VERSION "eCMPilot HS1 database-first 2026-10-28; PSA-RE 67f7581e7622410efdbb29c7eda3b86982b9b450; Apache-2.0"

NS_ :

BS_:

BU_: AAS ABS ARTIV AVAS BCP BSI BSM BVA CAV CMM CSS CVM DAE DMTR ESM E_VCU HCU1 HCU2 LVNSD MCM MDS RBG SBW VCU

BO_ 1293 ABS_BrakeAbrStatus: 8 ABS
 SG_ BrakeEcuFrame5Checksum : 59|4@0+ (1,0) [0|15] ""  AAS,CVM,DAE,CMM,BVA,BSI,HCU1,BSM,VCU,E_VCU
 SG_ ProcessCounter50d : 63|4@0+ (1,0) [0|15] ""  AAS,CVM,DAE,CMM,BVA,BSI,HCU1,BSM,VCU,E_VCU
 SG_ EspDisconnectRequest : 48|1@0+ (1,0) [0|1] ""  AAS,CVM,DAE,CMM,BVA,BSI,HCU1,BSM,VCU,E_VCU
 SG_ BrakeAssistFaultLampRequest : 49|1@0+ (1,0) [0|1] ""  AAS,CVM,DAE,CMM,BVA,BSI,HCU1,BSM,VCU,E_VCU
 SG_ StaticSlopeState : 51|2@0+ (1,0) [0|3] ""  AAS,CVM,DAE,CMM,BVA,BSI,HCU1,BSM,VCU,E_VCU
 SG_ BrakeFunctionNeedForStartStop : 53|2@0+ (1,0) [0|3] ""  AAS,CVM,DAE,CMM,BVA,BSI,HCU1,BSM,VCU,E_VCU
 SG_ BrakeEcuPowerManagementFault : 54|1@0+ (1,0) [0|1] ""  AAS,CVM,DAE,CMM,BVA,BSI,HCU1,BSM,VCU,E_VCU
 SG_ EmergencyBrakingSignaliza_517ee3 : 55|1@0+ (1,0) [0|1] ""  AAS,CVM,DAE,CMM,BVA,BSI,HCU1,BSM,VCU,E_VCU
 SG_ BrakeEcuSupplyVoltage : 47|8@0+ (0.05,7) [7|18.5] "V"  AAS,CVM,DAE,CMM,BVA,BSI,HCU1,BSM,VCU,E_VCU
 SG_ RearRightWheelSpinCounter : 30|15@0+ (1,0) [0|32767] ""  AAS,CVM,DAE,CMM,BVA,BSI,HCU1,BSM,VCU,E_VCU
 SG_ RearRightWheelSpeedSensorFault : 31|1@0+ (1,0) [0|1] ""  AAS,CVM,DAE,CMM,BVA,BSI,HCU1,BSM,VCU,E_VCU
 SG_ RearLeftWheelSpinCounter : 14|15@0+ (1,0) [0|32767] ""  AAS,CVM,DAE,CMM,BVA,BSI,HCU1,BSM,VCU,E_VCU
 SG_ RearLeftWheelSpeedSensorFault : 15|1@0+ (1,0) [0|1] ""  AAS,CVM,DAE,CMM,BVA,BSI,HCU1,BSM,VCU,E_VCU
 SG_ AbsFaultLampRequest : 0|1@0+ (1,0) [0|1] ""  AAS,CVM,DAE,CMM,BVA,BSI,HCU1,BSM,VCU,E_VCU
 SG_ BrakeFluidLevelAlert : 1|1@0+ (1,0) [0|1] ""  AAS,CVM,DAE,CMM,BVA,BSI,HCU1,BSM,VCU,E_VCU
 SG_ WornBrakePadsIndicator : 2|1@0+ (1,0) [0|1] ""  AAS,CVM,DAE,CMM,BVA,BSI,HCU1,BSM,VCU,E_VCU
 SG_ RefInProgress : 3|1@0+ (1,0) [0|1] ""  AAS,CVM,DAE,CMM,BVA,BSI,HCU1,BSM,VCU,E_VCU
 SG_ AutomaticHazardLightsByUcBrake : 4|1@0+ (1,0) [0|1] ""  AAS,CVM,DAE,CMM,BVA,BSI,HCU1,BSM,VCU,E_VCU
 SG_ AbsInProgress : 5|1@0+ (1,0) [0|1] ""  AAS,CVM,DAE,CMM,BVA,BSI,HCU1,BSM,VCU,E_VCU
 SG_ Unused1 : 6|1@0+ (1,0) [0|1] ""  AAS,CVM,DAE,CMM,BVA,BSI,HCU1,BSM,VCU,E_VCU
 SG_ RefFaultLamp : 7|1@0+ (1,0) [0|1] ""  AAS,CVM,DAE,CMM,BVA,BSI,HCU1,BSM,VCU,E_VCU

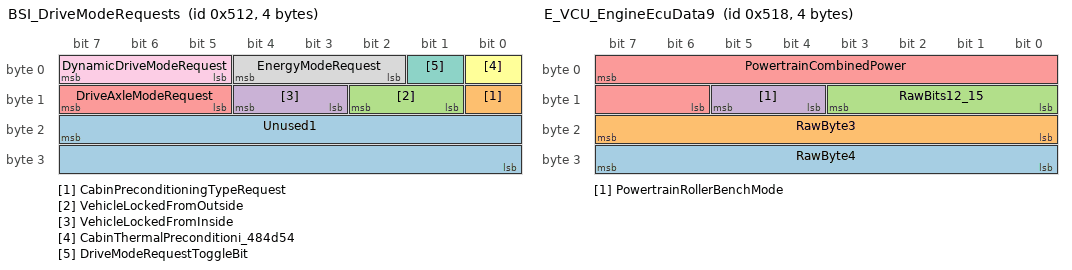
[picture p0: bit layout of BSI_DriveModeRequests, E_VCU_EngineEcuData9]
BO_ 1298 BSI_DriveModeRequests: 4 BSI
 SG_ Unused1 : 23|16@0+ (1,0) [0|65535] ""  VCU,E_VCU
 SG_ CabinPreconditioningTypeRequest : 8|1@0+ (1,0) [0|1] ""  VCU,E_VCU
 SG_ VehicleLockedFromOutside : 10|2@0+ (1,0) [0|3] ""  VCU,E_VCU
 SG_ VehicleLockedFromInside : 12|2@0+ (1,0) [0|3] ""  VCU,E_VCU
 SG_ DriveAxleModeRequest : 15|3@0+ (1,0) [0|7] ""  VCU,E_VCU
 SG_ CabinThermalPreconditioni_484d54 : 0|1@0+ (1,0) [0|1] ""  VCU,E_VCU
 SG_ DriveModeRequestToggleBit : 1|1@0+ (1,0) [0|1] ""  VCU,E_VCU
 SG_ EnergyModeRequest : 4|3@0+ (1,0) [0|7] ""  VCU,E_VCU
 SG_ DynamicDriveModeRequest : 7|3@0+ (1,0) [0|7] ""  VCU,E_VCU

BO_ 1304 E_VCU_EngineEcuData9: 4 E_VCU
 SG_ RawByte4 : 31|8@0+ (1,0) [0|255] "raw"  BSI
 SG_ RawByte3 : 23|8@0+ (1,0) [0|255] "raw"  BSI
 SG_ RawBits12_15 : 11|4@0+ (1,0) [0|15] "raw"  BSI
 SG_ PowertrainRollerBenchMode : 13|2@0+ (1,0) [0|3] ""  BSI
 SG_ PowertrainCombinedPower : 7|10@0+ (500,-255000) [-255000|255000] "W"  BSI

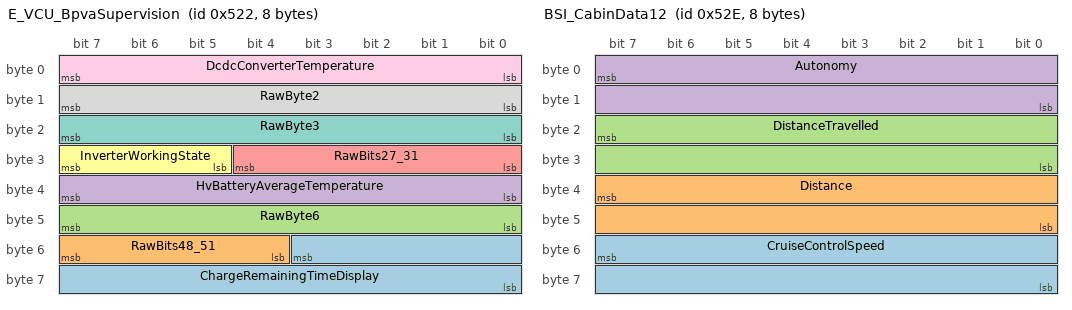
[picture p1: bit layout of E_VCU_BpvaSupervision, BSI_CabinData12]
BO_ 1314 E_VCU_BpvaSupervision: 8 E_VCU
 SG_ ChargeRemainingTimeDisplay : 51|12@0+ (1,0) [0|4093] "min"  BSI,MDS
 SG_ RawBits48_51 : 55|4@0+ (1,0) [0|15] "raw"  BSI,MDS
 SG_ RawByte6 : 47|8@0+ (1,0) [0|255] "raw"  BSI,MDS
 SG_ HvBatteryAverageTemperature : 39|8@0+ (1,-40) [-40|210] "degC"  BSI,MDS
 SG_ RawBits27_31 : 28|5@0+ (1,0) [0|31] "raw"  BSI,MDS
 SG_ InverterWorkingState : 31|3@0+ (1,0) [0|7] ""  BSI,MDS
 SG_ RawByte3 : 23|8@0+ (1,0) [0|255] "raw"  BSI,MDS
 SG_ RawByte2 : 15|8@0+ (1,0) [0|255] "raw"  BSI,MDS
 SG_ DcdcConverterTemperature : 7|8@0+ (1,-40) [-40|214] "degC"  BSI,MDS

BO_ 1326 BSI_CabinData12: 8 BSI
 SG_ CruiseControlSpeed : 55|16@0+ (0.01,0) [0|254] "km/h" Vector__XXX
 SG_ Distance : 39|16@0+ (20,0) [0|140000] "km" Vector__XXX
 SG_ DistanceTravelled : 23|16@0+ (0.1,0) [0|6553.5] "m" Vector__XXX
 SG_ Autonomy : 7|16@0+ (1,0) [0|2000] "km" Vector__XXX

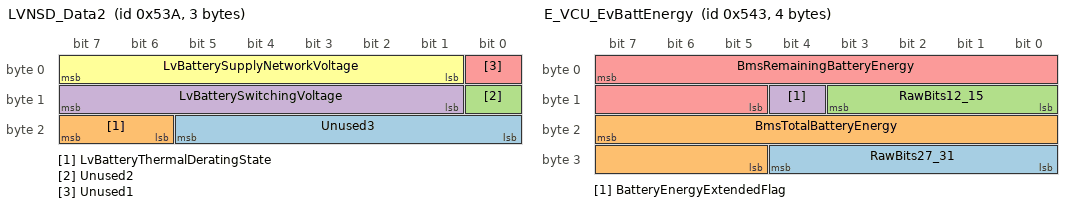
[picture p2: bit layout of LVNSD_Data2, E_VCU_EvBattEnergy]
BO_ 1338 LVNSD_Data2: 3 LVNSD
 SG_ Unused3 : 21|6@0+ (1,0) [0|63] ""  CMM
 SG_ LvBatteryThermalDeratingState : 23|2@0+ (1,0) [0|3] ""  CMM
 SG_ Unused2 : 8|1@0+ (1,0) [0|1] ""  CMM
 SG_ LvBatterySwitchingVoltage : 15|7@0+ (0.1,0) [5.4|18] "V"  CMM
 SG_ Unused1 : 0|1@0+ (1,0) [0|1] ""  CMM
 SG_ LvBatterySupplyNetworkVoltage : 7|7@0+ (0.1,0) [5.4|18] "V"  CMM

BO_ 1347 E_VCU_EvBattEnergy: 4 E_VCU
 SG_ RawBits27_31 : 28|5@0+ (1,0) [0|31] "raw"  MDS,BSI
 SG_ BmsTotalBatteryEnergy : 23|11@0+ (32,0) [0|65440] "Wh"  MDS,BSI
 SG_ RawBits12_15 : 11|4@0+ (1,0) [0|15] "raw"  MDS,BSI
 SG_ BatteryEnergyExtendedFlag : 12|1@0+ (1,0) [0|1] ""  MDS,BSI
 SG_ BmsRemainingBatteryEnergy : 7|11@0+ (32,0) [0|65440] "Wh"  MDS,BSI

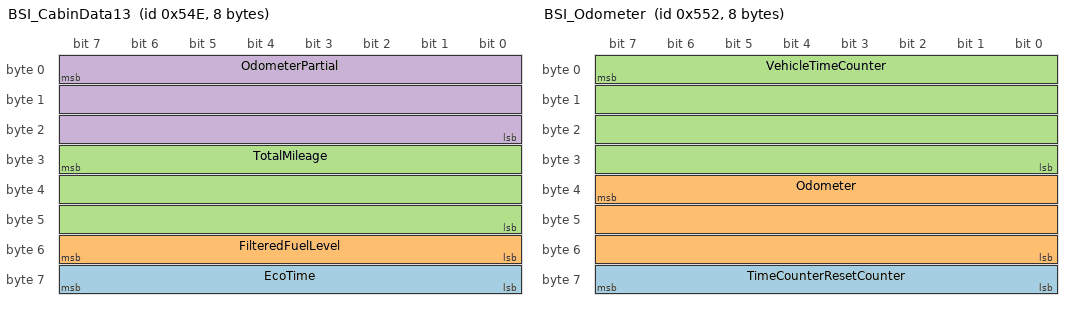
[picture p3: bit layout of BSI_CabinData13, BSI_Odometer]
BO_ 1358 BSI_CabinData13: 8 BSI
 SG_ EcoTime : 63|8@0+ (1,0) [0|100] "%"  CMM,VCU
 SG_ FilteredFuelLevel : 55|8@0+ (1,0) [0|100] "%"  CMM,VCU
 SG_ TotalMileage : 31|24@0+ (0.1,0) [0|1677721.4] "km"  CMM,VCU
 SG_ OdometerPartial : 7|24@0+ (0.001,0) [0|16777.214] "km"  CMM,VCU

BO_ 1362 BSI_Odometer: 8 BSI
 SG_ TimeCounterResetCounter : 63|8@0+ (1,0) [0|253] ""  ESM,BCP,VCU,HCU1,DAE,SBW,CMM,ABS,CSS,BVA,CVM,LVNSD,E_VCU
 SG_ Odometer : 39|24@0+ (1,0) [0|16777214] "km"  ESM,BCP,VCU,HCU1,DAE,SBW,CMM,ABS,CSS,BVA,CVM,LVNSD,E_VCU
 SG_ VehicleTimeCounter : 7|32@0+ (0.1,0) [0|429496729.3] "s"  ESM,BCP,VCU,HCU1,DAE,SBW,CMM,ABS,CSS,BVA,CVM,LVNSD,E_VCU

BO_ 1370 LVNSD_Data3: 7 LVNSD
 SG_ BatteryResistanceSeq3 : 40|9@0+ (0.1,0) [0|35] "mOhm"  CMM
 SG_ BatteryVoltageSeq3 : 47|7@0+ (0.1,0) [5.4|18] "V"  CMM
 SG_ BatteryResistanceSeq2 : 24|9@0+ (0.1,0) [0|35] "mOhm"  CMM
 SG_ BatteryVoltageSeq2 : 31|7@0+ (0.1,0) [5.4|18] "V"  CMM
 SG_ BatteryResistanceSeq4 m1 : 8|9@0+ (0.1,0) [0|35] "mOhm"  CMM
 SG_ BatteryResistanceSeq1 m0 : 8|9@0+ (0.1,0) [0|35] "mOhm"  CMM
 SG_ BatteryVoltageSeq4 m1 : 15|7@0+ (0.1,0) [5.4|18] "V"  CMM
 SG_ BatteryVoltageSeq1 m0 : 15|7@0+ (0.1,0) [5.4|18] "V"  CMM
 SG_ Unused1 : 6|7@0+ (1,0) [0|127] ""  CMM
 SG_ LvBatterySequenceId M : 7|1@0+ (1,0) [0|1] ""  CMM

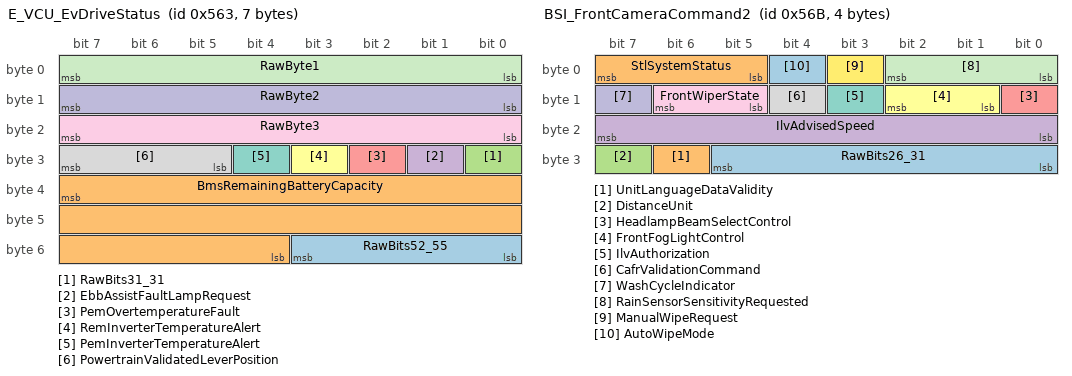
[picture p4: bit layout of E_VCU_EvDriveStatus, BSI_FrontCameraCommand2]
BO_ 1379 E_VCU_EvDriveStatus: 7 E_VCU
 SG_ RawBits52_55 : 51|4@0+ (1,0) [0|15] "raw"  MDS,BSI,RBG
 SG_ BmsRemainingBatteryCapacity : 39|20@0+ (0.001,0) [0|200] "Ah"  MDS,BSI,RBG
 SG_ RawBits31_31 : 24|1@0+ (1,0) [0|1] "raw"  MDS,BSI,RBG
 SG_ EbbAssistFaultLampRequest : 25|1@0+ (1,0) [0|1] ""  MDS,BSI,RBG
 SG_ PemOvertemperatureFault : 26|1@0+ (1,0) [0|1] ""  MDS,BSI,RBG
 SG_ RemInverterTemperatureAlert : 27|1@0+ (1,0) [0|1] ""  MDS,BSI,RBG
 SG_ PemInverterTemperatureAlert : 28|1@0+ (1,0) [0|1] ""  MDS,BSI,RBG
 SG_ PowertrainValidatedLeverPosition : 31|3@0+ (1,0) [0|7] ""  MDS,BSI,RBG
 SG_ RawByte3 : 23|8@0+ (1,0) [0|255] "raw"  MDS,BSI,RBG
 SG_ RawByte2 : 15|8@0+ (1,0) [0|255] "raw"  MDS,BSI,RBG
 SG_ RawByte1 : 7|8@0+ (1,0) [0|255] "raw"  MDS,BSI,RBG

BO_ 1387 BSI_FrontCameraCommand2: 4 BSI
 SG_ RawBits26_31 : 29|6@0+ (1,0) [0|63] "raw"  CVM
 SG_ UnitLanguageDataValidity : 30|1@0+ (1,0) [0|1] ""  CVM
 SG_ DistanceUnit : 31|1@0+ (1,0) [0|1] ""  CVM
 SG_ IlvAdvisedSpeed : 23|8@0+ (1,0) [0|199] "km/h"  CVM
 SG_ HeadlampBeamSelectControl : 8|1@0+ (1,0) [0|1] ""  CVM
 SG_ FrontFogLightControl : 10|2@0+ (1,0) [0|3] ""  CVM
 SG_ IlvAuthorization : 11|1@0+ (1,0) [0|1] ""  CVM
 SG_ CafrValidationCommand : 12|1@0+ (1,0) [0|1] ""  CVM
 SG_ FrontWiperState : 14|2@0+ (1,0) [0|3] ""  CVM
 SG_ WashCycleIndicator : 15|1@0+ (1,0) [0|1] ""  CVM
 SG_ RainSensorSensitivityRequested : 2|3@0+ (1,0) [0|7] ""  CVM
 SG_ ManualWipeRequest : 3|1@0+ (1,0) [0|1] ""  CVM
 SG_ AutoWipeMode : 4|1@0+ (1,0) [0|1] ""  CVM
 SG_ StlSystemStatus : 7|3@0+ (1,0) [0|7] ""  CVM

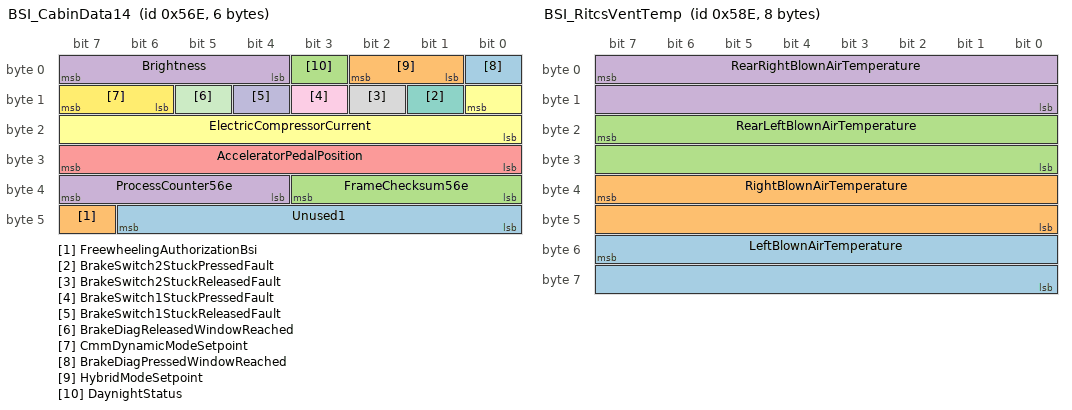
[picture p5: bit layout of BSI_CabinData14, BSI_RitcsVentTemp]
BO_ 1390 BSI_CabinData14: 6 BSI
 SG_ Unused1 : 46|7@0+ (1,0) [0|127] ""  E_VCU,BVA,HCU1,CMM,ESM,AAS,VCU
 SG_ FreewheelingAuthorizationBsi : 47|1@0+ (1,0) [0|1] ""  E_VCU,BVA,HCU1,CMM,ESM,AAS,VCU
 SG_ FrameChecksum56e : 35|4@0+ (1,0) [0|15] ""  E_VCU,BVA,HCU1,CMM,ESM,AAS,VCU
 SG_ ProcessCounter56e : 39|4@0+ (1,0) [0|15] ""  E_VCU,BVA,HCU1,CMM,ESM,AAS,VCU
 SG_ AcceleratorPedalPosition : 31|8@0+ (0.5,0) [0|100] "%"  E_VCU,BVA,HCU1,CMM,ESM,AAS,VCU
 SG_ ElectricCompressorCurrent : 8|9@0+ (0.1,0) [0|50] "A"  E_VCU,BVA,HCU1,CMM,ESM,AAS,VCU
 SG_ BrakeSwitch2StuckPressedFault : 9|1@0+ (1,0) [0|1] ""  E_VCU,BVA,HCU1,CMM,ESM,AAS,VCU
 SG_ BrakeSwitch2StuckReleasedFault : 10|1@0+ (1,0) [0|1] ""  E_VCU,BVA,HCU1,CMM,ESM,AAS,VCU
 SG_ BrakeSwitch1StuckPressedFault : 11|1@0+ (1,0) [0|1] ""  E_VCU,BVA,HCU1,CMM,ESM,AAS,VCU
 SG_ BrakeSwitch1StuckReleasedFault : 12|1@0+ (1,0) [0|1] ""  E_VCU,BVA,HCU1,CMM,ESM,AAS,VCU
 SG_ BrakeDiagReleasedWindowReached : 13|1@0+ (1,0) [0|1] ""  E_VCU,BVA,HCU1,CMM,ESM,AAS,VCU
 SG_ CmmDynamicModeSetpoint : 15|2@0+ (1,0) [0|3] ""  E_VCU,BVA,HCU1,CMM,ESM,AAS,VCU
 SG_ BrakeDiagPressedWindowReached : 0|1@0+ (1,0) [0|1] ""  E_VCU,BVA,HCU1,CMM,ESM,AAS,VCU
 SG_ HybridModeSetpoint : 2|2@0+ (1,0) [0|3] ""  E_VCU,BVA,HCU1,CMM,ESM,AAS,VCU
 SG_ DaynightStatus : 3|1@0+ (1,0) [0|1] ""  E_VCU,BVA,HCU1,CMM,ESM,AAS,VCU
 SG_ Brightness : 7|4@0+ (1,0) [0|15] ""  E_VCU,BVA,HCU1,CMM,ESM,AAS,VCU

BO_ 1394 BSI_CabinData15: 8 BSI
 SG_ DmtrBatteryCurrent : 63|8@0+ (0.5,0) [0|100] "A"  AAS,BCP,CVM,BVA,DMTR,BSM,CMM,ABS
 SG_ GeiNeedsGroup3 : 55|8@0+ (1,0) [0|255] ""  AAS,BCP,CVM,BVA,DMTR,BSM,CMM,ABS
 SG_ GeiNeedsGroup2 : 47|8@0+ (1,0) [0|255] ""  AAS,BCP,CVM,BVA,DMTR,BSM,CMM,ABS
 SG_ GeiNeedsGroup1 : 39|8@0+ (1,0) [0|255] ""  AAS,BCP,CVM,BVA,DMTR,BSM,CMM,ABS
 SG_ Unused1 : 24|1@0+ (1,0) [0|1] ""  AAS,BCP,CVM,BVA,DMTR,BSM,CMM,ABS
 SG_ AfsFunctionState : 28|4@0+ (1,0) [0|15] ""  AAS,BCP,CVM,BVA,DMTR,BSM,CMM,ABS
 SG_ BatteryRestartPredictedVoltage : 23|11@0+ (0.01,0) [0|13] "V"  AAS,BCP,CVM,BVA,DMTR,BSM,CMM,ABS
 SG_ EngineStopImpactScreenInhibit : 8|1@0+ (1,0) [0|1] ""  AAS,BCP,CVM,BVA,DMTR,BSM,CMM,ABS
 SG_ StubbedSignal1 : 9|1@0+ (1,0) [0|1] ""  AAS,BCP,CVM,BVA,DMTR,BSM,CMM,ABS
 SG_ BatteryVoltageSensorFault : 10|1@0+ (1,0) [0|1] ""  AAS,BCP,CVM,BVA,DMTR,BSM,CMM,ABS
 SG_ BatteryTemperatureCalcFault : 11|1@0+ (1,0) [0|1] ""  AAS,BCP,CVM,BVA,DMTR,BSM,CMM,ABS
 SG_ BatteryCurrentSensorFault : 12|1@0+ (1,0) [0|1] ""  AAS,BCP,CVM,BVA,DMTR,BSM,CMM,ABS
 SG_ VehicleConfigurationState : 15|3@0+ (1,0) [0|7] ""  AAS,BCP,CVM,BVA,DMTR,BSM,CMM,ABS
 SG_ PassengerAirbagInhibitionStatus : 0|1@0+ (1,0) [0|1] ""  AAS,BCP,CVM,BVA,DMTR,BSM,CMM,ABS
 SG_ ReverseStatus : 1|1@0+ (1,0) [0|1] ""  AAS,BCP,CVM,BVA,DMTR,BSM,CMM,ABS
 SG_ PowertrainStateCabinSide : 3|2@0+ (1,0) [0|3] ""  AAS,BCP,CVM,BVA,DMTR,BSM,CMM,ABS
 SG_ BeltBucklePassenger : 5|2@0+ (1,0) [0|3] ""  AAS,BCP,CVM,BVA,DMTR,BSM,CMM,ABS
 SG_ BeltBuckleDriver : 7|2@0+ (1,0) [0|3] ""  AAS,BCP,CVM,BVA,DMTR,BSM,CMM,ABS

BO_ 1411 E_VCU_EvBattAlerts: 7 E_VCU
 SG_ HvBatteryVoltageProbeCount : 55|8@0+ (1,0) [0|250] ""  MDS,BSI
 SG_ HvBatteryTemperatureProbeCount : 47|8@0+ (1,0) [0|250] ""  MDS,BSI
 SG_ RawBits38_39 : 33|2@0+ (1,0) [0|3] "raw"  MDS,BSI
 SG_ HvBatteryContactorUncomma_ee926c : 36|3@0+ (1,0) [0|7] ""  MDS,BSI
 SG_ HvBatteryOverchargeAlert : 37|1@0+ (1,0) [0|1] ""  MDS,BSI
 SG_ HvBatteryCellConsistencyAlert : 38|1@0+ (1,0) [0|1] ""  MDS,BSI
 SG_ HvBatterySocJumpAlert : 39|1@0+ (1,0) [0|1] ""  MDS,BSI
 SG_ HvBatteryCellUndervoltageAlert : 24|1@0+ (1,0) [0|1] ""  MDS,BSI
 SG_ HvBatteryCellOvervoltageAlert : 25|1@0+ (1,0) [0|1] ""  MDS,BSI
 SG_ HvBatteryHighSocAlert : 26|1@0+ (1,0) [0|1] ""  MDS,BSI
 SG_ HvBatteryLowSocAlert : 27|1@0+ (1,0) [0|1] ""  MDS,BSI
 SG_ HvBatteryOvervoltageAlert : 28|1@0+ (1,0) [0|1] ""  MDS,BSI
 SG_ HvBatteryHighTemperatureAlert : 29|1@0+ (1,0) [0|1] ""  MDS,BSI
 SG_ HvBatteryTemperatureDiffe_70ad26 : 30|1@0+ (1,0) [0|1] ""  MDS,BSI
 SG_ HvBatteryInconsistentAlert : 31|1@0+ (1,0) [0|1] ""  MDS,BSI
 SG_ HvBatteryTemperatureMin : 23|8@0+ (1,-40) [-40|210] "degC"  MDS,BSI
 SG_ HvBatteryProbeNumberTempMin : 15|8@0+ (11,0) [1|250] ""  MDS,BSI
 SG_ HvBatteryProbeNumberTempMax : 7|8@0+ (11,0) [1|250] ""  MDS,BSI

BO_ 1416 CMM_EngineData: 8 CMM
 SG_ LifeSituation : 58|3@0+ (1,0) [0|7] ""  ABS,BVA,BSI,HCU1
 SG_ GearChangeDirection : 60|2@0+ (1,0) [0|3] ""  ABS,BVA,BSI,HCU1
 SG_ GearboxTargetRatioTransmitted : 63|3@0+ (1,0) [0|7] ""  ABS,BVA,BSI,HCU1
 SG_ EngineOperatingMode : 51|4@0+ (1,0) [0|15] ""  ABS,BVA,BSI,HCU1
 SG_ AdditivePumpControlEnabled : 52|1@0+ (1,0) [0|1] ""  ABS,BVA,BSI,HCU1
 SG_ DmtcChargeState : 53|1@0+ (1,0) [0|1] ""  ABS,BVA,BSI,HCU1
 SG_ DeferredStopSyncInfo : 54|1@0+ (1,0) [0|1] ""  ABS,BVA,BSI,HCU1
 SG_ CmmReadinessCodeStatus : 55|1@0+ (1,0) [0|1] ""  ABS,BVA,BSI,HCU1
 SG_ StopStartFunctionState : 41|2@0+ (1,0) [0|3] ""  ABS,BVA,BSI,HCU1
 SG_ AtmosphericPressure : 46|5@0+ (15,685) [685|1120] "hPa"  ABS,BVA,BSI,HCU1
 SG_ EcmSafetyFault : 47|1@0+ (1,0) [0|1] ""  ABS,BVA,BSI,HCU1
 SG_ CalculatedEngineLoad : 39|8@0+ (0.39216,0) [0|100] "%"  ABS,BVA,BSI,HCU1
 SG_ PseudoFuelConsumption : 31|8@0+ (80,0) [0|20400] "mm3"  ABS,BVA,BSI,HCU1
 SG_ OilPressureAlertLamp : 16|1@0+ (1,0) [0|1] ""  ABS,BVA,BSI,HCU1
 SG_ NeutralDisplayRequestGsi : 17|1@0+ (1,0) [0|1] ""  ABS,BVA,BSI,HCU1
 SG_ ValvetronicPowerCommand : 18|1@0+ (1,0) [0|1] ""  ABS,BVA,BSI,HCU1
 SG_ WaterPumpState : 19|1@0+ (1,0) [0|1] ""  ABS,BVA,BSI,HCU1
 SG_ RedLedRequest : 20|1@0+ (1,0) [0|1] ""  ABS,BVA,BSI,HCU1
 SG_ OrangeLedRequest : 21|1@0+ (1,0) [0|1] ""  ABS,BVA,BSI,HCU1
 SG_ ClutchDisplayRequest : 22|1@0+ (1,0) [0|1] ""  ABS,BVA,BSI,HCU1
 SG_ StopStartAvailableBlinkRequest : 23|1@0+ (1,0) [0|1] ""  ABS,BVA,BSI,HCU1
 SG_ AdditiveVolumeToAdd : 15|8@0+ (5,0) [0|1265] "mm3"  ABS,BVA,BSI,HCU1
 SG_ EngineOilLevel : 7|8@0+ (3,0) [0|750] "mV"  ABS,BVA,BSI,HCU1

BO_ 1422 BSI_RitcsVentTemp: 8 BSI
 SG_ LeftBlownAirTemperature : 55|16@0+ (0.1,-40) [-40|85] "degC" Vector__XXX
 SG_ RightBlownAirTemperature : 39|16@0+ (0.1,-40) [-40|85] "degC" Vector__XXX
 SG_ RearLeftBlownAirTemperature : 23|16@0+ (0.1,-40) [-40|85] "degC" Vector__XXX
 SG_ RearRightBlownAirTemperature : 7|16@0+ (0.1,-40) [-40|85] "degC" Vector__XXX

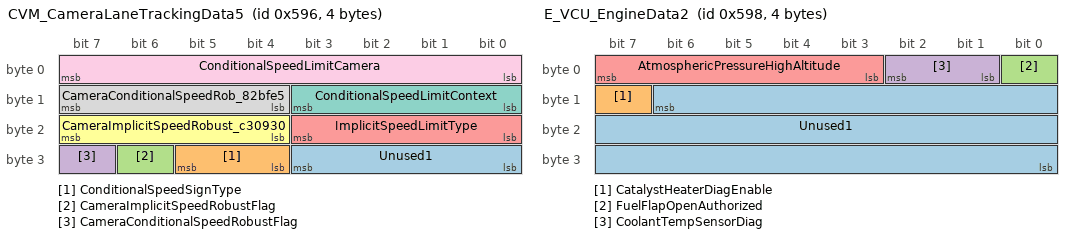
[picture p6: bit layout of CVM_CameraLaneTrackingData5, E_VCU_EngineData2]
BO_ 1430 CVM_CameraLaneTrackingData5: 4 CVM
 SG_ Unused1 : 27|4@0+ (1,0) [0|15] ""  BSI
 SG_ ConditionalSpeedSignType : 29|2@0+ (1,0) [0|3] ""  BSI
 SG_ CameraImplicitSpeedRobustFlag : 30|1@0+ (1,0) [0|1] ""  BSI
 SG_ CameraConditionalSpeedRobustFlag : 31|1@0+ (1,0) [0|1] ""  BSI
 SG_ ImplicitSpeedLimitType : 19|4@0+ (1,0) [0|15] ""  BSI
 SG_ CameraImplicitSpeedRobust_c30930 : 23|4@0+ (20,0) [0|260] "m"  BSI
 SG_ ConditionalSpeedLimitContext : 11|4@0+ (1,0) [0|15] ""  BSI
 SG_ CameraConditionalSpeedRob_82bfe5 : 15|4@0+ (20,0) [0|260] "m"  BSI
 SG_ ConditionalSpeedLimitCamera : 7|8@0+ (1,0) [0|255] "km/h"  BSI

BO_ 1432 E_VCU_EngineData2: 4 E_VCU
 SG_ Unused1 : 14|23@0+ (1,0) [0|8388607] ""  ABS,BVA,BSI,HCU1,MDS
 SG_ CatalystHeaterDiagEnable : 15|1@0+ (1,0) [0|1] ""  ABS,BVA,BSI,HCU1,MDS
 SG_ FuelFlapOpenAuthorized : 0|1@0+ (1,0) [0|1] ""  ABS,BVA,BSI,HCU1,MDS
 SG_ CoolantTempSensorDiag : 2|2@0+ (1,0) [0|3] ""  ABS,BVA,BSI,HCU1,MDS
 SG_ AtmosphericPressureHighAltitude : 7|5@0+ (20,685) [540|1120] "hPa"  ABS,BVA,BSI,HCU1,MDS

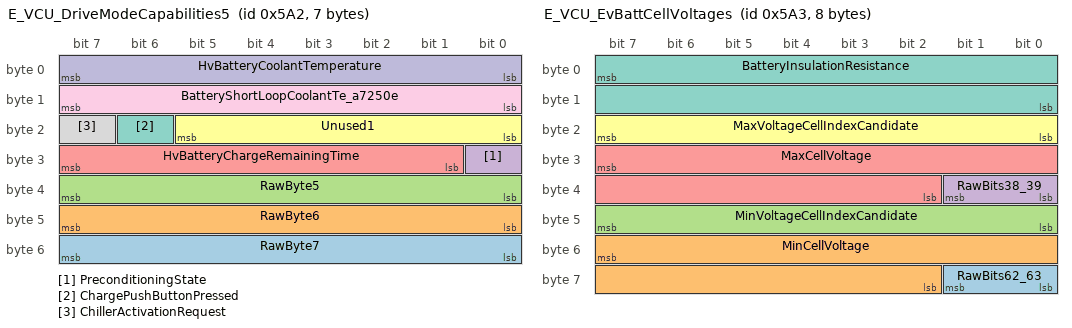
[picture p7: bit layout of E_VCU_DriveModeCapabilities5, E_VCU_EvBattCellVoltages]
BO_ 1442 E_VCU_DriveModeCapabilities5: 7 E_VCU
 SG_ RawByte7 : 55|8@0+ (1,0) [0|255] "raw"  BSI,MDS
 SG_ RawByte6 : 47|8@0+ (1,0) [0|255] "raw"  BSI,MDS
 SG_ RawByte5 : 39|8@0+ (1,0) [0|255] "raw"  BSI,MDS
 SG_ PreconditioningState : 24|1@0+ (1,0) [0|1] ""  BSI,MDS
 SG_ HvBatteryChargeRemainingTime : 31|7@0+ (300,0) [0|37800] "s"  BSI,MDS
 SG_ Unused1 : 21|6@0+ (1,0) [0|63] ""  BSI,MDS
 SG_ ChargePushButtonPressed : 22|1@0+ (1,0) [0|1] ""  BSI,MDS
 SG_ ChillerActivationRequest : 23|1@0+ (1,0) [0|1] ""  BSI,MDS
 SG_ BatteryShortLoopCoolantTe_a7250e : 15|8@0+ (1,-40) [-40|200] "degC"  BSI,MDS
 SG_ HvBatteryCoolantTemperature : 7|8@0+ (1,-40) [-40|214] "degC"  BSI,MDS

BO_ 1443 E_VCU_EvBattCellVoltages: 8 E_VCU
 SG_ RawBits62_63 : 57|2@0+ (1,0) [0|3] "raw"  MDS,BSI
 SG_ MinCellVoltage : 55|14@0+ (0.001,0) [0|15] "V"  MDS,BSI
 SG_ MinVoltageCellIndexCandidate : 47|8@0+ (1,0) [1|108] ""  MDS,BSI
 SG_ RawBits38_39 : 33|2@0+ (1,0) [0|3] "raw"  MDS,BSI
 SG_ MaxCellVoltage : 31|14@0+ (0.001,0) [0|15] "V"  MDS,BSI
 SG_ MaxVoltageCellIndexCandidate : 23|8@0+ (1,0) [1|108] ""  MDS,BSI
 SG_ BatteryInsulationResistance : 7|16@0+ (1,0) [0|60000] "kOhm"  MDS,BSI

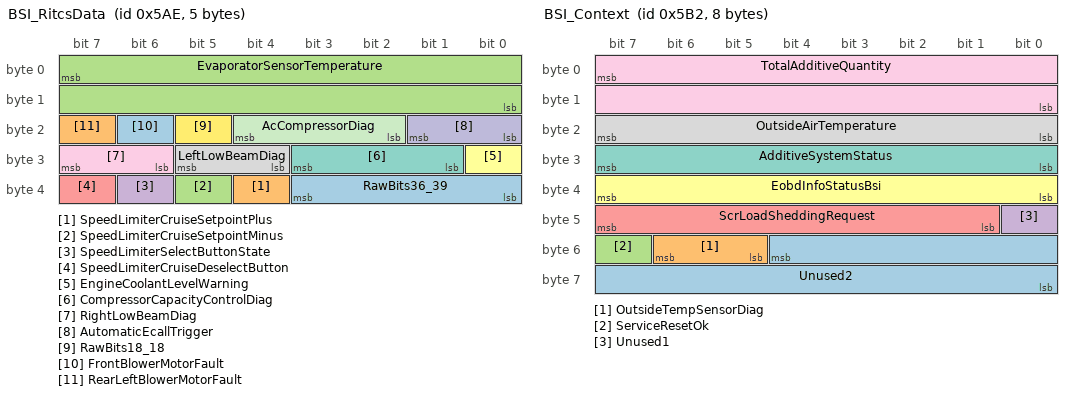
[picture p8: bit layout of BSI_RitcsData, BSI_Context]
BO_ 1454 BSI_RitcsData: 5 BSI
 SG_ RawBits36_39 : 35|4@0+ (1,0) [0|15] "raw" Vector__XXX
 SG_ SpeedLimiterCruiseSetpointPlus : 36|1@0+ (1,0) [0|1] "" Vector__XXX
 SG_ SpeedLimiterCruiseSetpointMinus : 37|1@0+ (1,0) [0|1] "" Vector__XXX
 SG_ SpeedLimiterSelectButtonState : 38|1@0+ (1,0) [0|1] "" Vector__XXX
 SG_ SpeedLimiterCruiseDeselectButton : 39|1@0+ (1,0) [0|1] "" Vector__XXX
 SG_ EngineCoolantLevelWarning : 24|1@0+ (1,0) [0|1] "" Vector__XXX
 SG_ CompressorCapacityControlDiag : 27|3@0+ (1,0) [0|7] "" Vector__XXX
 SG_ LeftLowBeamDiag : 29|2@0+ (1,0) [0|3] "" Vector__XXX
 SG_ RightLowBeamDiag : 31|2@0+ (1,0) [0|3] "" Vector__XXX
 SG_ AutomaticEcallTrigger : 17|2@0+ (1,0) [0|3] "" Vector__XXX
 SG_ AcCompressorDiag : 20|3@0+ (1,0) [0|7] "" Vector__XXX
 SG_ RawBits18_18 : 21|1@0+ (1,0) [0|1] "raw" Vector__XXX
 SG_ FrontBlowerMotorFault : 22|1@0+ (1,0) [0|1] "" Vector__XXX
 SG_ RearLeftBlowerMotorFault : 23|1@0+ (1,0) [0|1] "" Vector__XXX
 SG_ EvaporatorSensorTemperature : 7|16@0+ (0.1,-40) [-40|85] "degC" Vector__XXX

BO_ 1458 BSI_Context: 8 BSI
 SG_ Unused2 : 52|13@0+ (1,0) [0|8191] ""  VCU,CVM,CSS,ABS,CMM,BVA,HCU1,E_VCU,BSM
 SG_ OutsideTempSensorDiag : 54|2@0+ (1,0) [0|3] ""  VCU,CVM,CSS,ABS,CMM,BVA,HCU1,E_VCU,BSM
 SG_ ServiceResetOk : 55|1@0+ (1,0) [0|1] ""  VCU,CVM,CSS,ABS,CMM,BVA,HCU1,E_VCU,BSM
 SG_ Unused1 : 40|1@0+ (1,0) [0|1] ""  VCU,CVM,CSS,ABS,CMM,BVA,HCU1,E_VCU,BSM
 SG_ ScrLoadSheddingRequest : 47|7@0+ (1,0) [0|100] "%"  VCU,CVM,CSS,ABS,CMM,BVA,HCU1,E_VCU,BSM
 SG_ EobdInfoStatusBsi : 39|8@0+ (1,0) [0|255] ""  VCU,CVM,CSS,ABS,CMM,BVA,HCU1,E_VCU,BSM
 SG_ AdditiveSystemStatus : 31|8@0+ (1,0) [0|255] ""  VCU,CVM,CSS,ABS,CMM,BVA,HCU1,E_VCU,BSM
 SG_ OutsideAirTemperature : 23|8@0+ (0.5,-40) [-40|85] "degC"  VCU,CVM,CSS,ABS,CMM,BVA,HCU1,E_VCU,BSM
 SG_ TotalAdditiveQuantity : 7|16@0+ (0.05,0) [0|3276.5] "g"  VCU,CVM,CSS,ABS,CMM,BVA,HCU1,E_VCU,BSM

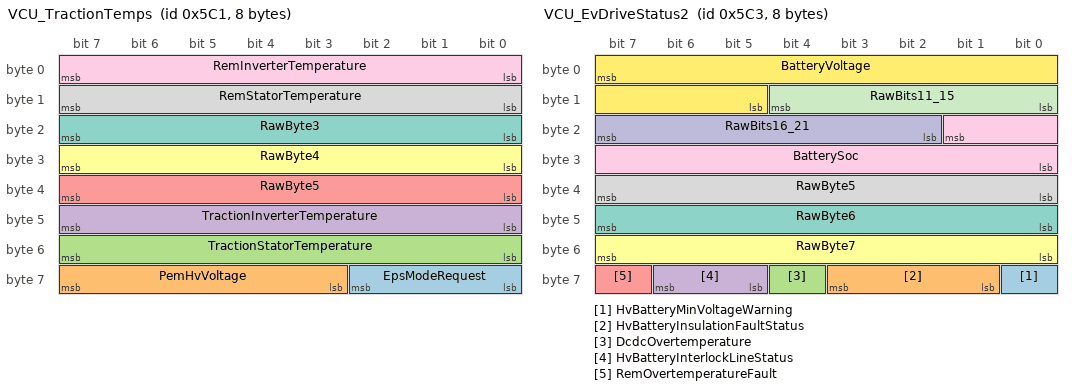
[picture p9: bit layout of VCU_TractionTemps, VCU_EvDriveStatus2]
BO_ 1473 VCU_TractionTemps: 8 VCU
 SG_ EpsModeRequest : 58|3@0+ (1,0) [0|7] ""  MDS,BSI
 SG_ PemHvVoltage : 63|5@0+ (20,0) [0|500] "V"  MDS,BSI
 SG_ TractionStatorTemperature : 55|8@0+ (1,-40) [-40|214] "degC"  MDS,BSI
 SG_ TractionInverterTemperature : 47|8@0+ (1,-40) [-40|214] "degC"  MDS,BSI
 SG_ RawByte5 : 39|8@0+ (1,0) [0|255] "raw"  MDS,BSI
 SG_ RawByte4 : 31|8@0+ (1,0) [0|255] "raw"  MDS,BSI
 SG_ RawByte3 : 23|8@0+ (1,0) [0|255] "raw"  MDS,BSI
 SG_ RemStatorTemperature : 15|8@0+ (1,-40) [-40|214] "degC"  MDS,BSI
 SG_ RemInverterTemperature : 7|8@0+ (1,-40) [-40|214] "degC"  MDS,BSI

BO_ 1475 VCU_EvDriveStatus2: 8 VCU
 SG_ HvBatteryMinVoltageWarning : 56|1@0+ (1,0) [0|1] ""  MDS,BSI
 SG_ HvBatteryInsulationFaultStatus : 59|3@0+ (1,0) [0|7] ""  MDS,BSI
 SG_ DcdcOvertemperature : 60|1@0+ (1,0) [0|1] ""  MDS,BSI
 SG_ HvBatteryInterlockLineStatus : 62|2@0+ (1,0) [0|3] ""  MDS,BSI
 SG_ RemOvertemperatureFault : 63|1@0+ (1,0) [0|1] ""  MDS,BSI
 SG_ RawByte7 : 55|8@0+ (1,0) [0|255] "raw"  MDS,BSI
 SG_ RawByte6 : 47|8@0+ (1,0) [0|255] "raw"  MDS,BSI
 SG_ RawByte5 : 39|8@0+ (1,0) [0|255] "raw"  MDS,BSI
 SG_ BatterySoc : 17|10@0+ (0.1,0) [0|100] "%"  MDS,BSI
 SG_ RawBits16_21 : 23|6@0+ (1,0) [0|63] "raw"  MDS,BSI
 SG_ RawBits11_15 : 12|5@0+ (1,0) [0|31] "raw"  MDS,BSI
 SG_ BatteryVoltage : 7|11@0+ (0.25,0) [0|500] "V"  MDS,BSI

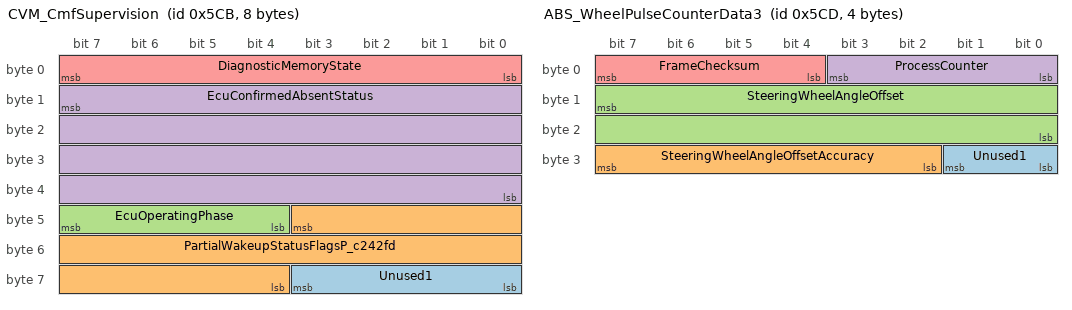
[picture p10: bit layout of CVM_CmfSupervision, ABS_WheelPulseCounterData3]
BO_ 1483 CVM_CmfSupervision: 8 CVM
 SG_ Unused1 : 59|4@0+ (1,0) [0|15] "" Vector__XXX
 SG_ PartialWakeupStatusFlagsP_c242fd : 43|16@0+ (1,0) [0|65535] "" Vector__XXX
 SG_ EcuOperatingPhase : 47|4@0+ (1,0) [0|15] "" Vector__XXX
 SG_ EcuConfirmedAbsentStatus : 15|32@0+ (1,0) [0|4294967295] "" Vector__XXX
 SG_ DiagnosticMemoryState : 7|8@0+ (1,0) [0|255] "" Vector__XXX

BO_ 1485 ABS_WheelPulseCounterData3: 4 ABS
 SG_ Unused1 : 25|2@0+ (1,0) [0|3] ""  DAE
 SG_ SteeringWheelAngleOffsetAccuracy : 31|6@0+ (1,0) [0|61] "°"  DAE
 SG_ SteeringWheelAngleOffset : 15|16@0- (0.1,0) [-1630|1630] "°"  DAE
 SG_ ProcessCounter : 3|4@0+ (1,0) [0|15] ""  DAE
 SG_ FrameChecksum : 7|4@0+ (1,0) [0|15] ""  DAE

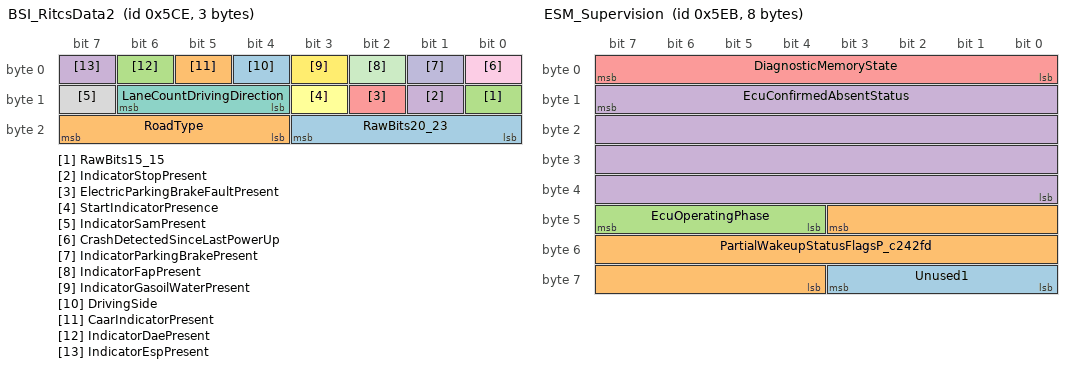
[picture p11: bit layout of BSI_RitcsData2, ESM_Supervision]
BO_ 1486 BSI_RitcsData2: 3 BSI
 SG_ RawBits20_23 : 19|4@0+ (1,0) [0|15] "raw" Vector__XXX
 SG_ RoadType : 23|4@0+ (1,0) [0|15] "" Vector__XXX
 SG_ RawBits15_15 : 8|1@0+ (1,0) [0|1] "raw" Vector__XXX
 SG_ IndicatorStopPresent : 9|1@0+ (1,0) [0|1] "" Vector__XXX
 SG_ ElectricParkingBrakeFaultPresent : 10|1@0+ (1,0) [0|1] "" Vector__XXX
 SG_ StartIndicatorPresence : 11|1@0+ (1,0) [0|1] "" Vector__XXX
 SG_ LaneCountDrivingDirection : 14|3@0+ (1,0) [0|7] "" Vector__XXX
 SG_ IndicatorSamPresent : 15|1@0+ (1,0) [0|1] "" Vector__XXX
 SG_ CrashDetectedSinceLastPowerUp : 0|1@0+ (1,0) [0|1] "" Vector__XXX
 SG_ IndicatorParkingBrakePresent : 1|1@0+ (1,0) [0|1] "" Vector__XXX
 SG_ IndicatorFapPresent : 2|1@0+ (1,0) [0|1] "" Vector__XXX
 SG_ IndicatorGasoilWaterPresent : 3|1@0+ (1,0) [0|1] "" Vector__XXX
 SG_ DrivingSide : 4|1@0+ (1,0) [0|1] "" Vector__XXX
 SG_ CaarIndicatorPresent : 5|1@0+ (1,0) [0|1] "" Vector__XXX
 SG_ IndicatorDaePresent : 6|1@0+ (1,0) [0|1] "" Vector__XXX
 SG_ IndicatorEspPresent : 7|1@0+ (1,0) [0|1] "" Vector__XXX

BO_ 1506 E_VCU_StlVersion: 8 E_VCU
 SG_ Unused2 : 60|5@0+ (1,0) [0|31] ""  BSI,ABS
 SG_ AcSolenoidValve2Diagnosis : 61|1@0+ (1,0) [0|1] ""  BSI,ABS
 SG_ AcSolenoidValve1Diagnosis : 62|1@0+ (1,0) [0|1] ""  BSI,ABS
 SG_ Unused1 : 40|10@0+ (1,0) [0|1023] ""  BSI,ABS
 SG_ MixedModeEcoZevAvailability : 42|2@0+ (1,0) [0|3] ""  BSI,ABS
 SG_ MixedModeEcoHybridAvailability : 44|2@0+ (1,0) [0|3] ""  BSI,ABS
 SG_ DriveAxleModeStatus : 47|3@0+ (1,0) [0|7] ""  BSI,ABS
 SG_ DriveAxleModeRequestFeedback : 32|1@0+ (1,0) [0|1] ""  BSI,ABS
 SG_ EnergyModeRequestFeedback : 33|1@0+ (1,0) [0|1] ""  BSI,ABS
 SG_ EnergyModeStatus : 36|3@0+ (1,0) [0|7] ""  BSI,ABS
 SG_ DynamicDriveModeStatus : 39|3@0+ (1,0) [0|7] ""  BSI,ABS
 SG_ DynamicDriveModeRequestFeedback : 24|1@0+ (1,0) [0|1] ""  BSI,ABS
 SG_ DriveModeFeedbackToggleBit : 25|1@0+ (1,0) [0|1] ""  BSI,ABS
 SG_ MixedModeNormalZevAvailability : 27|2@0+ (1,0) [0|3] ""  BSI,ABS
 SG_ AxleModeAwdAvailability : 29|2@0+ (1,0) [0|3] ""  BSI,ABS
 SG_ AxleModeRearAvailability : 31|2@0+ (1,0) [0|3] ""  BSI,ABS
 SG_ AxleModeFrontAvailability : 17|2@0+ (1,0) [0|3] ""  BSI,ABS
 SG_ AxleModeAutoAvailability : 19|2@0+ (1,0) [0|3] ""  BSI,ABS
 SG_ EnergyModeFuelAvailability : 21|2@0+ (1,0) [0|3] ""  BSI,ABS
 SG_ EnergyModeZevAvailability : 23|2@0+ (1,0) [0|3] ""  BSI,ABS
 SG_ EnergyModeHybridAvailability : 9|2@0+ (1,0) [0|3] ""  BSI,ABS
 SG_ DynamicModeSpare2Availability : 11|2@0+ (1,0) [0|3] ""  BSI,ABS
 SG_ DynamicModeSpare1Availability : 13|2@0+ (1,0) [0|3] ""  BSI,ABS
 SG_ DynamicModeEcoPlusAvailability : 15|2@0+ (1,0) [0|3] ""  BSI,ABS
 SG_ DynamicModeSnowAvailability : 1|2@0+ (1,0) [0|3] ""  BSI,ABS
 SG_ DynamicModeEcoAvailability : 3|2@0+ (1,0) [0|3] ""  BSI,ABS
 SG_ DynamicModeSportAvailability : 5|2@0+ (1,0) [0|3] ""  BSI,ABS
 SG_ DynamicModeNormalAvailability : 7|2@0+ (1,0) [0|3] ""  BSI,ABS

BO_ 1515 ESM_Supervision: 8 ESM
 SG_ Unused1 : 59|4@0+ (1,0) [0|15] "" Vector__XXX
 SG_ PartialWakeupStatusFlagsP_c242fd : 43|16@0+ (1,0) [0|65535] "" Vector__XXX
 SG_ EcuOperatingPhase : 47|4@0+ (1,0) [0|15] "" Vector__XXX
 SG_ EcuConfirmedAbsentStatus : 15|32@0+ (1,0) [0|4294967295] "" Vector__XXX
 SG_ DiagnosticMemoryState : 7|8@0+ (1,0) [0|255] "" Vector__XXX

BO_ 1522 CVM_FrontCameraInfo: 5 CVM
 SG_ DistanceSinceLastSpeedSign : 39|8@0+ (20,0) [0|3000] "m"  BSI
 SG_ Unused2 : 28|5@0+ (1,0) [0|31] ""  BSI
 SG_ SpeedInfoRobustnessFlag : 29|1@0+ (1,0) [0|1] ""  BSI
 SG_ SpeedSignType : 31|2@0+ (1,0) [0|3] ""  BSI
 SG_ CameraReadSpeed : 23|8@0+ (1,0) [0|253] "km/h"  BSI
 SG_ Unused1 : 8|1@0+ (1,0) [0|1] ""  BSI
 SG_ CdpStatus : 9|1@0+ (1,0) [0|1] ""  BSI
 SG_ RainSensorWiperState : 11|2@0+ (1,0) [0|3] ""  BSI
 SG_ WiperSweepSpeed : 15|4@0+ (1,0) [0|15] ""  BSI
 SG_ CdlStatus : 0|1@0+ (1,0) [0|1] ""  BSI
 SG_ AafRequest : 1|1@0+ (1,0) [0|1] ""  BSI
 SG_ CafrBrightnessStatus : 2|1@0+ (1,0) [0|1] ""  BSI
 SG_ CafrFunctionFault : 3|1@0+ (1,0) [0|1] ""  BSI
 SG_ LowHighBeamSwitchingRequest : 4|1@0+ (1,0) [0|1] ""  BSI
 SG_ AbnormalLaneDepartureRight : 5|1@0+ (1,0) [0|1] ""  BSI
 SG_ AbnormalLaneDepartureLeft : 6|1@0+ (1,0) [0|1] ""  BSI
 SG_ StlFaultPresent : 7|1@0+ (1,0) [0|1] ""  BSI

BO_ 1554 BSI_Data3: 8 BSI
 SG_ RawBits62_63 : 57|2@0+ (1,0) [0|3] "raw"  BCP,CSS,CMM,HCU1,BVA,CVM
 SG_ VehicleConfigurationState : 60|3@0+ (1,0) [0|7] ""  BCP,CSS,CMM,HCU1,BVA,CVM
 SG_ RelayR3LineDiagnostic : 63|3@0+ (1,0) [0|7] ""  BCP,CSS,CMM,HCU1,BVA,CVM
 SG_ RawBits55_55 : 48|1@0+ (1,0) [0|1] "raw"  BCP,CSS,CMM,HCU1,BVA,CVM
 SG_ RelayLineDiagnosticUpdateBit : 49|1@0+ (1,0) [0|1] ""  BCP,CSS,CMM,HCU1,BVA,CVM
 SG_ RelayR2LineDiagnostic : 52|3@0+ (1,0) [0|7] ""  BCP,CSS,CMM,HCU1,BVA,CVM
 SG_ RelayR1LineDiagnostic : 55|3@0+ (1,0) [0|7] ""  BCP,CSS,CMM,HCU1,BVA,CVM
 SG_ StartingPredictedVoltage : 34|11@0+ (0.01,0) [0|13] "V"  BCP,CSS,CMM,HCU1,BVA,CVM
 SG_ RawBits36_36 : 35|1@0+ (1,0) [0|1] "raw"  BCP,CSS,CMM,HCU1,BVA,CVM
 SG_ MobileDeflectorPosition : 38|3@0+ (1,0) [0|7] ""  BCP,CSS,CMM,HCU1,BVA,CVM
 SG_ OlviRearHmiActivationRequest : 39|1@0+ (1,0) [0|1] ""  BCP,CSS,CMM,HCU1,BVA,CVM
 SG_ FuelLevel : 31|8@0+ (0.5,0) [0|127] "L"  BCP,CSS,CMM,HCU1,BVA,CVM
 SG_ EcoMode : 17|2@0+ (1,0) [0|3] ""  BCP,CSS,CMM,HCU1,BVA,CVM
 SG_ AsrPlusModeSelected : 19|2@0+ (1,0) [0|3] ""  BCP,CSS,CMM,HCU1,BVA,CVM
 SG_ HighBeamLeftFault : 20|1@0+ (1,0) [0|1] ""  BCP,CSS,CMM,HCU1,BVA,CVM
 SG_ HighBeamRightFault : 21|1@0+ (1,0) [0|1] ""  BCP,CSS,CMM,HCU1,BVA,CVM
 SG_ LowBeamLeftFault : 22|1@0+ (1,0) [0|1] ""  BCP,CSS,CMM,HCU1,BVA,CVM
 SG_ LowBeamRightFault : 23|1@0+ (1,0) [0|1] ""  BCP,CSS,CMM,HCU1,BVA,CVM
 SG_ RawBits15_15 : 8|1@0+ (1,0) [0|1] "raw"  BCP,CSS,CMM,HCU1,BVA,CVM
 SG_ LowBeamState : 9|1@0+ (1,0) [0|1] ""  BCP,CSS,CMM,HCU1,BVA,CVM
 SG_ HighBeamState : 10|1@0+ (1,0) [0|1] ""  BCP,CSS,CMM,HCU1,BVA,CVM
 SG_ RawBits12_12 : 11|1@0+ (1,0) [0|1] "raw"  BCP,CSS,CMM,HCU1,BVA,CVM
 SG_ VehicleConfigurationMode : 13|2@0+ (1,0) [0|3] ""  BCP,CSS,CMM,HCU1,BVA,CVM
 SG_ TurnIndicatorSwitchRequest : 15|2@0+ (1,0) [0|3] ""  BCP,CSS,CMM,HCU1,BVA,CVM
 SG_ Unused3 : 0|1@0+ (1,0) [0|1] ""  BCP,CSS,CMM,HCU1,BVA,CVM
 SG_ Unused2 : 1|1@0+ (1,0) [0|1] ""  BCP,CSS,CMM,HCU1,BVA,CVM
 SG_ RawBits4_5 : 3|2@0+ (1,0) [0|3] "raw"  BCP,CSS,CMM,HCU1,BVA,CVM
 SG_ Unused1 : 4|1@0+ (1,0) [0|1] ""  BCP,CSS,CMM,HCU1,BVA,CVM
 SG_ DynamicCurveLightingInhibit : 5|1@0+ (1,0) [0|1] ""  BCP,CSS,CMM,HCU1,BVA,CVM
 SG_ MotorwayLightingInhibit : 6|1@0+ (1,0) [0|1] ""  BCP,CSS,CMM,HCU1,BVA,CVM
 SG_ DynamicLightingDaytimeInhibit : 7|1@0+ (1,0) [0|1] ""  BCP,CSS,CMM,HCU1,BVA,CVM

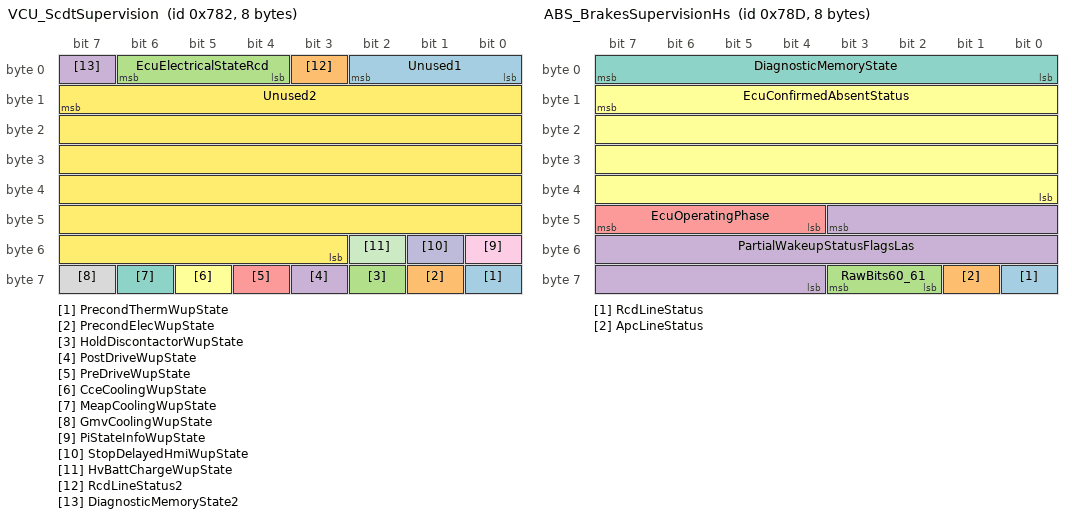
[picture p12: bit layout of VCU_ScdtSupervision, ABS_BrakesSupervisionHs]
BO_ 1922 VCU_ScdtSupervision: 8 VCU
 SG_ PrecondThermWupState : 56|1@0+ (1,0) [0|1] "" Vector__XXX
 SG_ PrecondElecWupState : 57|1@0+ (1,0) [0|1] "" Vector__XXX
 SG_ HoldDiscontactorWupState : 58|1@0+ (1,0) [0|1] "" Vector__XXX
 SG_ PostDriveWupState : 59|1@0+ (1,0) [0|1] "" Vector__XXX
 SG_ PreDriveWupState : 60|1@0+ (1,0) [0|1] "" Vector__XXX
 SG_ CceCoolingWupState : 61|1@0+ (1,0) [0|1] "" Vector__XXX
 SG_ MeapCoolingWupState : 62|1@0+ (1,0) [0|1] "" Vector__XXX
 SG_ GmvCoolingWupState : 63|1@0+ (1,0) [0|1] "" Vector__XXX
 SG_ PiStateInfoWupState : 48|1@0+ (1,0) [0|1] "" Vector__XXX
 SG_ StopDelayedHmiWupState : 49|1@0+ (1,0) [0|1] "" Vector__XXX
 SG_ HvBattChargeWupState : 50|1@0+ (1,0) [0|1] "" Vector__XXX
 SG_ Unused2 : 15|45@0+ (1,0) [0|35184372088831] "" Vector__XXX
 SG_ Unused1 : 2|3@0+ (1,0) [0|7] "" Vector__XXX
 SG_ RcdLineStatus2 : 3|1@0+ (1,0) [0|1] "" Vector__XXX
 SG_ EcuElectricalStateRcd : 6|3@0+ (1,0) [0|7] "" Vector__XXX
 SG_ DiagnosticMemoryState2 : 7|1@0+ (1,0) [0|1] "" Vector__XXX

BO_ 1933 ABS_BrakesSupervisionHs: 8 ABS
 SG_ RcdLineStatus : 56|1@0+ (1,0) [0|1] "" Vector__XXX
 SG_ ApcLineStatus : 57|1@0+ (1,0) [0|1] "" Vector__XXX
 SG_ RawBits60_61 : 59|2@0+ (1,0) [0|3] "raw" Vector__XXX
 SG_ PartialWakeupStatusFlagsLas : 43|16@0+ (1,0) [0|65535] "" Vector__XXX
 SG_ EcuOperatingPhase : 47|4@0+ (1,0) [0|15] "" Vector__XXX
 SG_ EcuConfirmedAbsentStatus : 15|32@0+ (1,0) [0|4294967295] "" Vector__XXX
 SG_ DiagnosticMemoryState : 7|8@0+ (1,0) [0|255] "" Vector__XXX

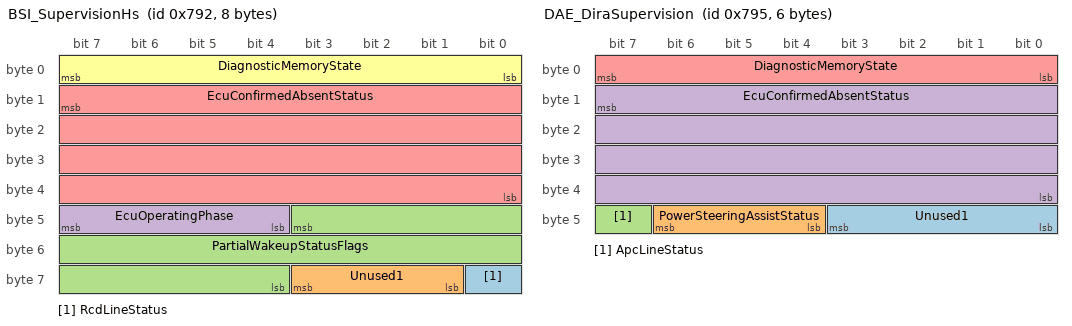
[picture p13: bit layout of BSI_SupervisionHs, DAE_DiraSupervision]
BO_ 1938 BSI_SupervisionHs: 8 BSI
 SG_ RcdLineStatus : 56|1@0+ (1,0) [0|1] "" Vector__XXX
 SG_ Unused1 : 59|3@0+ (1,0) [0|7] "" Vector__XXX
 SG_ PartialWakeupStatusFlags : 43|16@0+ (1,0) [0|65535] "" Vector__XXX
 SG_ EcuOperatingPhase : 47|4@0+ (1,0) [0|15] "" Vector__XXX
 SG_ EcuConfirmedAbsentStatus : 15|32@0+ (1,0) [0|4294967295] "" Vector__XXX
 SG_ DiagnosticMemoryState : 7|8@0+ (1,0) [0|255] "" Vector__XXX

BO_ 1941 DAE_DiraSupervision: 6 DAE
 SG_ Unused1 : 43|4@0+ (1,0) [0|15] "" Vector__XXX
 SG_ PowerSteeringAssistStatus : 46|3@0+ (1,0) [0|7] "" Vector__XXX
 SG_ ApcLineStatus : 47|1@0+ (1,0) [0|1] "" Vector__XXX
 SG_ EcuConfirmedAbsentStatus : 15|32@0+ (1,0) [0|4294967295] "" Vector__XXX
 SG_ DiagnosticMemoryState : 7|8@0+ (1,0) [0|255] "" Vector__XXX

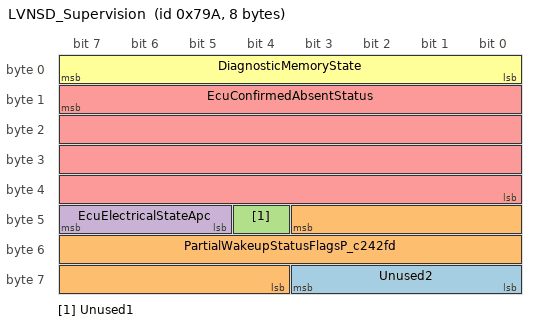
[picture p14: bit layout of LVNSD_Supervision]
BO_ 1946 LVNSD_Supervision: 8 LVNSD
 SG_ Unused2 : 59|4@0+ (1,0) [0|15] "" Vector__XXX
 SG_ PartialWakeupStatusFlagsP_c242fd : 43|16@0+ (1,0) [0|65535] "" Vector__XXX
 SG_ Unused1 : 44|1@0+ (1,0) [0|1] "" Vector__XXX
 SG_ EcuElectricalStateApc : 47|3@0+ (1,0) [0|7] "" Vector__XXX
 SG_ EcuConfirmedAbsentStatus : 15|32@0+ (1,0) [0|4294967295] "" Vector__XXX
 SG_ DiagnosticMemoryState : 7|8@0+ (1,0) [0|255] "" Vector__XXX

BO_TX_BU_ 1304 : E_VCU,CMM;
BO_TX_BU_ 1347 : E_VCU,VCU;
BO_TX_BU_ 1379 : E_VCU,VCU;
BO_TX_BU_ 1411 : E_VCU,VCU;
BO_TX_BU_ 1432 : E_VCU,CMM;
BO_TX_BU_ 1442 : E_VCU,VCU;
BO_TX_BU_ 1443 : E_VCU,VCU;
BO_TX_BU_ 1506 : E_VCU,VCU;
CM_ BO_ 1293 "Observed OBD 6/14 HS1. CAN ID 0x50D; ID_DLC_match. PSA-RE name: BRAKE_ABR_STATUS. ABR (hill-descent assist) data from the ABS unit: brake fluid alert, wheel pulse counters and faults, AAFD/SFU function status, reference regulation and warning-lamp requests. Source: https://github.com/prototux/PSA-RE/blob/67f7581e7622410efdbb29c7eda3b86982b9b450/buses/AEE2010.full/HS.HS1/50D.yml. Database sender alternatives: ABS. ECU labels are database claims; forwarding/physical transmitter not independently identified. All fitting source fields retained, including default/unavailable-only candidates. See audit/source JSON for exclusions and unresolved alternatives.";
CM_ SG_ 1293 BrakeEcuFrame5Checksum "DATABASE_CANDIDATE: layout imported; physical meaning not independently verified. PSA-RE bits 8.3-8.0. Checksum of dynamic frame 5 from the brake ECU";
CM_ SG_ 1293 ProcessCounter50d "DATABASE_CANDIDATE: layout imported; physical meaning not independently verified. PSA-RE bits 8.7-8.4. 4-bit rolling process counter of frame 0x50D Upstream default raw=0 (not necessarily valid data).";
CM_ SG_ 1293 EspDisconnectRequest "DATABASE_CANDIDATE: layout imported; physical meaning not independently verified. PSA-RE bits 7.0. ESP disconnection status requested by a diagnostic tool Upstream default raw=0 (not necessarily valid data).";
CM_ SG_ 1293 BrakeAssistFaultLampRequest "DATABASE_CANDIDATE: layout imported; physical meaning not independently verified. PSA-RE bits 7.1. Brake assist fault warning lamp activation request Upstream default raw=0 (not necessarily valid data).";
CM_ SG_ 1293 StaticSlopeState "DATABASE_CANDIDATE: layout imported; physical meaning not independently verified. PSA-RE bits 7.3-7.2. Static road slope state (uphill/downhill) Upstream default raw=3 (not necessarily valid data).";
CM_ SG_ 1293 BrakeFunctionNeedForStartStop "DATABASE_CANDIDATE: layout imported; physical meaning not independently verified. PSA-RE bits 7.5-7.4. Brake function requirement for the stop-start (STT) system Upstream default raw=0 (not necessarily valid data).";
CM_ SG_ 1293 BrakeEcuPowerManagementFault "DATABASE_CANDIDATE: layout imported; physical meaning not independently verified. PSA-RE bits 7.6. Electrical power management fault detected by the brake ECU Upstream default raw=0 (not necessarily valid data).";
CM_ SG_ 1293 EmergencyBrakingSignaliza_517ee3 "DATABASE_CANDIDATE: layout imported; physical meaning not independently verified. PSA-RE bits 7.7. Indicates whether the emergency braking signal function is implemented in the brake ECU Upstream default raw=0 (not necessarily valid data).";
CM_ SG_ 1293 BrakeEcuSupplyVoltage "DATABASE_CANDIDATE: layout imported; physical meaning not independently verified. PSA-RE bits 6.7-6.0. Battery voltage measured by the brake ECU Raw invalid=255; numeric DBC decoders may still scale it: check raw before use. Unresolved source alternatives: [{\"factor\": 0.057, \"note\": \"Also observed with another scaling (factor 0.057)\"}]";
CM_ SG_ 1293 RearRightWheelSpinCounter "DATABASE_CANDIDATE: layout imported; physical meaning not independently verified. PSA-RE bits 4.6-5.0. Free-running rear right wheel speed sensor pulse counter Upstream default raw=0 (not necessarily valid data).";
CM_ SG_ 1293 RearRightWheelSpeedSensorFault "DATABASE_CANDIDATE: layout imported; physical meaning not independently verified. PSA-RE bits 4.7. Rear right wheel-speed pulse counter malfunction Upstream default raw=0 (not necessarily valid data).";
CM_ SG_ 1293 RearLeftWheelSpinCounter "DATABASE_CANDIDATE: layout imported; physical meaning not independently verified. PSA-RE bits 2.6-3.0. Free-running rear left wheel speed sensor pulse counter Upstream default raw=0 (not necessarily valid data).";
CM_ SG_ 1293 RearLeftWheelSpeedSensorFault "DATABASE_CANDIDATE: layout imported; physical meaning not independently verified. PSA-RE bits 2.7. Rear left wheel-speed pulse counter malfunction Upstream default raw=0 (not necessarily valid data).";
CM_ SG_ 1293 AbsFaultLampRequest "DATABASE_CANDIDATE: layout imported; physical meaning not independently verified. PSA-RE bits 1.0. ABS fault warning lamp activation request Upstream default raw=1 (not necessarily valid data).";
CM_ SG_ 1293 BrakeFluidLevelAlert "DATABASE_CANDIDATE: layout imported; physical meaning not independently verified. PSA-RE bits 1.1. Brake fluid level alert Upstream default raw=0 (not necessarily valid data).";
CM_ SG_ 1293 WornBrakePadsIndicator "DATABASE_CANDIDATE: layout imported; physical meaning not independently verified. PSA-RE bits 1.2. Brake pad wear indicator Upstream default raw=0 (not necessarily valid data).";
CM_ SG_ 1293 RefInProgress "DATABASE_CANDIDATE: layout imported; physical meaning not independently verified. PSA-RE bits 1.3. Electronic brake force distribution (REF) regulation in progress Upstream default raw=0 (not necessarily valid data).";
CM_ SG_ 1293 AutomaticHazardLightsByUcBrake "DATABASE_CANDIDATE: layout imported; physical meaning not independently verified. PSA-RE bits 1.4. Indicates whether the automatic hazard warning lights function is implemented in the brake ECU Upstream default raw=0 (not necessarily valid data).";
CM_ SG_ 1293 AbsInProgress "DATABASE_CANDIDATE: layout imported; physical meaning not independently verified. PSA-RE bits 1.5. ABS regulation in progress Upstream default raw=0 (not necessarily valid data).";
CM_ SG_ 1293 Unused1 "DATABASE_CANDIDATE: layout imported; physical meaning not independently verified. PSA-RE bits 1.6. ";
CM_ SG_ 1293 RefFaultLamp "DATABASE_CANDIDATE: layout imported; physical meaning not independently verified. PSA-RE bits 1.7. Electronic brake force distribution (REF) fault warning lamp activation request Upstream default raw=1 (not necessarily valid data).";
CM_ BO_ 1298 "Observed OBD 6/14 HS1. CAN ID 0x512; ID_DLC_match. PSA-RE name: BSI_DRIVE_MODE_REQUESTS. Requests from the BSI: cabin thermal preconditioning and type, vehicle locked-in/locked-out status, and drive axle/dynamic/energy mode selection. Source: https://github.com/prototux/PSA-RE/blob/67f7581e7622410efdbb29c7eda3b86982b9b450/buses/AEE2010.full/HS.HS1/512.yml. Database sender alternatives: BSI. ECU labels are database claims; forwarding/physical transmitter not independently identified. All fitting source fields retained, including default/unavailable-only candidates. See audit/source JSON for exclusions and unresolved alternatives.";
CM_ SG_ 1298 Unused1 "DATABASE_CANDIDATE: layout imported; physical meaning not independently verified. PSA-RE bits 3.7-4.0. ";
CM_ SG_ 1298 CabinPreconditioningTypeRequest "DATABASE_CANDIDATE: layout imported; physical meaning not independently verified. PSA-RE bits 2.0. Requested cabin preconditioning type Upstream default raw=0 (not necessarily valid data).";
CM_ SG_ 1298 VehicleLockedFromOutside "DATABASE_CANDIDATE: layout imported; physical meaning not independently verified. PSA-RE bits 2.2-2.1. Vehicle locked from the outside Upstream default raw=0 (not necessarily valid data).";
CM_ SG_ 1298 VehicleLockedFromInside "DATABASE_CANDIDATE: layout imported; physical meaning not independently verified. PSA-RE bits 2.4-2.3. Vehicle locked from the inside Upstream default raw=0 (not necessarily valid data).";
CM_ SG_ 1298 DriveAxleModeRequest "DATABASE_CANDIDATE: layout imported; physical meaning not independently verified. PSA-RE bits 2.7-2.5. Requested drive axle mode (front/rear/AWD) Upstream default raw=4 (not necessarily valid data).";
CM_ SG_ 1298 CabinThermalPreconditioni_484d54 "DATABASE_CANDIDATE: layout imported; physical meaning not independently verified. PSA-RE bits 1.0. Cabin thermal preconditioning request Upstream default raw=1 (not necessarily valid data).";
CM_ SG_ 1298 DriveModeRequestToggleBit "DATABASE_CANDIDATE: layout imported; physical meaning not independently verified. PSA-RE bits 1.1. Toggle bit for the requested driving mode change Upstream default raw=0 (not necessarily valid data).";
CM_ SG_ 1298 EnergyModeRequest "DATABASE_CANDIDATE: layout imported; physical meaning not independently verified. PSA-RE bits 1.4-1.2. Requested energy mode (Hybrid/Electric/Fuel) Upstream default raw=3 (not necessarily valid data).";
CM_ SG_ 1298 DynamicDriveModeRequest "DATABASE_CANDIDATE: layout imported; physical meaning not independently verified. PSA-RE bits 1.7-1.5. Requested dynamic driving mode (Normal/Sport/Eco/Snow) Upstream default raw=5 (not necessarily valid data).";
CM_ BO_ 1304 "Observed OBD 6/14 HS1. CAN ID 0x518; ID_DLC_match. PSA-RE name: ENGINE_ECU_DATA_9. Engine ECU data: power-reduction-off request, atmospheric pressure, main wake-up and SCR purge wake-up. Source: https://github.com/prototux/PSA-RE/blob/67f7581e7622410efdbb29c7eda3b86982b9b450/buses/AEE2010.full/HS.HS1/518.yml. Database sender alternatives: CMM,E_VCU. ECU labels are database claims; forwarding/physical transmitter not independently identified. All fitting source fields retained, including default/unavailable-only candidates. See audit/source JSON for exclusions and unresolved alternatives.";
CM_ SG_ 1304 RawByte4 "RAW. PSA-RE bits 4.7-4.0. Raw unmapped/padding bits; no physical interpretation.";
CM_ SG_ 1304 RawByte3 "RAW. PSA-RE bits 3.7-3.0. Raw unmapped/padding bits; no physical interpretation.";
CM_ SG_ 1304 RawBits12_15 "RAW. PSA-RE bits 2.3-2.0. Raw unmapped/padding bits; no physical interpretation.";
CM_ SG_ 1304 PowertrainRollerBenchMode "DATABASE_CANDIDATE: layout imported; physical meaning not independently verified. PSA-RE bits 2.5-2.4. Powertrain roller test bench mode";
CM_ SG_ 1304 PowertrainCombinedPower "DATABASE_CANDIDATE: layout imported; physical meaning not independently verified. PSA-RE bits 1.7-2.6. Power delivered by the powertrain (W) Raw invalid=1023; numeric DBC decoders may still scale it: check raw before use. Unresolved source alternatives: [{\"note\": \"Also observed with another scaling (offset -128000)\", \"offset\": -128000}]";
CM_ BO_ 1314 "Observed OBD 6/14 HS1. CAN ID 0x522; ID_DLC_match. PSA-RE name: BPVA_SUPERVISION. Electric vehicle charge status: charging station stop-charge request and charge-in-progress mode. Source: https://github.com/prototux/PSA-RE/blob/67f7581e7622410efdbb29c7eda3b86982b9b450/buses/AEE2010.electric/HS.HS1/522.yml. Database sender alternatives: E_VCU. ECU labels are database claims; forwarding/physical transmitter not independently identified. All fitting source fields retained, including default/unavailable-only candidates. See audit/source JSON for exclusions and unresolved alternatives.";
CM_ SG_ 1314 ChargeRemainingTimeDisplay "DATABASE_CANDIDATE: layout imported; physical meaning not independently verified. PSA-RE bits 7.3-8.0. Remaining charging time to display (min) Raw invalid=4095; numeric DBC decoders may still scale it: check raw before use.";
CM_ SG_ 1314 RawBits48_51 "RAW. PSA-RE bits 7.7-7.4. Raw unmapped/padding bits; no physical interpretation.";
CM_ SG_ 1314 RawByte6 "RAW. PSA-RE bits 6.7-6.0. Raw unmapped/padding bits; no physical interpretation.";
CM_ SG_ 1314 HvBatteryAverageTemperature "DATABASE_CANDIDATE: layout imported; physical meaning not independently verified. PSA-RE bits 5.7-5.0. HV battery average temperature (°C) Raw invalid=255; numeric DBC decoders may still scale it: check raw before use.";
CM_ SG_ 1314 RawBits27_31 "RAW. PSA-RE bits 4.4-4.0. Raw unmapped/padding bits; no physical interpretation.";
CM_ SG_ 1314 InverterWorkingState "DATABASE_CANDIDATE: layout imported; physical meaning not independently verified. PSA-RE bits 4.7-4.5. Traction inverter working state";
CM_ SG_ 1314 RawByte3 "RAW. PSA-RE bits 3.7-3.0. Raw unmapped/padding bits; no physical interpretation.";
CM_ SG_ 1314 RawByte2 "RAW. PSA-RE bits 2.7-2.0. Raw unmapped/padding bits; no physical interpretation.";
CM_ SG_ 1314 DcdcConverterTemperature "DATABASE_CANDIDATE: layout imported; physical meaning not independently verified. PSA-RE bits 1.7-1.0. DC/DC converter temperature (°C) Raw invalid=255; numeric DBC decoders may still scale it: check raw before use.";
CM_ BO_ 1326 "Observed OBD 6/14 HS1. CAN ID 0x52E; ID_DLC_match. PSA-RE name: BSI_CABIN_DATA_12. Body controller cabin data: hybrid blower setpoint, load-shedding requests for ABS/ESP, electric power steering, EasyMove and suspension, demisting request and hybrid zero-emission cabin inhibition. Source: https://github.com/prototux/PSA-RE/blob/67f7581e7622410efdbb29c7eda3b86982b9b450/buses/AEE2010.full/HS.HS1/52E.yml. Database sender alternatives: BSI. ECU labels are database claims; forwarding/physical transmitter not independently identified. All fitting source fields retained, including default/unavailable-only candidates. See audit/source JSON for exclusions and unresolved alternatives.";
CM_ SG_ 1326 CruiseControlSpeed "DATABASE_CANDIDATE: layout imported; physical meaning not independently verified. PSA-RE bits 7.7-8.0. speed limiter/cruise control speed setpoint Raw invalid=65535; numeric DBC decoders may still scale it: check raw before use. Upstream default raw=0 (not necessarily valid data).";
CM_ SG_ 1326 Distance "DATABASE_CANDIDATE: layout imported; physical meaning not independently verified. PSA-RE bits 5.7-6.0. Mileage before maintenance Raw invalid=65535; numeric DBC decoders may still scale it: check raw before use.";
CM_ SG_ 1326 DistanceTravelled "DATABASE_CANDIDATE: layout imported; physical meaning not independently verified. PSA-RE bits 3.7-4.0. Rolling distance counter, 0.1 m per bit, wraps after 0xFFFF (6553.5 m); no invalid value, frozen when unknown Upstream default raw=0 (not necessarily valid data).";
CM_ SG_ 1326 Autonomy "DATABASE_CANDIDATE: layout imported; physical meaning not independently verified. PSA-RE bits 1.7-2.0. Residual range Raw invalid=65535; numeric DBC decoders may still scale it: check raw before use. Upstream default raw=65535 (not necessarily valid data).";
CM_ BO_ 1338 "Observed OBD 6/14 HS1. CAN ID 0x53A; ID_DLC_match. PSA-RE name: LVNSD_DATA_2. LVNSD node data: service-blink request, battery diagnostic state and switch state. Source: https://github.com/prototux/PSA-RE/blob/67f7581e7622410efdbb29c7eda3b86982b9b450/buses/AEE2010.full/HS.HS1/53A.yml. Database sender alternatives: LVNSD. ECU labels are database claims; forwarding/physical transmitter not independently identified. All fitting source fields retained, including default/unavailable-only candidates. See audit/source JSON for exclusions and unresolved alternatives.";
CM_ SG_ 1338 Unused3 "DATABASE_CANDIDATE: layout imported; physical meaning not independently verified. PSA-RE bits 3.5-3.0. ";
CM_ SG_ 1338 LvBatteryThermalDeratingState "DATABASE_CANDIDATE: layout imported; physical meaning not independently verified. PSA-RE bits 3.7-3.6. Thermal derating status of the low-voltage battery module Upstream default raw=1 (not necessarily valid data).";
CM_ SG_ 1338 Unused2 "DATABASE_CANDIDATE: layout imported; physical meaning not independently verified. PSA-RE bits 2.0. ";
CM_ SG_ 1338 LvBatterySwitchingVoltage "DATABASE_CANDIDATE: layout imported; physical meaning not independently verified. PSA-RE bits 2.7-2.1. Switching voltage at the BAT12 interface (V) Raw invalid=127; numeric DBC decoders may still scale it: check raw before use. Upstream default raw=126 (not necessarily valid data).";
CM_ SG_ 1338 Unused1 "DATABASE_CANDIDATE: layout imported; physical meaning not independently verified. PSA-RE bits 1.0. ";
CM_ SG_ 1338 LvBatterySupplyNetworkVoltage "DATABASE_CANDIDATE: layout imported; physical meaning not independently verified. PSA-RE bits 1.7-1.1. Switching voltage at the electrical network (RDB) interface (V) Raw invalid=127; numeric DBC decoders may still scale it: check raw before use. Upstream default raw=126 (not necessarily valid data).";
CM_ BO_ 1347 "Observed OBD 6/14 HS1. CAN ID 0x543; DLC_mismatch. PSA-RE name: EV_BATTERY_ENERGY. Remaining and total battery energy, and battery state of health (capacity and resistance) Source: https://github.com/prototux/PSA-RE/blob/67f7581e7622410efdbb29c7eda3b86982b9b450/buses/AEE2010.electric/HS.HS1/543.yml. Database sender alternatives: VCU,E_VCU. ECU labels are database claims; forwarding/physical transmitter not independently identified. All fitting source fields retained, including default/unavailable-only candidates. See audit/source JSON for exclusions and unresolved alternatives.";
CM_ SG_ 1347 RawBits27_31 "RAW. PSA-RE bits 4.4-4.0. Raw unmapped/padding bits; no physical interpretation. WARNING: upstream DLC 6 differs from observed 4; this in-bounds prefix is an unverified candidate.";
CM_ SG_ 1347 BmsTotalBatteryEnergy "DATABASE_CANDIDATE: layout imported; physical meaning not independently verified. PSA-RE bits 3.7-4.5. Total battery energy reported by the battery management system (BMS) (Wh) Raw invalid=2047; numeric DBC decoders may still scale it: check raw before use. WARNING: upstream DLC 6 differs from observed 4; this in-bounds prefix is an unverified candidate.";
CM_ SG_ 1347 RawBits12_15 "RAW. PSA-RE bits 2.3-2.0. Raw unmapped/padding bits; no physical interpretation. WARNING: upstream DLC 6 differs from observed 4; this in-bounds prefix is an unverified candidate.";
CM_ SG_ 1347 BatteryEnergyExtendedFlag "DATABASE_CANDIDATE: layout imported; physical meaning not independently verified. PSA-RE bits 2.4. Flag indicating whether the battery energy value uses the extended range WARNING: upstream DLC 6 differs from observed 4; this in-bounds prefix is an unverified candidate.";
CM_ SG_ 1347 BmsRemainingBatteryEnergy "DATABASE_CANDIDATE: layout imported; physical meaning not independently verified. PSA-RE bits 1.7-2.5. Remaining battery energy reported by the battery management system (BMS) (Wh) Raw invalid=2047; numeric DBC decoders may still scale it: check raw before use. WARNING: upstream DLC 6 differs from observed 4; this in-bounds prefix is an unverified candidate.";
CM_ BO_ 1358 "Observed OBD 6/14 HS1. CAN ID 0x54E; ID_DLC_match. PSA-RE name: BSI_CABIN_DATA_13. Body controller cabin data: hybrid blower setpoint, load-shedding requests for ABS/ESP, electric power steering, EasyMove and suspension, demisting request and hybrid zero-emission cabin inhibition. Source: https://github.com/prototux/PSA-RE/blob/67f7581e7622410efdbb29c7eda3b86982b9b450/buses/AEE2010.full/HS.HS1/54E.yml. Database sender alternatives: BSI. ECU labels are database claims; forwarding/physical transmitter not independently identified. All fitting source fields retained, including default/unavailable-only candidates. See audit/source JSON for exclusions and unresolved alternatives.";
CM_ SG_ 1358 EcoTime "DATABASE_CANDIDATE: layout imported; physical meaning not independently verified. PSA-RE bits 8.7-8.0. ECO time Raw invalid=127; numeric DBC decoders may still scale it: check raw before use. Upstream default raw=0 (not necessarily valid data).";
CM_ SG_ 1358 FilteredFuelLevel "DATABASE_CANDIDATE: layout imported; physical meaning not independently verified. PSA-RE bits 7.7-7.0. Filtered fuel level Raw invalid=255; numeric DBC decoders may still scale it: check raw before use. Upstream default raw=0 (not necessarily valid data).";
CM_ SG_ 1358 TotalMileage "DATABASE_CANDIDATE: layout imported; physical meaning not independently verified. PSA-RE bits 4.7-6.0. Vehicle odometer, 0.1 km per bit; invalid when all bits set Raw invalid=16777215; numeric DBC decoders may still scale it: check raw before use. Upstream default raw=16777215 (not necessarily valid data).";
CM_ SG_ 1358 OdometerPartial "DATABASE_CANDIDATE: layout imported; physical meaning not independently verified. PSA-RE bits 1.7-3.0. Partial odometer (trip meter) Raw invalid=16777215; numeric DBC decoders may still scale it: check raw before use. Upstream default raw=0 (not necessarily valid data).";
CM_ BO_ 1362 "Observed OBD 6/14 HS1. CAN ID 0x552; ID_DLC_match. PSA-RE name: BSI_ODOMETER_DATA. Odometer reading from the BSI, plus a time counter and a global-time-reset counter. Source: https://github.com/prototux/PSA-RE/blob/67f7581e7622410efdbb29c7eda3b86982b9b450/buses/AEE2010.full/HS.HS1/552.yml. Database sender alternatives: BSI. ECU labels are database claims; forwarding/physical transmitter not independently identified. All fitting source fields retained, including default/unavailable-only candidates. See audit/source JSON for exclusions and unresolved alternatives.";
CM_ SG_ 1362 TimeCounterResetCounter "DATABASE_CANDIDATE: layout imported; physical meaning not independently verified. PSA-RE bits 8.7-8.0. Reset counter of the vehicle time counter (GCT); value 0xFE means unavailable Raw invalid=255; numeric DBC decoders may still scale it: check raw before use. Upstream default raw=254 (not necessarily valid data).";
CM_ SG_ 1362 Odometer "DATABASE_CANDIDATE: layout imported; physical meaning not independently verified. PSA-RE bits 5.7-7.0. Absolute distance travelled by the vehicle (matching the value shown to the driver) (km) Raw invalid=16777215; numeric DBC decoders may still scale it: check raw before use. Upstream default raw=0 (not necessarily valid data).";
CM_ SG_ 1362 VehicleTimeCounter "DATABASE_CANDIDATE: layout imported; physical meaning not independently verified. PSA-RE bits 1.7-4.0. Vehicle time counter; value 0xFFFFFFFE means unavailable Raw invalid=4294967295; numeric DBC decoders may still scale it: check raw before use. Upstream default raw=4294967294 (not necessarily valid data).";
CM_ BO_ 1370 "Observed OBD 6/14 HS1. CAN ID 0x55A; ID_DLC_match. PSA-RE name: LVNSD_DATA_3. LVNSD node data: service-blink request, battery diagnostic state and switch state. Source: https://github.com/prototux/PSA-RE/blob/67f7581e7622410efdbb29c7eda3b86982b9b450/buses/AEE2010.full/HS.HS1/55A.yml. Database sender alternatives: LVNSD. ECU labels are database claims; forwarding/physical transmitter not independently identified. All fitting source fields retained, including default/unavailable-only candidates. See audit/source JSON for exclusions and unresolved alternatives.";
CM_ SG_ 1370 BatteryResistanceSeq3 "DATABASE_CANDIDATE: layout imported; physical meaning not independently verified. PSA-RE bits 6.0-7.0. Battery internal resistance under 12V, measurement sequence 3 (mOhm) Raw invalid=511; numeric DBC decoders may still scale it: check raw before use. Upstream default raw=0 (not necessarily valid data).";
CM_ SG_ 1370 BatteryVoltageSeq3 "DATABASE_CANDIDATE: layout imported; physical meaning not independently verified. PSA-RE bits 6.7-6.1. Battery voltage measured under a 100A load, sequence 3 (V) Raw invalid=127; numeric DBC decoders may still scale it: check raw before use. Upstream default raw=0 (not necessarily valid data).";
CM_ SG_ 1370 BatteryResistanceSeq2 "DATABASE_CANDIDATE: layout imported; physical meaning not independently verified. PSA-RE bits 4.0-5.0. Battery internal resistance under 12V, measurement sequence 2 (mOhm) Raw invalid=511; numeric DBC decoders may still scale it: check raw before use. Upstream default raw=0 (not necessarily valid data).";
CM_ SG_ 1370 BatteryVoltageSeq2 "DATABASE_CANDIDATE: layout imported; physical meaning not independently verified. PSA-RE bits 4.7-4.1. Battery voltage measured under a 100A load, sequence 2 (V) Raw invalid=127; numeric DBC decoders may still scale it: check raw before use. Upstream default raw=0 (not necessarily valid data).";
CM_ SG_ 1370 BatteryResistanceSeq4 "DATABASE_CANDIDATE: layout imported; physical meaning not independently verified. PSA-RE bits 2.0-3.0. Battery internal resistance under 12V, measurement sequence 4 (mOhm) Raw invalid=511; numeric DBC decoders may still scale it: check raw before use. Upstream default raw=0 (not necessarily valid data).";
CM_ SG_ 1370 BatteryResistanceSeq1 "DATABASE_CANDIDATE: layout imported; physical meaning not independently verified. PSA-RE bits 2.0-3.0. Battery internal resistance under 12V, measurement sequence 1 (mOhm) Raw invalid=511; numeric DBC decoders may still scale it: check raw before use. Upstream default raw=0 (not necessarily valid data).";
CM_ SG_ 1370 BatteryVoltageSeq4 "DATABASE_CANDIDATE: layout imported; physical meaning not independently verified. PSA-RE bits 2.7-2.1. Battery voltage measured under a 100A load, sequence 4 (V) Raw invalid=127; numeric DBC decoders may still scale it: check raw before use. Upstream default raw=0 (not necessarily valid data).";
CM_ SG_ 1370 BatteryVoltageSeq1 "DATABASE_CANDIDATE: layout imported; physical meaning not independently verified. PSA-RE bits 2.7-2.1. Battery voltage measured under a 100A load, sequence 1 (V) Raw invalid=127; numeric DBC decoders may still scale it: check raw before use. Upstream default raw=0 (not necessarily valid data).";
CM_ SG_ 1370 Unused1 "DATABASE_CANDIDATE: layout imported; physical meaning not independently verified. PSA-RE bits 1.6-1.0. ";
CM_ SG_ 1370 LvBatterySequenceId "DATABASE_CANDIDATE: layout imported; physical meaning not independently verified. PSA-RE bits 1.7. Identifier of the low-voltage battery measurement sequence being transmitted Upstream default raw=0 (not necessarily valid data).";
CM_ BO_ 1379 "Observed OBD 6/14 HS1. CAN ID 0x563; ID_DLC_match. PSA-RE name: EV_DRIVE_STATUS. Remaining battery capacity, inverter temperature alerts and brake-assist warning lamp request Source: https://github.com/prototux/PSA-RE/blob/67f7581e7622410efdbb29c7eda3b86982b9b450/buses/AEE2010.electric/HS.HS1/563.yml. Database sender alternatives: VCU,E_VCU. ECU labels are database claims; forwarding/physical transmitter not independently identified. All fitting source fields retained, including default/unavailable-only candidates. See audit/source JSON for exclusions and unresolved alternatives. WARNING: capture alternates payload families; source has no selector. Candidate fields are retained for research, not validated as one fixed physical layout.";
CM_ SG_ 1379 RawBits52_55 "RAW. PSA-RE bits 7.3-7.0. Raw unmapped/padding bits; no physical interpretation.";
CM_ SG_ 1379 BmsRemainingBatteryCapacity "DATABASE_CANDIDATE: layout imported; physical meaning not independently verified. PSA-RE bits 5.7-7.4. Remaining battery capacity reported by the battery management system (BMS) (Ah) Raw invalid=1048575; numeric DBC decoders may still scale it: check raw before use.";
CM_ SG_ 1379 RawBits31_31 "RAW. PSA-RE bits 4.0-4.0. Raw unmapped/padding bits; no physical interpretation.";
CM_ SG_ 1379 EbbAssistFaultLampRequest "DATABASE_CANDIDATE: layout imported; physical meaning not independently verified. PSA-RE bits 4.1. Request to light the brake assist fault warning lamp";
CM_ SG_ 1379 PemOvertemperatureFault "DATABASE_CANDIDATE: layout imported; physical meaning not independently verified. PSA-RE bits 4.2. Overtemperature fault on the front electric machine (PEM) inverter";
CM_ SG_ 1379 RemInverterTemperatureAlert "DATABASE_CANDIDATE: layout imported; physical meaning not independently verified. PSA-RE bits 4.3. Overtemperature warning on the rear electric machine (eRAD) inverter";
CM_ SG_ 1379 PemInverterTemperatureAlert "DATABASE_CANDIDATE: layout imported; physical meaning not independently verified. PSA-RE bits 4.4. Temperature warning on the front electric machine (PEM) inverter";
CM_ SG_ 1379 PowertrainValidatedLeverPosition "DATABASE_CANDIDATE: layout imported; physical meaning not independently verified. PSA-RE bits 4.7-4.5. Validated gear lever position (Park, Reverse, Neutral, Automatic, Manual)";
CM_ SG_ 1379 RawByte3 "RAW. PSA-RE bits 3.7-3.0. Raw unmapped/padding bits; no physical interpretation.";
CM_ SG_ 1379 RawByte2 "RAW. PSA-RE bits 2.7-2.0. Raw unmapped/padding bits; no physical interpretation.";
CM_ SG_ 1379 RawByte1 "RAW. PSA-RE bits 1.7-1.0. Raw unmapped/padding bits; no physical interpretation.";
CM_ BO_ 1387 "Observed OBD 6/14 HS1. CAN ID 0x56B; ID_DLC_match. PSA-RE name: FRONT_CAMERA_COMMAND_2. Commands sent by the BSI to the front camera module: lane detection authorisation, auto/manual washer and wiper commands, units/language and occultation state. Source: https://github.com/prototux/PSA-RE/blob/67f7581e7622410efdbb29c7eda3b86982b9b450/buses/AEE2010.full/HS.HS1/56B.yml. Database sender alternatives: BSI. ECU labels are database claims; forwarding/physical transmitter not independently identified. All fitting source fields retained, including default/unavailable-only candidates. See audit/source JSON for exclusions and unresolved alternatives.";
CM_ SG_ 1387 RawBits26_31 "RAW. PSA-RE bits 4.5-4.0. Raw unmapped/padding bits; no physical interpretation.";
CM_ SG_ 1387 UnitLanguageDataValidity "DATABASE_CANDIDATE: layout imported; physical meaning not independently verified. PSA-RE bits 4.6. Validity of the speed unit information transmitted in the same frame Upstream default raw=0 (not necessarily valid data).";
CM_ SG_ 1387 DistanceUnit "DATABASE_CANDIDATE: layout imported; physical meaning not independently verified. PSA-RE bits 4.7. Distance unit Upstream default raw=0 (not necessarily valid data).";
CM_ SG_ 1387 IlvAdvisedSpeed "DATABASE_CANDIDATE: layout imported; physical meaning not independently verified. PSA-RE bits 3.7-3.0. ILV advised speed Raw invalid=255; numeric DBC decoders may still scale it: check raw before use. Upstream default raw=255 (not necessarily valid data).";
CM_ SG_ 1387 HeadlampBeamSelectControl "DATABASE_CANDIDATE: layout imported; physical meaning not independently verified. PSA-RE bits 2.0. Headlamp beam selector control (low beam or high beam position) Upstream default raw=0 (not necessarily valid data).";
CM_ SG_ 1387 FrontFogLightControl "DATABASE_CANDIDATE: layout imported; physical meaning not independently verified. PSA-RE bits 2.2-2.1. Front fog light / additional light control Upstream default raw=0 (not necessarily valid data).";
CM_ SG_ 1387 IlvAuthorization "DATABASE_CANDIDATE: layout imported; physical meaning not independently verified. PSA-RE bits 2.3. ILV function authorization Upstream default raw=0 (not necessarily valid data).";
CM_ SG_ 1387 CafrValidationCommand "DATABASE_CANDIDATE: layout imported; physical meaning not independently verified. PSA-RE bits 2.4. CAFR validation command Upstream default raw=0 (not necessarily valid data).";
CM_ SG_ 1387 FrontWiperState "DATABASE_CANDIDATE: layout imported; physical meaning not independently verified. PSA-RE bits 2.6-2.5. Front wiper state Upstream default raw=0 (not necessarily valid data).";
CM_ SG_ 1387 WashCycleIndicator "DATABASE_CANDIDATE: layout imported; physical meaning not independently verified. PSA-RE bits 2.7. Washing cycle indicator Upstream default raw=0 (not necessarily valid data).";
CM_ SG_ 1387 RainSensorSensitivityRequested "DATABASE_CANDIDATE: layout imported; physical meaning not independently verified. PSA-RE bits 1.2-1.0. Requested rain sensor sensitivity Upstream default raw=0 (not necessarily valid data).";
CM_ SG_ 1387 ManualWipeRequest "DATABASE_CANDIDATE: layout imported; physical meaning not independently verified. PSA-RE bits 1.3. Manual wiping request Upstream default raw=0 (not necessarily valid data).";
CM_ SG_ 1387 AutoWipeMode "DATABASE_CANDIDATE: layout imported; physical meaning not independently verified. PSA-RE bits 1.4. Automatic wiping mode active Upstream default raw=0 (not necessarily valid data).";
CM_ SG_ 1387 StlSystemStatus "DATABASE_CANDIDATE: layout imported; physical meaning not independently verified. PSA-RE bits 1.7-1.5. Lane departure warning system (STL) status. Upstream default raw=4 (not necessarily valid data).";
CM_ BO_ 1390 "Observed OBD 6/14 HS1. CAN ID 0x56E; ID_DLC_match. PSA-RE name: BSI_CABIN_DATA_14. Body controller cabin data: hybrid blower setpoint, load-shedding requests for ABS/ESP, electric power steering, EasyMove and suspension, demisting request and hybrid zero-emission cabin inhibition. Source: https://github.com/prototux/PSA-RE/blob/67f7581e7622410efdbb29c7eda3b86982b9b450/buses/AEE2010.full/HS.HS1/56E.yml. Database sender alternatives: BSI. ECU labels are database claims; forwarding/physical transmitter not independently identified. All fitting source fields retained, including default/unavailable-only candidates. See audit/source JSON for exclusions and unresolved alternatives.";
CM_ SG_ 1390 Unused1 "DATABASE_CANDIDATE: layout imported; physical meaning not independently verified. PSA-RE bits 6.6-6.0. ";
CM_ SG_ 1390 FreewheelingAuthorizationBsi "DATABASE_CANDIDATE: layout imported; physical meaning not independently verified. PSA-RE bits 6.7. BSI authorization for the freewheeling function Upstream default raw=0 (not necessarily valid data).";
CM_ SG_ 1390 FrameChecksum56e "DATABASE_CANDIDATE: layout imported; physical meaning not independently verified. PSA-RE bits 5.3-5.0. Checksum of frame 0x56E (initial value 0xD)";
CM_ SG_ 1390 ProcessCounter56e "DATABASE_CANDIDATE: layout imported; physical meaning not independently verified. PSA-RE bits 5.7-5.4. 4-bit rolling process counter of frame 0x56E Upstream default raw=0 (not necessarily valid data).";
CM_ SG_ 1390 AcceleratorPedalPosition "DATABASE_CANDIDATE: layout imported; physical meaning not independently verified. PSA-RE bits 4.7-4.0. Accelerator pedal position Raw invalid=255; numeric DBC decoders may still scale it: check raw before use. Upstream default raw=0 (not necessarily valid data).";
CM_ SG_ 1390 ElectricCompressorCurrent "DATABASE_CANDIDATE: layout imported; physical meaning not independently verified. PSA-RE bits 2.0-3.0. Electric compressor current consumption Raw invalid=511; numeric DBC decoders may still scale it: check raw before use. Upstream default raw=0 (not necessarily valid data).";
CM_ SG_ 1390 BrakeSwitch2StuckPressedFault "DATABASE_CANDIDATE: layout imported; physical meaning not independently verified. PSA-RE bits 2.1. Main brake pedal switch 2 stuck-pressed fault Upstream default raw=0 (not necessarily valid data).";
CM_ SG_ 1390 BrakeSwitch2StuckReleasedFault "DATABASE_CANDIDATE: layout imported; physical meaning not independently verified. PSA-RE bits 2.2. Main brake pedal switch 2 stuck-released fault Upstream default raw=0 (not necessarily valid data).";
CM_ SG_ 1390 BrakeSwitch1StuckPressedFault "DATABASE_CANDIDATE: layout imported; physical meaning not independently verified. PSA-RE bits 2.3. Main brake pedal switch 1 stuck-pressed fault Upstream default raw=0 (not necessarily valid data).";
CM_ SG_ 1390 BrakeSwitch1StuckReleasedFault "DATABASE_CANDIDATE: layout imported; physical meaning not independently verified. PSA-RE bits 2.4. Main brake pedal switch 1 stuck-released fault Upstream default raw=0 (not necessarily valid data).";
CM_ SG_ 1390 BrakeDiagReleasedWindowReached "DATABASE_CANDIDATE: layout imported; physical meaning not independently verified. PSA-RE bits 2.5. Diagnostic window reached status for the brake pedal switch stuck-released test (deceleration diagnostic) Upstream default raw=0 (not necessarily valid data).";
CM_ SG_ 1390 CmmDynamicModeSetpoint "DATABASE_CANDIDATE: layout imported; physical meaning not independently verified. PSA-RE bits 2.7-2.6. Dynamic mode setpoint for the CMM (normal, sport, eco, snow) Upstream default raw=0 (not necessarily valid data).";
CM_ SG_ 1390 BrakeDiagPressedWindowReached "DATABASE_CANDIDATE: layout imported; physical meaning not independently verified. PSA-RE bits 1.0. Diagnostic window reached status for the brake pedal switch stuck-pressed test (acceleration diagnostic) Upstream default raw=0 (not necessarily valid data).";
CM_ SG_ 1390 HybridModeSetpoint "DATABASE_CANDIDATE: layout imported; physical meaning not independently verified. PSA-RE bits 1.2-1.1. Hybrid mode setpoint (EAWD, sport, auto, ZEV) Upstream default raw=2 (not necessarily valid data).";
CM_ SG_ 1390 DaynightStatus "DATABASE_CANDIDATE: layout imported; physical meaning not independently verified. PSA-RE bits 1.3. Day/night state Upstream default raw=0 (not necessarily valid data).";
CM_ SG_ 1390 Brightness "DATABASE_CANDIDATE: layout imported; physical meaning not independently verified. PSA-RE bits 1.7-1.4. Brightness level to apply (0 = minimum, 15 = maximum) Upstream default raw=8 (not necessarily valid data).";
CM_ BO_ 1394 "Observed OBD 6/14 HS1. CAN ID 0x572; ID_DLC_match. PSA-RE name: BSI_CABIN_DATA_15. Body controller cabin data: hybrid blower setpoint, load-shedding requests for ABS/ESP, electric power steering, EasyMove and suspension, demisting request and hybrid zero-emission cabin inhibition. Source: https://github.com/prototux/PSA-RE/blob/67f7581e7622410efdbb29c7eda3b86982b9b450/buses/AEE2010.full/HS.HS1/572.yml. Database sender alternatives: BSI. ECU labels are database claims; forwarding/physical transmitter not independently identified. All fitting source fields retained, including default/unavailable-only candidates. See audit/source JSON for exclusions and unresolved alternatives.";
CM_ SG_ 1394 DmtrBatteryCurrent "DATABASE_CANDIDATE: layout imported; physical meaning not independently verified. PSA-RE bits 8.7-8.0. Battery current measured by the DMTR Raw invalid=255; numeric DBC decoders may still scale it: check raw before use. Upstream default raw=0 (not necessarily valid data).";
CM_ SG_ 1394 GeiNeedsGroup3 "DATABASE_CANDIDATE: layout imported; physical meaning not independently verified. PSA-RE bits 7.7-7.0. Group 3 of power reduction needs from the electrical system quality management (GEI) Upstream default raw=0 (not necessarily valid data).";
CM_ SG_ 1394 GeiNeedsGroup2 "DATABASE_CANDIDATE: layout imported; physical meaning not independently verified. PSA-RE bits 6.7-6.0. Group 2 of power reduction needs from the electrical system quality management (GEI) Upstream default raw=0 (not necessarily valid data).";
CM_ SG_ 1394 GeiNeedsGroup1 "DATABASE_CANDIDATE: layout imported; physical meaning not independently verified. PSA-RE bits 5.7-5.0. Group 1 of power reduction needs from the electrical system quality management (GEI) Upstream default raw=0 (not necessarily valid data).";
CM_ SG_ 1394 Unused1 "DATABASE_CANDIDATE: layout imported; physical meaning not independently verified. PSA-RE bits 4.0. ";
CM_ SG_ 1394 AfsFunctionState "DATABASE_CANDIDATE: layout imported; physical meaning not independently verified. PSA-RE bits 4.4-4.1. Adaptive Frontlight System (AFS) function state Upstream default raw=0 (not necessarily valid data).";
CM_ SG_ 1394 BatteryRestartPredictedVoltage "DATABASE_CANDIDATE: layout imported; physical meaning not independently verified. PSA-RE bits 3.7-4.5. Predicted 12V battery voltage at restart Raw invalid=2047; numeric DBC decoders may still scale it: check raw before use. Upstream default raw=0 (not necessarily valid data).";
CM_ SG_ 1394 EngineStopImpactScreenInhibit "DATABASE_CANDIDATE: layout imported; physical meaning not independently verified. PSA-RE bits 2.0. Impact detected during engine stop (screen inhibition) Upstream default raw=0 (not necessarily valid data).";
CM_ SG_ 1394 StubbedSignal1 "DATABASE_CANDIDATE: layout imported; physical meaning not independently verified. PSA-RE bits 2.1. Removed signal, stubbed to a fixed value Upstream default raw=0 (not necessarily valid data).";
CM_ SG_ 1394 BatteryVoltageSensorFault "DATABASE_CANDIDATE: layout imported; physical meaning not independently verified. PSA-RE bits 2.2. 12V battery voltage sensor fault Upstream default raw=0 (not necessarily valid data).";
CM_ SG_ 1394 BatteryTemperatureCalcFault "DATABASE_CANDIDATE: layout imported; physical meaning not independently verified. PSA-RE bits 2.3. 12V battery internal temperature calculation fault Upstream default raw=0 (not necessarily valid data).";
CM_ SG_ 1394 BatteryCurrentSensorFault "DATABASE_CANDIDATE: layout imported; physical meaning not independently verified. PSA-RE bits 2.4. 12V battery current sensor fault Upstream default raw=0 (not necessarily valid data).";
CM_ SG_ 1394 VehicleConfigurationState "DATABASE_CANDIDATE: layout imported; physical meaning not independently verified. PSA-RE bits 2.7-2.5. Vehicle configuration state (assembly, factory, inspection, storage/transport, customer) Upstream default raw=4 (not necessarily valid data).";
CM_ SG_ 1394 PassengerAirbagInhibitionStatus "DATABASE_CANDIDATE: layout imported; physical meaning not independently verified. PSA-RE bits 1.0. Passenger airbag real inhibition state Upstream default raw=0 (not necessarily valid data).";
CM_ SG_ 1394 ReverseStatus "SUPPORTED_CAPTURE: coherent changes across independent messages. PSA-RE bits 1.1. Reverse gear state";
CM_ SG_ 1394 PowertrainStateCabinSide "DATABASE_CANDIDATE: layout imported; physical meaning not independently verified. PSA-RE bits 1.3-1.2. Powertrain running state, cabin-side signal (engine off, starting, running, stopped in stop-start phase) Upstream default raw=0 (not necessarily valid data).";
CM_ SG_ 1394 BeltBucklePassenger "DATABASE_CANDIDATE: layout imported; physical meaning not independently verified. PSA-RE bits 1.5-1.4. Front passenger seatbelt buckling status Upstream default raw=0 (not necessarily valid data).";
CM_ SG_ 1394 BeltBuckleDriver "DATABASE_CANDIDATE: layout imported; physical meaning not independently verified. PSA-RE bits 1.7-1.6. Driver seatbelt buckling status Upstream default raw=0 (not necessarily valid data).";
CM_ BO_ 1411 "Observed OBD 6/14 HS1. CAN ID 0x583; ID_DLC_match. PSA-RE name: EV_BATTERY_ALERTS. High-voltage battery alert flags: overvoltage, undervoltage, overcharge, high/low state of charge, cell imbalance Source: https://github.com/prototux/PSA-RE/blob/67f7581e7622410efdbb29c7eda3b86982b9b450/buses/AEE2010.electric/HS.HS1/583.yml. Database sender alternatives: E_VCU,VCU. ECU labels are database claims; forwarding/physical transmitter not independently identified. All fitting source fields retained, including default/unavailable-only candidates. See audit/source JSON for exclusions and unresolved alternatives.";
CM_ SG_ 1411 HvBatteryVoltageProbeCount "DATABASE_CANDIDATE: layout imported; physical meaning not independently verified. PSA-RE bits 7.7-7.0. Number of voltage measurement cells on the traction battery Raw invalid=255; numeric DBC decoders may still scale it: check raw before use.";
CM_ SG_ 1411 HvBatteryTemperatureProbeCount "DATABASE_CANDIDATE: layout imported; physical meaning not independently verified. PSA-RE bits 6.7-6.0. Number of temperature probes on the traction battery Raw invalid=255; numeric DBC decoders may still scale it: check raw before use.";
CM_ SG_ 1411 RawBits38_39 "RAW. PSA-RE bits 5.1-5.0. Raw unmapped/padding bits; no physical interpretation.";
CM_ SG_ 1411 HvBatteryContactorUncomma_ee926c "DATABASE_CANDIDATE: layout imported; physical meaning not independently verified. PSA-RE bits 5.4-5.2. Cause of the HV battery contactor opening without a command";
CM_ SG_ 1411 HvBatteryOverchargeAlert "DATABASE_CANDIDATE: layout imported; physical meaning not independently verified. PSA-RE bits 5.5. HV battery charging system overcharge alarm";
CM_ SG_ 1411 HvBatteryCellConsistencyAlert "DATABASE_CANDIDATE: layout imported; physical meaning not independently verified. PSA-RE bits 5.6. HV battery cell poor consistency (imbalance) alarm";
CM_ SG_ 1411 HvBatterySocJumpAlert "DATABASE_CANDIDATE: layout imported; physical meaning not independently verified. PSA-RE bits 5.7. HV battery abrupt state-of-charge variation alarm";
CM_ SG_ 1411 HvBatteryCellUndervoltageAlert "DATABASE_CANDIDATE: layout imported; physical meaning not independently verified. PSA-RE bits 4.0. HV battery cell undervoltage alarm";
CM_ SG_ 1411 HvBatteryCellOvervoltageAlert "DATABASE_CANDIDATE: layout imported; physical meaning not independently verified. PSA-RE bits 4.1. HV battery cell overvoltage alarm";
CM_ SG_ 1411 HvBatteryHighSocAlert "DATABASE_CANDIDATE: layout imported; physical meaning not independently verified. PSA-RE bits 4.2. HV battery high state-of-charge alarm";
CM_ SG_ 1411 HvBatteryLowSocAlert "DATABASE_CANDIDATE: layout imported; physical meaning not independently verified. PSA-RE bits 4.3. HV battery low state-of-charge alarm";
CM_ SG_ 1411 HvBatteryOvervoltageAlert "DATABASE_CANDIDATE: layout imported; physical meaning not independently verified. PSA-RE bits 4.4. HV battery charging system overvoltage alarm";
CM_ SG_ 1411 HvBatteryHighTemperatureAlert "DATABASE_CANDIDATE: layout imported; physical meaning not independently verified. PSA-RE bits 4.5. HV battery high temperature alarm";
CM_ SG_ 1411 HvBatteryTemperatureDiffe_70ad26 "DATABASE_CANDIDATE: layout imported; physical meaning not independently verified. PSA-RE bits 4.6. HV battery temperature difference alarm";
CM_ SG_ 1411 HvBatteryInconsistentAlert "DATABASE_CANDIDATE: layout imported; physical meaning not independently verified. PSA-RE bits 4.7. HV battery charging system inconsistency alert";
CM_ SG_ 1411 HvBatteryTemperatureMin "DATABASE_CANDIDATE: layout imported; physical meaning not independently verified. PSA-RE bits 3.7-3.0. Minimum HV battery temperature, among all sensors (°C) Raw invalid=255; numeric DBC decoders may still scale it: check raw before use.";
CM_ SG_ 1411 HvBatteryProbeNumberTempMin "DATABASE_CANDIDATE: layout imported; physical meaning not independently verified. PSA-RE bits 2.7-2.0. Number of the temperature probe reading the minimum temperature Raw invalid=255; numeric DBC decoders may still scale it: check raw before use.";
CM_ SG_ 1411 HvBatteryProbeNumberTempMax "DATABASE_CANDIDATE: layout imported; physical meaning not independently verified. PSA-RE bits 1.7-1.0. Number of the temperature probe reading the maximum temperature Raw invalid=255; numeric DBC decoders may still scale it: check raw before use.";
CM_ BO_ 1416 "Observed OBD 6/14 HS1. CAN ID 0x588; ID_DLC_match. PSA-RE name: ENGINE_DATA. Engine data 2: oil pressure alert, additive pump control, warning LED commands, software fault, water pump status, stop-start state, eco-driving indicator and oil level. Source: https://github.com/prototux/PSA-RE/blob/67f7581e7622410efdbb29c7eda3b86982b9b450/buses/AEE2010.full/HS.HS1/588.yml. Database sender alternatives: CMM. ECU labels are database claims; forwarding/physical transmitter not independently identified. All fitting source fields retained, including default/unavailable-only candidates. See audit/source JSON for exclusions and unresolved alternatives.";
CM_ SG_ 1416 LifeSituation "DATABASE_CANDIDATE: layout imported; physical meaning not independently verified. PSA-RE bits 8.2-8.0. Vehicle life/usage situation (SVV1 to SVV5) Upstream default raw=0 (not necessarily valid data).";
CM_ SG_ 1416 GearChangeDirection "DATABASE_CANDIDATE: layout imported; physical meaning not independently verified. PSA-RE bits 8.4-8.3. Gear change direction (upshift, downshift, confirmed) Upstream default raw=0 (not necessarily valid data).";
CM_ SG_ 1416 GearboxTargetRatioTransmitted "DATABASE_CANDIDATE: layout imported; physical meaning not independently verified. PSA-RE bits 8.7-8.5. Transmitted target gear ratio Upstream default raw=0 (not necessarily valid data).";
CM_ SG_ 1416 EngineOperatingMode "DATABASE_CANDIDATE: layout imported; physical meaning not independently verified. PSA-RE bits 7.3-7.0. Engine operating mode state Upstream default raw=0 (not necessarily valid data).";
CM_ SG_ 1416 AdditivePumpControlEnabled "DATABASE_CANDIDATE: layout imported; physical meaning not independently verified. PSA-RE bits 7.4. Additive pump control authorized Upstream default raw=0 (not necessarily valid data).";
CM_ SG_ 1416 DmtcChargeState "DATABASE_CANDIDATE: layout imported; physical meaning not independently verified. PSA-RE bits 7.5. DMTC state of charge Upstream default raw=1 (not necessarily valid data).";
CM_ SG_ 1416 DeferredStopSyncInfo "DATABASE_CANDIDATE: layout imported; physical meaning not independently verified. PSA-RE bits 7.6. Deferred stop synchronization information Upstream default raw=0 (not necessarily valid data).";
CM_ SG_ 1416 CmmReadinessCodeStatus "DATABASE_CANDIDATE: layout imported; physical meaning not independently verified. PSA-RE bits 7.7. Engine ECU readiness code diagnostic state";
CM_ SG_ 1416 StopStartFunctionState "DATABASE_CANDIDATE: layout imported; physical meaning not independently verified. PSA-RE bits 6.1-6.0. Stop & start function state Upstream default raw=1 (not necessarily valid data).";
CM_ SG_ 1416 AtmosphericPressure "DATABASE_CANDIDATE: layout imported; physical meaning not independently verified. PSA-RE bits 6.6-6.2. Atmospheric pressure (hPa) Raw invalid=31; numeric DBC decoders may still scale it: check raw before use. Upstream default raw=30 (not necessarily valid data). Unresolved source alternatives: [{\"factor\": 15685, \"note\": \"Also observed with another scaling (factor 15685)\"}]";
CM_ SG_ 1416 EcmSafetyFault "DATABASE_CANDIDATE: layout imported; physical meaning not independently verified. PSA-RE bits 6.7. Engine control module safety fault Upstream default raw=0 (not necessarily valid data).";
CM_ SG_ 1416 CalculatedEngineLoad "DATABASE_CANDIDATE: layout imported; physical meaning not independently verified. PSA-RE bits 5.7-5.0. Calculated engine load value (%) Upstream default raw=0 (not necessarily valid data). Unresolved source alternatives: [{\"factor\": 0.392, \"note\": \"Also observed with another scaling (factor 0.392)\"}]";
CM_ SG_ 1416 PseudoFuelConsumption "DATABASE_CANDIDATE: layout imported; physical meaning not independently verified. PSA-RE bits 4.7-4.0. Fuel consumption excluding particulate filter regeneration (pilot + main injection only) Upstream default raw=0 (not necessarily valid data).";
CM_ SG_ 1416 OilPressureAlertLamp "DATABASE_CANDIDATE: layout imported; physical meaning not independently verified. PSA-RE bits 3.0. Turns on a warning lamp to signal an engine oil pressure fault Upstream default raw=0 (not necessarily valid data).";
CM_ SG_ 1416 NeutralDisplayRequestGsi "DATABASE_CANDIDATE: layout imported; physical meaning not independently verified. PSA-RE bits 3.1. Powertrain request to display neutral via the GSI function Upstream default raw=0 (not necessarily valid data).";
CM_ SG_ 1416 ValvetronicPowerCommand "DATABASE_CANDIDATE: layout imported; physical meaning not independently verified. PSA-RE bits 3.2. Valvetronic power command Upstream default raw=0 (not necessarily valid data).";
CM_ SG_ 1416 WaterPumpState "DATABASE_CANDIDATE: layout imported; physical meaning not independently verified. PSA-RE bits 3.3. Water pump state Upstream default raw=0 (not necessarily valid data).";
CM_ SG_ 1416 RedLedRequest "DATABASE_CANDIDATE: layout imported; physical meaning not independently verified. PSA-RE bits 3.4. Red LED request, signalling approach of maximum engine speed Upstream default raw=0 (not necessarily valid data).";
CM_ SG_ 1416 OrangeLedRequest "DATABASE_CANDIDATE: layout imported; physical meaning not independently verified. PSA-RE bits 3.5. Orange LED request, signalling approach of maximum engine power Upstream default raw=0 (not necessarily valid data).";
CM_ SG_ 1416 ClutchDisplayRequest "DATABASE_CANDIDATE: layout imported; physical meaning not independently verified. PSA-RE bits 3.6. HMI request to display clutch disengagement Upstream default raw=0 (not necessarily valid data).";
CM_ SG_ 1416 StopStartAvailableBlinkRequest "DATABASE_CANDIDATE: layout imported; physical meaning not independently verified. PSA-RE bits 3.7. Stop & Start availability indicator blink request Upstream default raw=0 (not necessarily valid data).";
CM_ SG_ 1416 AdditiveVolumeToAdd "DATABASE_CANDIDATE: layout imported; physical meaning not independently verified. PSA-RE bits 2.7-2.0. Additive volume to add Raw invalid=255; numeric DBC decoders may still scale it: check raw before use. Upstream default raw=255 (not necessarily valid data).";
CM_ SG_ 1416 EngineOilLevel "DATABASE_CANDIDATE: layout imported; physical meaning not independently verified. PSA-RE bits 1.7-1.0. Engine oil level (sensor voltage) Raw invalid=255; numeric DBC decoders may still scale it: check raw before use. Upstream default raw=254 (not necessarily valid data).";
CM_ BO_ 1422 "Observed OBD 6/14 HS1. CAN ID 0x58E; ID_DLC_match. PSA-RE name: RITCS_VENT_TEMPERATURE. RITCS blown-air temperature: front and rear, left and right vents. Source: https://github.com/prototux/PSA-RE/blob/67f7581e7622410efdbb29c7eda3b86982b9b450/buses/AEE2010.full/HS.HS1/58E.yml. Database sender alternatives: BSI. ECU labels are database claims; forwarding/physical transmitter not independently identified. All fitting source fields retained, including default/unavailable-only candidates. See audit/source JSON for exclusions and unresolved alternatives.";
CM_ SG_ 1422 LeftBlownAirTemperature "DATABASE_CANDIDATE: layout imported; physical meaning not independently verified. PSA-RE bits 7.7-8.0. Left blown air temperature Raw invalid=65535; numeric DBC decoders may still scale it: check raw before use. Upstream default raw=65535 (not necessarily valid data).";
CM_ SG_ 1422 RightBlownAirTemperature "DATABASE_CANDIDATE: layout imported; physical meaning not independently verified. PSA-RE bits 5.7-6.0. Right blown air temperature Raw invalid=65535; numeric DBC decoders may still scale it: check raw before use. Upstream default raw=65535 (not necessarily valid data).";
CM_ SG_ 1422 RearLeftBlownAirTemperature "DATABASE_CANDIDATE: layout imported; physical meaning not independently verified. PSA-RE bits 3.7-4.0. Rear left blown air temperature Raw invalid=65535; numeric DBC decoders may still scale it: check raw before use. Upstream default raw=65535 (not necessarily valid data).";
CM_ SG_ 1422 RearRightBlownAirTemperature "DATABASE_CANDIDATE: layout imported; physical meaning not independently verified. PSA-RE bits 1.7-2.0. Rear right blown air temperature Raw invalid=65535; numeric DBC decoders may still scale it: check raw before use. Upstream default raw=65535 (not necessarily valid data).";
CM_ BO_ 1430 "Observed OBD 6/14 HS1. CAN ID 0x596; ID_DLC_match. PSA-RE name: CAMERA_LANE_TRACKING_DATA_5. Camera lane-tracking data: lead-vehicle lane-crossing flags, cluster angle/distance left and right, minimum cluster distance/angle and perception status. Source: https://github.com/prototux/PSA-RE/blob/67f7581e7622410efdbb29c7eda3b86982b9b450/buses/AEE2010.full/HS.HS1/596.yml. Database sender alternatives: CVM. ECU labels are database claims; forwarding/physical transmitter not independently identified. All fitting source fields retained, including default/unavailable-only candidates. See audit/source JSON for exclusions and unresolved alternatives.";
CM_ SG_ 1430 Unused1 "DATABASE_CANDIDATE: layout imported; physical meaning not independently verified. PSA-RE bits 4.3-4.0. ";
CM_ SG_ 1430 ConditionalSpeedSignType "DATABASE_CANDIDATE: layout imported; physical meaning not independently verified. PSA-RE bits 4.5-4.4. Type of conditional speed limit sign read by the camera (start/end of section, invalid, undefined) Upstream default raw=2 (not necessarily valid data).";
CM_ SG_ 1430 CameraImplicitSpeedRobustFlag "DATABASE_CANDIDATE: layout imported; physical meaning not independently verified. PSA-RE bits 4.6. Robustness flag for the implicit speed limit read by the camera Upstream default raw=0 (not necessarily valid data).";
CM_ SG_ 1430 CameraConditionalSpeedRobustFlag "DATABASE_CANDIDATE: layout imported; physical meaning not independently verified. PSA-RE bits 4.7. Robustness flag for the conditional speed limit read by the camera Upstream default raw=0 (not necessarily valid data).";
CM_ SG_ 1430 ImplicitSpeedLimitType "DATABASE_CANDIDATE: layout imported; physical meaning not independently verified. PSA-RE bits 3.3-3.0. Type of implicit speed limit event (entering/leaving a meeting zone, entering/leaving a built-up area) Upstream default raw=15 (not necessarily valid data).";
CM_ SG_ 1430 CameraImplicitSpeedRobust_c30930 "DATABASE_CANDIDATE: layout imported; physical meaning not independently verified. PSA-RE bits 3.7-3.4. Distance travelled used to assess robustness of the implicit speed limit read by the camera (m) Upstream default raw=14 (not necessarily valid data).";
CM_ SG_ 1430 ConditionalSpeedLimitContext "DATABASE_CANDIDATE: layout imported; physical meaning not independently verified. PSA-RE bits 2.3-2.0. Context of the conditional speed limit read by the camera (trailer, rain, snow, school zone...) Upstream default raw=15 (not necessarily valid data).";
CM_ SG_ 1430 CameraConditionalSpeedRob_82bfe5 "DATABASE_CANDIDATE: layout imported; physical meaning not independently verified. PSA-RE bits 2.7-2.4. Distance travelled used to assess robustness of the conditional speed limit read by the camera (m) Upstream default raw=14 (not necessarily valid data).";
CM_ SG_ 1430 ConditionalSpeedLimitCamera "DATABASE_CANDIDATE: layout imported; physical meaning not independently verified. PSA-RE bits 1.7-1.0. Conditional speed limit read by the camera (km/h) Upstream default raw=254 (not necessarily valid data).";
CM_ BO_ 1432 "Observed OBD 6/14 HS1. CAN ID 0x598; ID_DLC_match. PSA-RE name: ENGINE_DATA_2. Engine data 2: oil pressure alert, additive pump control, warning LED commands, software fault, water pump status, stop-start state, eco-driving indicator and oil level. Source: https://github.com/prototux/PSA-RE/blob/67f7581e7622410efdbb29c7eda3b86982b9b450/buses/AEE2010.full/HS.HS1/598.yml. Database sender alternatives: CMM,E_VCU. ECU labels are database claims; forwarding/physical transmitter not independently identified. All fitting source fields retained, including default/unavailable-only candidates. See audit/source JSON for exclusions and unresolved alternatives.";
CM_ SG_ 1432 Unused1 "DATABASE_CANDIDATE: layout imported; physical meaning not independently verified. PSA-RE bits 2.6-4.0. ";
CM_ SG_ 1432 CatalystHeaterDiagEnable "DATABASE_CANDIDATE: layout imported; physical meaning not independently verified. PSA-RE bits 2.7. Catalytic converter heating strategy diagnostic activation Upstream default raw=0 (not necessarily valid data).";
CM_ SG_ 1432 FuelFlapOpenAuthorized "DATABASE_CANDIDATE: layout imported; physical meaning not independently verified. PSA-RE bits 1.0. Fuel flap opening authorized Upstream default raw=0 (not necessarily valid data).";
CM_ SG_ 1432 CoolantTempSensorDiag "DATABASE_CANDIDATE: layout imported; physical meaning not independently verified. PSA-RE bits 1.2-1.1. Coolant temperature sensor diagnostic Upstream default raw=0 (not necessarily valid data).";
CM_ SG_ 1432 AtmosphericPressureHighAltitude "DATABASE_CANDIDATE: layout imported; physical meaning not independently verified. PSA-RE bits 1.7-1.3. Atmospheric pressure at high altitude (hPa) Raw invalid=31; numeric DBC decoders may still scale it: check raw before use. Upstream default raw=30 (not necessarily valid data). Unresolved source alternatives: [{\"factor\": 20685, \"note\": \"Also observed with another scaling (factor 20685)\"}]";
CM_ BO_ 1442 "Observed OBD 6/14 HS1. CAN ID 0x5A2; ID_DLC_match. PSA-RE name: VCU_DRIVE_MODE_CAPABILITIES_5. Vehicle control unit data: available driving modes (normal, sport, eco, snow...), energy modes (hybrid, zero-emission, fuel) and drive-axle modes (auto, front, rear), plus cooling wake-up requests. Source: https://github.com/prototux/PSA-RE/blob/67f7581e7622410efdbb29c7eda3b86982b9b450/buses/AEE2010.electric/HS.HS1/5A2.yml. Database sender alternatives: VCU,E_VCU. ECU labels are database claims; forwarding/physical transmitter not independently identified. All fitting source fields retained, including default/unavailable-only candidates. See audit/source JSON for exclusions and unresolved alternatives.";
CM_ SG_ 1442 RawByte7 "RAW. PSA-RE bits 7.7-7.0. Raw unmapped/padding bits; no physical interpretation.";
CM_ SG_ 1442 RawByte6 "RAW. PSA-RE bits 6.7-6.0. Raw unmapped/padding bits; no physical interpretation.";
CM_ SG_ 1442 RawByte5 "RAW. PSA-RE bits 5.7-5.0. Raw unmapped/padding bits; no physical interpretation.";
CM_ SG_ 1442 PreconditioningState "DATABASE_CANDIDATE: layout imported; physical meaning not independently verified. PSA-RE bits 4.0. Preconditioning state Upstream default raw=1 (not necessarily valid data). Unresolved source alternatives: [{\"bits\": \"3.5\", \"note\": \"Also observed at bits 3.5\"}]";
CM_ SG_ 1442 HvBatteryChargeRemainingTime "DATABASE_CANDIDATE: layout imported; physical meaning not independently verified. PSA-RE bits 4.7-4.1. HV battery remaining charge time Raw invalid=127; numeric DBC decoders may still scale it: check raw before use. Upstream default raw=0 (not necessarily valid data). Unresolved source alternatives: [{\"bits\": \"4.7-4.0\", \"factor\": 5, \"note\": \"Also observed at bits 4.7-4.0. Also observed with another scaling (factor 5)\"}]";
CM_ SG_ 1442 Unused1 "DATABASE_CANDIDATE: layout imported; physical meaning not independently verified. PSA-RE bits 3.5-3.0. ";
CM_ SG_ 1442 ChargePushButtonPressed "DATABASE_CANDIDATE: layout imported; physical meaning not independently verified. PSA-RE bits 3.6. Charge port push-button pressed Upstream default raw=0 (not necessarily valid data).";
CM_ SG_ 1442 ChillerActivationRequest "DATABASE_CANDIDATE: layout imported; physical meaning not independently verified. PSA-RE bits 3.7. Chiller activation request Upstream default raw=0 (not necessarily valid data).";
CM_ SG_ 1442 BatteryShortLoopCoolantTe_a7250e "DATABASE_CANDIDATE: layout imported; physical meaning not independently verified. PSA-RE bits 2.7-2.0. Requested coolant temperature on the short loop for battery cooling Raw invalid=255; numeric DBC decoders may still scale it: check raw before use.";
CM_ SG_ 1442 HvBatteryCoolantTemperature "DATABASE_CANDIDATE: layout imported; physical meaning not independently verified. PSA-RE bits 1.7-1.0. HV battery coolant temperature Raw invalid=255; numeric DBC decoders may still scale it: check raw before use. Upstream default raw=40 (not necessarily valid data).";
CM_ BO_ 1443 "Observed OBD 6/14 HS1. CAN ID 0x5A3; ID_DLC_match. PSA-RE name: EV_BATTERY_CELL_VOLTAGES. High-voltage battery cell voltage extremes and insulation resistance Source: https://github.com/prototux/PSA-RE/blob/67f7581e7622410efdbb29c7eda3b86982b9b450/buses/AEE2010.electric/HS.HS1/5A3.yml. Database sender alternatives: E_VCU,VCU. ECU labels are database claims; forwarding/physical transmitter not independently identified. All fitting source fields retained, including default/unavailable-only candidates. See audit/source JSON for exclusions and unresolved alternatives.";
CM_ SG_ 1443 RawBits62_63 "RAW. PSA-RE bits 8.1-8.0. Raw unmapped/padding bits; no physical interpretation.";
CM_ SG_ 1443 MinCellVoltage "DATABASE_CANDIDATE: layout imported; physical meaning not independently verified. PSA-RE bits 7.7-8.2. Minimum cell voltage of the HV battery (V) Raw invalid=16383; numeric DBC decoders may still scale it: check raw before use.";
CM_ SG_ 1443 MinVoltageCellIndexCandidate "DATABASE_CANDIDATE: layout imported; physical meaning not independently verified. PSA-RE bits 6.7-6.0. Number of the cell with the minimum voltage Upstream factor 11 produces indices outside a demonstrated 108-cell pack; retain raw factor 1 as candidate, physical ordering unverified. Raw invalid=255; numeric DBC decoders may still scale it: check raw before use.";
CM_ SG_ 1443 RawBits38_39 "RAW. PSA-RE bits 5.1-5.0. Raw unmapped/padding bits; no physical interpretation.";
CM_ SG_ 1443 MaxCellVoltage "DATABASE_CANDIDATE: layout imported; physical meaning not independently verified. PSA-RE bits 4.7-5.2. Maximum cell voltage of the HV battery (V) Raw invalid=16383; numeric DBC decoders may still scale it: check raw before use.";
CM_ SG_ 1443 MaxVoltageCellIndexCandidate "DATABASE_CANDIDATE: layout imported; physical meaning not independently verified. PSA-RE bits 3.7-3.0. Number of the cell with the maximum voltage Upstream factor 11 produces indices outside a demonstrated 108-cell pack; retain raw factor 1 as candidate, physical ordering unverified. Raw invalid=255; numeric DBC decoders may still scale it: check raw before use.";
CM_ SG_ 1443 BatteryInsulationResistance "DATABASE_CANDIDATE: layout imported; physical meaning not independently verified. PSA-RE bits 1.7-2.0. HV battery insulation resistance (kOhm) Raw invalid=65535; numeric DBC decoders may still scale it: check raw before use.";
CM_ BO_ 1454 "Observed OBD 6/14 HS1. CAN ID 0x5AE; ID_DLC_match. PSA-RE name: RITCS_DATA. RITCS data 2: blower motor faults, AC compressor and low-beam status, eCall crash trigger, washer fluid level alert, and cruise-control/speed-limiter selection buttons. Source: https://github.com/prototux/PSA-RE/blob/67f7581e7622410efdbb29c7eda3b86982b9b450/buses/AEE2010.full/HS.HS1/5AE.yml. Database sender alternatives: BSI. ECU labels are database claims; forwarding/physical transmitter not independently identified. All fitting source fields retained, including default/unavailable-only candidates. See audit/source JSON for exclusions and unresolved alternatives.";
CM_ SG_ 1454 RawBits36_39 "RAW. PSA-RE bits 5.3-5.0. Raw unmapped/padding bits; no physical interpretation.";
CM_ SG_ 1454 SpeedLimiterCruiseSetpointPlus "DATABASE_CANDIDATE: layout imported; physical meaning not independently verified. PSA-RE bits 5.4. Cruise/limiter speed setpoint increment Upstream default raw=0 (not necessarily valid data).";
CM_ SG_ 1454 SpeedLimiterCruiseSetpointMinus "DATABASE_CANDIDATE: layout imported; physical meaning not independently verified. PSA-RE bits 5.5. Cruise/limiter speed setpoint decrement Upstream default raw=0 (not necessarily valid data).";
CM_ SG_ 1454 SpeedLimiterSelectButtonState "DATABASE_CANDIDATE: layout imported; physical meaning not independently verified. PSA-RE bits 5.6. Speed limiter (speed limiter) selection button state Upstream default raw=0 (not necessarily valid data).";
CM_ SG_ 1454 SpeedLimiterCruiseDeselectButton "DATABASE_CANDIDATE: layout imported; physical meaning not independently verified. PSA-RE bits 5.7. Speed limiter/cruise control deselection push button state Upstream default raw=0 (not necessarily valid data).";
CM_ SG_ 1454 EngineCoolantLevelWarning "DATABASE_CANDIDATE: layout imported; physical meaning not independently verified. PSA-RE bits 4.0. Engine coolant level warning state Upstream default raw=0 (not necessarily valid data).";
CM_ SG_ 1454 CompressorCapacityControlDiag "DATABASE_CANDIDATE: layout imported; physical meaning not independently verified. PSA-RE bits 4.3-4.1. Variable-capacity compressor control diagnostic Upstream default raw=0 (not necessarily valid data).";
CM_ SG_ 1454 LeftLowBeamDiag "DATABASE_CANDIDATE: layout imported; physical meaning not independently verified. PSA-RE bits 4.5-4.4. Left low beam diagnostic Upstream default raw=0 (not necessarily valid data).";
CM_ SG_ 1454 RightLowBeamDiag "DATABASE_CANDIDATE: layout imported; physical meaning not independently verified. PSA-RE bits 4.7-4.6. Right low beam diagnostic Upstream default raw=0 (not necessarily valid data).";
CM_ SG_ 1454 AutomaticEcallTrigger "DATABASE_CANDIDATE: layout imported; physical meaning not independently verified. PSA-RE bits 3.1-3.0. Sending an automatic eCall after a detected impact Upstream default raw=1 (not necessarily valid data).";
CM_ SG_ 1454 AcCompressorDiag "DATABASE_CANDIDATE: layout imported; physical meaning not independently verified. PSA-RE bits 3.4-3.2. Air conditioning compressor diagnostic Upstream default raw=0 (not necessarily valid data).";
CM_ SG_ 1454 RawBits18_18 "RAW. PSA-RE bits 3.5-3.5. Raw unmapped/padding bits; no physical interpretation.";
CM_ SG_ 1454 FrontBlowerMotorFault "DATABASE_CANDIDATE: layout imported; physical meaning not independently verified. PSA-RE bits 3.6. Front blower motor fault Upstream default raw=0 (not necessarily valid data).";
CM_ SG_ 1454 RearLeftBlowerMotorFault "DATABASE_CANDIDATE: layout imported; physical meaning not independently verified. PSA-RE bits 3.7. Rear left (or default) blower motor fault Upstream default raw=0 (not necessarily valid data).";
CM_ SG_ 1454 EvaporatorSensorTemperature "DATABASE_CANDIDATE: layout imported; physical meaning not independently verified. PSA-RE bits 1.7-2.0. Evaporator sensor temperature Raw invalid=65535; numeric DBC decoders may still scale it: check raw before use. Upstream default raw=65535 (not necessarily valid data).";
CM_ BO_ 1458 "Observed OBD 6/14 HS1. CAN ID 0x5B2; ID_DLC_match. PSA-RE name: CONTEXT. Context data: SCR load-shedding, service interval exceeded and maintenance reset acknowledgement. Source: https://github.com/prototux/PSA-RE/blob/67f7581e7622410efdbb29c7eda3b86982b9b450/buses/AEE2010.full/HS.HS1/5B2.yml. Database sender alternatives: BSI. ECU labels are database claims; forwarding/physical transmitter not independently identified. All fitting source fields retained, including default/unavailable-only candidates. See audit/source JSON for exclusions and unresolved alternatives.";
CM_ SG_ 1458 Unused2 "DATABASE_CANDIDATE: layout imported; physical meaning not independently verified. PSA-RE bits 7.4-8.0. ";
CM_ SG_ 1458 OutsideTempSensorDiag "DATABASE_CANDIDATE: layout imported; physical meaning not independently verified. PSA-RE bits 7.6-7.5. Outside temperature sensor diagnostic Upstream default raw=0 (not necessarily valid data).";
CM_ SG_ 1458 ServiceResetOk "DATABASE_CANDIDATE: layout imported; physical meaning not independently verified. PSA-RE bits 7.7. Service reset acknowledged Upstream default raw=0 (not necessarily valid data).";
CM_ SG_ 1458 Unused1 "DATABASE_CANDIDATE: layout imported; physical meaning not independently verified. PSA-RE bits 6.0. ";
CM_ SG_ 1458 ScrLoadSheddingRequest "DATABASE_CANDIDATE: layout imported; physical meaning not independently verified. PSA-RE bits 6.7-6.1. SCR system load-shedding request Upstream default raw=100 (not necessarily valid data).";
CM_ SG_ 1458 EobdInfoStatusBsi "DATABASE_CANDIDATE: layout imported; physical meaning not independently verified. PSA-RE bits 5.7-5.0. EOBD information status as seen by the BSI Upstream default raw=0 (not necessarily valid data).";
CM_ SG_ 1458 AdditiveSystemStatus "DATABASE_CANDIDATE: layout imported; physical meaning not independently verified. PSA-RE bits 4.7-4.0. Additive (FAP) system status, used by the engine ECU for fallback strategies Upstream default raw=0 (not necessarily valid data).";
CM_ SG_ 1458 OutsideAirTemperature "DATABASE_CANDIDATE: layout imported; physical meaning not independently verified. PSA-RE bits 3.7-3.0. Outside air temperature (°C) Raw invalid=255; numeric DBC decoders may still scale it: check raw before use. Upstream default raw=252 (not necessarily valid data).";
CM_ SG_ 1458 TotalAdditiveQuantity "DATABASE_CANDIDATE: layout imported; physical meaning not independently verified. PSA-RE bits 1.7-2.0. Mass of metal additive retained in the particulate filter since commissioning Raw invalid=65535; numeric DBC decoders may still scale it: check raw before use. Upstream default raw=65535 (not necessarily valid data).";
CM_ BO_ 1473 "Observed OBD 6/14 HS1. CAN ID 0x5C1; ID_DLC_match. PSA-RE name: BML_VERSION. Electric drive status: EPS mode, high-voltage level and inverter/stator temperatures Source: https://github.com/prototux/PSA-RE/blob/67f7581e7622410efdbb29c7eda3b86982b9b450/buses/AEE2010.electric/HS.HS1/5C1.yml. Database sender alternatives: VCU. ECU labels are database claims; forwarding/physical transmitter not independently identified. All fitting source fields retained, including default/unavailable-only candidates. See audit/source JSON for exclusions and unresolved alternatives.";
CM_ SG_ 1473 EpsModeRequest "DATABASE_CANDIDATE: layout imported; physical meaning not independently verified. PSA-RE bits 8.2-8.0. Electric powertrain system (EPS) mode request (off, drive active, discharge, PI charge, PI balance)";
CM_ SG_ 1473 PemHvVoltage "DATABASE_CANDIDATE: layout imported; physical meaning not independently verified. PSA-RE bits 8.7-8.3. Front electric machine (PEM) high-voltage supply voltage (V) Raw invalid=31; numeric DBC decoders may still scale it: check raw before use.";
CM_ SG_ 1473 TractionStatorTemperature "DATABASE_CANDIDATE: layout imported; physical meaning not independently verified. PSA-RE bits 7.7-7.0. Front electric machine (PEM) stator temperature (°C) Raw invalid=255; numeric DBC decoders may still scale it: check raw before use.";
CM_ SG_ 1473 TractionInverterTemperature "DATABASE_CANDIDATE: layout imported; physical meaning not independently verified. PSA-RE bits 6.7-6.0. Front electric machine (PEM) inverter temperature (°C) Raw invalid=255; numeric DBC decoders may still scale it: check raw before use.";
CM_ SG_ 1473 RawByte5 "RAW. PSA-RE bits 5.7-5.0. Raw unmapped/padding bits; no physical interpretation.";
CM_ SG_ 1473 RawByte4 "RAW. PSA-RE bits 4.7-4.0. Raw unmapped/padding bits; no physical interpretation.";
CM_ SG_ 1473 RawByte3 "RAW. PSA-RE bits 3.7-3.0. Raw unmapped/padding bits; no physical interpretation.";
CM_ SG_ 1473 RemStatorTemperature "DATABASE_CANDIDATE: layout imported; physical meaning not independently verified. PSA-RE bits 2.7-2.0. Rear electric machine (eRAD) stator temperature (°C) Raw invalid=255; numeric DBC decoders may still scale it: check raw before use.";
CM_ SG_ 1473 RemInverterTemperature "DATABASE_CANDIDATE: layout imported; physical meaning not independently verified. PSA-RE bits 1.7-1.0. Rear electric machine (eRAD) inverter temperature (°C) Raw invalid=255; numeric DBC decoders may still scale it: check raw before use.";
CM_ BO_ 1475 "Observed OBD 6/14 HS1. CAN ID 0x5C3; ID_DLC_match. PSA-RE name: EV_DRIVE_STATUS_2. High-voltage battery status: voltage, state of charge, insulation and interlock faults Source: https://github.com/prototux/PSA-RE/blob/67f7581e7622410efdbb29c7eda3b86982b9b450/buses/AEE2010.electric/HS.HS1/5C3.yml. Database sender alternatives: VCU. ECU labels are database claims; forwarding/physical transmitter not independently identified. All fitting source fields retained, including default/unavailable-only candidates. See audit/source JSON for exclusions and unresolved alternatives.";
CM_ SG_ 1475 HvBatteryMinVoltageWarning "DATABASE_CANDIDATE: layout imported; physical meaning not independently verified. PSA-RE bits 8.0. HV battery minimum voltage warning";
CM_ SG_ 1475 HvBatteryInsulationFaultStatus "DATABASE_CANDIDATE: layout imported; physical meaning not independently verified. PSA-RE bits 8.3-8.1. HV battery insulation fault diagnostic status";
CM_ SG_ 1475 DcdcOvertemperature "DATABASE_CANDIDATE: layout imported; physical meaning not independently verified. PSA-RE bits 8.4. DC/DC converter overheating";
CM_ SG_ 1475 HvBatteryInterlockLineStatus "DATABASE_CANDIDATE: layout imported; physical meaning not independently verified. PSA-RE bits 8.6-8.5. HV traction battery interlock line status";
CM_ SG_ 1475 RemOvertemperatureFault "DATABASE_CANDIDATE: layout imported; physical meaning not independently verified. PSA-RE bits 8.7. Rear electric machine (eRAD) overheating fault";
CM_ SG_ 1475 RawByte7 "RAW. PSA-RE bits 7.7-7.0. Raw unmapped/padding bits; no physical interpretation.";
CM_ SG_ 1475 RawByte6 "RAW. PSA-RE bits 6.7-6.0. Raw unmapped/padding bits; no physical interpretation.";
CM_ SG_ 1475 RawByte5 "RAW. PSA-RE bits 5.7-5.0. Raw unmapped/padding bits; no physical interpretation.";
CM_ SG_ 1475 BatterySoc "OWNER_CONFIRMED in READY capture: speed/SOC agree with vehicle; startup values need validity gating. PSA-RE bits 3.1-4.0. HV battery state of charge (%) Raw invalid=1023; numeric DBC decoders may still scale it: check raw before use.";
CM_ SG_ 1475 RawBits16_21 "RAW. PSA-RE bits 3.7-3.2. Raw unmapped/padding bits; no physical interpretation.";
CM_ SG_ 1475 RawBits11_15 "RAW. PSA-RE bits 2.4-2.0. Raw unmapped/padding bits; no physical interpretation.";
CM_ SG_ 1475 BatteryVoltage "DATABASE_CANDIDATE: layout imported; physical meaning not independently verified. PSA-RE bits 1.7-2.5. HV battery actual voltage (V) Raw invalid=2047; numeric DBC decoders may still scale it: check raw before use.";
CM_ BO_ 1483 "Observed OBD 6/14 HS1. CAN ID 0x5CB; ID_DLC_match. PSA-RE name: CMF_SUPERVISION. Network supervision: transmission quality counters and fault presence of the sending ECU Source: https://github.com/prototux/PSA-RE/blob/67f7581e7622410efdbb29c7eda3b86982b9b450/buses/AEE2010.full/HS.HS1/5CB.yml. Database sender alternatives: CVM. ECU labels are database claims; forwarding/physical transmitter not independently identified. All fitting source fields retained, including default/unavailable-only candidates. See audit/source JSON for exclusions and unresolved alternatives.";
CM_ SG_ 1483 Unused1 "DATABASE_CANDIDATE: layout imported; physical meaning not independently verified. PSA-RE bits 8.3-8.0. ";
CM_ SG_ 1483 PartialWakeupStatusFlagsP_c242fd "DATABASE_CANDIDATE: layout imported; physical meaning not independently verified. PSA-RE bits 6.3-8.4. Per-ECU flags indicating which partial wake-up(s) are active, for both master and slave partial-wake-up ECUs. Upstream default raw=0 (not necessarily valid data).";
CM_ SG_ 1483 EcuOperatingPhase "DATABASE_CANDIDATE: layout imported; physical meaning not independently verified. PSA-RE bits 6.7-6.4. ECU (RCD) operating phase.";
CM_ SG_ 1483 EcuConfirmedAbsentStatus "DATABASE_CANDIDATE: layout imported; physical meaning not independently verified. PSA-RE bits 2.7-5.0. \"Confirmed absent\" status flags of the supervised ECUs: 0 if present, 1 if confirmed absent (0 by default for unsupervised ECUs). Upstream default raw=0 (not necessarily valid data).";
CM_ SG_ 1483 DiagnosticMemoryState "DATABASE_CANDIDATE: layout imported; physical meaning not independently verified. PSA-RE bits 1.7-1.0. State of the system's diagnostic memory. Upstream default raw=0 (not necessarily valid data).";
CM_ BO_ 1485 "Observed OBD 6/14 HS1. CAN ID 0x5CD; ID_DLC_match. PSA-RE name: WHEEL_PULSE_COUNTER_DATA_3. Wheel-speed sensor pulse counters and fault flags for each wheel. Source: https://github.com/prototux/PSA-RE/blob/67f7581e7622410efdbb29c7eda3b86982b9b450/buses/AEE2010.full/HS.HS1/5CD.yml. Database sender alternatives: ABS. ECU labels are database claims; forwarding/physical transmitter not independently identified. All fitting source fields retained, including default/unavailable-only candidates. See audit/source JSON for exclusions and unresolved alternatives.";
CM_ SG_ 1485 Unused1 "DATABASE_CANDIDATE: layout imported; physical meaning not independently verified. PSA-RE bits 4.1-4.0. ";
CM_ SG_ 1485 SteeringWheelAngleOffsetAccuracy "DATABASE_CANDIDATE: layout imported; physical meaning not independently verified. PSA-RE bits 4.7-4.2. Accuracy of the steering wheel angle offset calculation Raw invalid=63; numeric DBC decoders may still scale it: check raw before use. Upstream default raw=62 (not necessarily valid data).";
CM_ SG_ 1485 SteeringWheelAngleOffset "DATABASE_CANDIDATE: layout imported; physical meaning not independently verified. PSA-RE bits 2.7-3.0. Offset used to compute the steering wheel angle from the column angle Raw invalid=32767; numeric DBC decoders may still scale it: check raw before use. Upstream default raw=0 (not necessarily valid data).";
CM_ SG_ 1485 ProcessCounter "DATABASE_CANDIDATE: layout imported; physical meaning not independently verified. PSA-RE bits 1.3-1.0. Rolling counter incremented at each calculation cycle Upstream default raw=0 (not necessarily valid data).";
CM_ SG_ 1485 FrameChecksum "DATABASE_CANDIDATE: layout imported; physical meaning not independently verified. PSA-RE bits 1.7-1.4. Checksum of the frame";
CM_ BO_ 1486 "Observed OBD 6/14 HS1. CAN ID 0x5CE; ID_DLC_match. PSA-RE name: RITCS_DATA_2. RITCS data 3: ASR, power-steering, suspension, particulate-filter and parking-sensor telltales, travel side, crash info and number of detected lanes. Source: https://github.com/prototux/PSA-RE/blob/67f7581e7622410efdbb29c7eda3b86982b9b450/buses/AEE2010.full/HS.HS1/5CE.yml. Database sender alternatives: BSI. ECU labels are database claims; forwarding/physical transmitter not independently identified. All fitting source fields retained, including default/unavailable-only candidates. See audit/source JSON for exclusions and unresolved alternatives.";
CM_ SG_ 1486 RawBits20_23 "RAW. PSA-RE bits 3.3-3.0. Raw unmapped/padding bits; no physical interpretation.";
CM_ SG_ 1486 RoadType "DATABASE_CANDIDATE: layout imported; physical meaning not independently verified. PSA-RE bits 3.7-3.4. Type of road (motorway, multi-lane, single carriageway, roundabout...) Upstream default raw=0 (not necessarily valid data).";
CM_ SG_ 1486 RawBits15_15 "RAW. PSA-RE bits 2.0-2.0. Raw unmapped/padding bits; no physical interpretation.";
CM_ SG_ 1486 IndicatorStopPresent "DATABASE_CANDIDATE: layout imported; physical meaning not independently verified. PSA-RE bits 2.1. STOP warning indicator light fitted";
CM_ SG_ 1486 ElectricParkingBrakeFaultPresent "DATABASE_CANDIDATE: layout imported; physical meaning not independently verified. PSA-RE bits 2.2. Electronic brake force distribution (EBD) fault indicator light fitted Upstream default raw=0 (not necessarily valid data).";
CM_ SG_ 1486 StartIndicatorPresence "DATABASE_CANDIDATE: layout imported; physical meaning not independently verified. PSA-RE bits 2.3. Presence of the \"+ START\" indicator lamp Upstream default raw=0 (not necessarily valid data).";
CM_ SG_ 1486 LaneCountDrivingDirection "DATABASE_CANDIDATE: layout imported; physical meaning not independently verified. PSA-RE bits 2.6-2.4. Number of lanes in the driving direction Upstream default raw=7 (not necessarily valid data).";
CM_ SG_ 1486 IndicatorSamPresent "DATABASE_CANDIDATE: layout imported; physical meaning not independently verified. PSA-RE bits 2.7. Parking space measurement function indicator light fitted";
CM_ SG_ 1486 CrashDetectedSinceLastPowerUp "DATABASE_CANDIDATE: layout imported; physical meaning not independently verified. PSA-RE bits 1.0. Crash detected since the last power-up Upstream default raw=0 (not necessarily valid data).";
CM_ SG_ 1486 IndicatorParkingBrakePresent "DATABASE_CANDIDATE: layout imported; physical meaning not independently verified. PSA-RE bits 1.1. Parking brake indicator light fitted";
CM_ SG_ 1486 IndicatorFapPresent "DATABASE_CANDIDATE: layout imported; physical meaning not independently verified. PSA-RE bits 1.2. Particulate filter indicator light fitted Upstream default raw=0 (not necessarily valid data).";
CM_ SG_ 1486 IndicatorGasoilWaterPresent "DATABASE_CANDIDATE: layout imported; physical meaning not independently verified. PSA-RE bits 1.3. Water in diesel fuel filter indicator light fitted";
CM_ SG_ 1486 DrivingSide "DATABASE_CANDIDATE: layout imported; physical meaning not independently verified. PSA-RE bits 1.4. Driving side (left-hand or right-hand traffic) Upstream default raw=0 (not necessarily valid data).";
CM_ SG_ 1486 CaarIndicatorPresent "DATABASE_CANDIDATE: layout imported; physical meaning not independently verified. PSA-RE bits 1.5. Automatic ride-height correction fault indicator light fitted";
CM_ SG_ 1486 IndicatorDaePresent "DATABASE_CANDIDATE: layout imported; physical meaning not independently verified. PSA-RE bits 1.6. Power steering fault indicator light fitted";
CM_ SG_ 1486 IndicatorEspPresent "DATABASE_CANDIDATE: layout imported; physical meaning not independently verified. PSA-RE bits 1.7. ESP/ASR fault indicator light fitted";
CM_ BO_ 1506 "Observed OBD 6/14 HS1. CAN ID 0x5E2; ID_DLC_match. PSA-RE name: STL_VERSION. Vehicle control unit data: available driving modes (normal, sport, eco, snow...), energy modes (hybrid, zero-emission, fuel) and drive-axle modes (auto, front, rear), plus cooling wake-up requests. Source: https://github.com/prototux/PSA-RE/blob/67f7581e7622410efdbb29c7eda3b86982b9b450/buses/AEE2010.electric/HS.HS1/5E2.yml. Database sender alternatives: VCU,E_VCU. ECU labels are database claims; forwarding/physical transmitter not independently identified. All fitting source fields retained, including default/unavailable-only candidates. See audit/source JSON for exclusions and unresolved alternatives.";
CM_ SG_ 1506 Unused2 "DATABASE_CANDIDATE: layout imported; physical meaning not independently verified. PSA-RE bits 8.4-8.0. ";
CM_ SG_ 1506 AcSolenoidValve2Diagnosis "DATABASE_CANDIDATE: layout imported; physical meaning not independently verified. PSA-RE bits 8.5. Air conditioning solenoid valve 2 (chiller) diagnosis Upstream default raw=0 (not necessarily valid data).";
CM_ SG_ 1506 AcSolenoidValve1Diagnosis "DATABASE_CANDIDATE: layout imported; physical meaning not independently verified. PSA-RE bits 8.6. Air conditioning solenoid valve 1 diagnosis Upstream default raw=0 (not necessarily valid data).";
CM_ SG_ 1506 Unused1 "DATABASE_CANDIDATE: layout imported; physical meaning not independently verified. PSA-RE bits 6.0-8.7. ";
CM_ SG_ 1506 MixedModeEcoZevAvailability "DATABASE_CANDIDATE: layout imported; physical meaning not independently verified. PSA-RE bits 6.2-6.1. Combined eco/zero-emission driving mode availability Upstream default raw=0 (not necessarily valid data).";
CM_ SG_ 1506 MixedModeEcoHybridAvailability "DATABASE_CANDIDATE: layout imported; physical meaning not independently verified. PSA-RE bits 6.4-6.3. Combined eco/hybrid driving mode availability Upstream default raw=0 (not necessarily valid data).";
CM_ SG_ 1506 DriveAxleModeStatus "DATABASE_CANDIDATE: layout imported; physical meaning not independently verified. PSA-RE bits 6.7-6.5. Current drive axle mode status (front/rear/AWD) Upstream default raw=4 (not necessarily valid data).";
CM_ SG_ 1506 DriveAxleModeRequestFeedback "DATABASE_CANDIDATE: layout imported; physical meaning not independently verified. PSA-RE bits 5.0. Feedback on the requested drive axle mode (accepted/refused) Upstream default raw=1 (not necessarily valid data).";
CM_ SG_ 1506 EnergyModeRequestFeedback "DATABASE_CANDIDATE: layout imported; physical meaning not independently verified. PSA-RE bits 5.1. Feedback on the requested energy mode (accepted/refused) Upstream default raw=1 (not necessarily valid data).";
CM_ SG_ 1506 EnergyModeStatus "DATABASE_CANDIDATE: layout imported; physical meaning not independently verified. PSA-RE bits 5.4-5.2. Current energy mode status (Hybrid/Electric/Fuel) Upstream default raw=3 (not necessarily valid data).";
CM_ SG_ 1506 DynamicDriveModeStatus "DATABASE_CANDIDATE: layout imported; physical meaning not independently verified. PSA-RE bits 5.7-5.5. Current dynamic driving mode status Upstream default raw=5 (not necessarily valid data).";
CM_ SG_ 1506 DynamicDriveModeRequestFeedback "DATABASE_CANDIDATE: layout imported; physical meaning not independently verified. PSA-RE bits 4.0. Feedback on the requested dynamic driving mode (accepted/refused) Upstream default raw=1 (not necessarily valid data).";
CM_ SG_ 1506 DriveModeFeedbackToggleBit "DATABASE_CANDIDATE: layout imported; physical meaning not independently verified. PSA-RE bits 4.1. Toggle bit for the drive mode change feedback Upstream default raw=0 (not necessarily valid data).";
CM_ SG_ 1506 MixedModeNormalZevAvailability "DATABASE_CANDIDATE: layout imported; physical meaning not independently verified. PSA-RE bits 4.3-4.2. Combined normal/zero-emission driving mode availability Upstream default raw=0 (not necessarily valid data).";
CM_ SG_ 1506 AxleModeAwdAvailability "DATABASE_CANDIDATE: layout imported; physical meaning not independently verified. PSA-RE bits 4.5-4.4. All-wheel-drive mode availability Upstream default raw=0 (not necessarily valid data).";
CM_ SG_ 1506 AxleModeRearAvailability "DATABASE_CANDIDATE: layout imported; physical meaning not independently verified. PSA-RE bits 4.7-4.6. Rear-wheel-drive mode availability Upstream default raw=0 (not necessarily valid data).";
CM_ SG_ 1506 AxleModeFrontAvailability "DATABASE_CANDIDATE: layout imported; physical meaning not independently verified. PSA-RE bits 3.1-3.0. Front-wheel-drive mode availability Upstream default raw=0 (not necessarily valid data).";
CM_ SG_ 1506 AxleModeAutoAvailability "DATABASE_CANDIDATE: layout imported; physical meaning not independently verified. PSA-RE bits 3.3-3.2. Automatic axle-drive mode availability Upstream default raw=0 (not necessarily valid data).";
CM_ SG_ 1506 EnergyModeFuelAvailability "DATABASE_CANDIDATE: layout imported; physical meaning not independently verified. PSA-RE bits 3.5-3.4. Fuel (combustion) energy mode availability Upstream default raw=0 (not necessarily valid data).";
CM_ SG_ 1506 EnergyModeZevAvailability "DATABASE_CANDIDATE: layout imported; physical meaning not independently verified. PSA-RE bits 3.7-3.6. Zero-emission (ZEV) energy mode availability Upstream default raw=0 (not necessarily valid data).";
CM_ SG_ 1506 EnergyModeHybridAvailability "DATABASE_CANDIDATE: layout imported; physical meaning not independently verified. PSA-RE bits 2.1-2.0. Hybrid energy mode availability Upstream default raw=0 (not necessarily valid data).";
CM_ SG_ 1506 DynamicModeSpare2Availability "DATABASE_CANDIDATE: layout imported; physical meaning not independently verified. PSA-RE bits 2.3-2.2. Reserved driving mode 2 availability";
CM_ SG_ 1506 DynamicModeSpare1Availability "DATABASE_CANDIDATE: layout imported; physical meaning not independently verified. PSA-RE bits 2.5-2.4. Reserved driving mode 1 availability";
CM_ SG_ 1506 DynamicModeEcoPlusAvailability "DATABASE_CANDIDATE: layout imported; physical meaning not independently verified. PSA-RE bits 2.7-2.6. Eco+ driving mode availability Upstream default raw=0 (not necessarily valid data).";
CM_ SG_ 1506 DynamicModeSnowAvailability "DATABASE_CANDIDATE: layout imported; physical meaning not independently verified. PSA-RE bits 1.1-1.0. Snow driving mode availability Upstream default raw=0 (not necessarily valid data).";
CM_ SG_ 1506 DynamicModeEcoAvailability "DATABASE_CANDIDATE: layout imported; physical meaning not independently verified. PSA-RE bits 1.3-1.2. Eco driving mode availability Upstream default raw=0 (not necessarily valid data).";
CM_ SG_ 1506 DynamicModeSportAvailability "DATABASE_CANDIDATE: layout imported; physical meaning not independently verified. PSA-RE bits 1.5-1.4. Sport driving mode availability Upstream default raw=0 (not necessarily valid data).";
CM_ SG_ 1506 DynamicModeNormalAvailability "DATABASE_CANDIDATE: layout imported; physical meaning not independently verified. PSA-RE bits 1.7-1.6. Normal driving mode availability Upstream default raw=0 (not necessarily valid data).";
CM_ BO_ 1515 "Observed OBD 6/14 HS1. CAN ID 0x5EB; ID_DLC_match. PSA-RE name: ESM_SUPERVISION. Network supervision: transmission quality counters and fault presence of the sending ECU Source: https://github.com/prototux/PSA-RE/blob/67f7581e7622410efdbb29c7eda3b86982b9b450/buses/AEE2010.full/HS.HS1/5EB.yml. Database sender alternatives: ESM. ECU labels are database claims; forwarding/physical transmitter not independently identified. All fitting source fields retained, including default/unavailable-only candidates. See audit/source JSON for exclusions and unresolved alternatives.";
CM_ SG_ 1515 Unused1 "DATABASE_CANDIDATE: layout imported; physical meaning not independently verified. PSA-RE bits 8.3-8.0. ";
CM_ SG_ 1515 PartialWakeupStatusFlagsP_c242fd "DATABASE_CANDIDATE: layout imported; physical meaning not independently verified. PSA-RE bits 6.3-8.4. Per-ECU flags indicating which partial wake-up(s) are active, for both master and slave partial-wake-up ECUs. Upstream default raw=0 (not necessarily valid data).";
CM_ SG_ 1515 EcuOperatingPhase "DATABASE_CANDIDATE: layout imported; physical meaning not independently verified. PSA-RE bits 6.7-6.4. ECU (RCD) operating phase.";
CM_ SG_ 1515 EcuConfirmedAbsentStatus "DATABASE_CANDIDATE: layout imported; physical meaning not independently verified. PSA-RE bits 2.7-5.0. \"Confirmed absent\" status flags of the supervised ECUs: 0 if present, 1 if confirmed absent (0 by default for unsupervised ECUs). Upstream default raw=0 (not necessarily valid data).";
CM_ SG_ 1515 DiagnosticMemoryState "DATABASE_CANDIDATE: layout imported; physical meaning not independently verified. PSA-RE bits 1.7-1.0. State of the system's diagnostic memory. Upstream default raw=0 (not necessarily valid data).";
CM_ BO_ 1522 "Observed OBD 6/14 HS1. CAN ID 0x5F2; ID_DLC_match. PSA-RE name: FRONT_CAMERA_INFO. Front camera module data: lighting function faults, distance travelled, headlight commutation and degraded mode requests, wiping state. Source: https://github.com/prototux/PSA-RE/blob/67f7581e7622410efdbb29c7eda3b86982b9b450/buses/AEE2010.full/HS.HS1/5F2.yml. Database sender alternatives: CVM. ECU labels are database claims; forwarding/physical transmitter not independently identified. All fitting source fields retained, including default/unavailable-only candidates. See audit/source JSON for exclusions and unresolved alternatives.";
CM_ SG_ 1522 DistanceSinceLastSpeedSign "DATABASE_CANDIDATE: layout imported; physical meaning not independently verified. PSA-RE bits 5.7-5.0. Distance travelled since the last speed limit sign read Raw invalid=255; numeric DBC decoders may still scale it: check raw before use. Upstream default raw=254 (not necessarily valid data).";
CM_ SG_ 1522 Unused2 "DATABASE_CANDIDATE: layout imported; physical meaning not independently verified. PSA-RE bits 4.4-4.0. ";
CM_ SG_ 1522 SpeedInfoRobustnessFlag "DATABASE_CANDIDATE: layout imported; physical meaning not independently verified. PSA-RE bits 4.5. Robustness flag of the vehicle speed information Upstream default raw=0 (not necessarily valid data).";
CM_ SG_ 1522 SpeedSignType "DATABASE_CANDIDATE: layout imported; physical meaning not independently verified. PSA-RE bits 4.7-4.6. Type of speed sign read (speed limit start or end of limited area)";
CM_ SG_ 1522 CameraReadSpeed "DATABASE_CANDIDATE: layout imported; physical meaning not independently verified. PSA-RE bits 3.7-3.0. Vehicle speed read by the front camera module (CVM) Raw invalid=255; numeric DBC decoders may still scale it: check raw before use. Upstream default raw=254 (not necessarily valid data).";
CM_ SG_ 1522 Unused1 "DATABASE_CANDIDATE: layout imported; physical meaning not independently verified. PSA-RE bits 2.0. ";
CM_ SG_ 1522 CdpStatus "DATABASE_CANDIDATE: layout imported; physical meaning not independently verified. PSA-RE bits 2.1. CDP module status (normal or faulty) Upstream default raw=0 (not necessarily valid data).";
CM_ SG_ 1522 RainSensorWiperState "DATABASE_CANDIDATE: layout imported; physical meaning not independently verified. PSA-RE bits 2.3-2.2. Wiper state controlled by the rain sensor Upstream default raw=0 (not necessarily valid data).";
CM_ SG_ 1522 WiperSweepSpeed "DATABASE_CANDIDATE: layout imported; physical meaning not independently verified. PSA-RE bits 2.7-2.4. Wiper sweep speed Upstream default raw=0 (not necessarily valid data).";
CM_ SG_ 1522 CdlStatus "DATABASE_CANDIDATE: layout imported; physical meaning not independently verified. PSA-RE bits 1.0. CDL module status (normal or faulty) Upstream default raw=0 (not necessarily valid data).";
CM_ SG_ 1522 AafRequest "DATABASE_CANDIDATE: layout imported; physical meaning not independently verified. PSA-RE bits 1.1. AAF request Upstream default raw=0 (not necessarily valid data).";
CM_ SG_ 1522 CafrBrightnessStatus "DATABASE_CANDIDATE: layout imported; physical meaning not independently verified. PSA-RE bits 1.2. CAFR brightness validity status Upstream default raw=0 (not necessarily valid data).";
CM_ SG_ 1522 CafrFunctionFault "DATABASE_CANDIDATE: layout imported; physical meaning not independently verified. PSA-RE bits 1.3. CAFR function status (normal or faulty) Upstream default raw=0 (not necessarily valid data).";
CM_ SG_ 1522 LowHighBeamSwitchingRequest "DATABASE_CANDIDATE: layout imported; physical meaning not independently verified. PSA-RE bits 1.4. Low/high beam switching request Upstream default raw=0 (not necessarily valid data).";
CM_ SG_ 1522 AbnormalLaneDepartureRight "DATABASE_CANDIDATE: layout imported; physical meaning not independently verified. PSA-RE bits 1.5. Abnormal right lane departure detected. Upstream default raw=0 (not necessarily valid data).";
CM_ SG_ 1522 AbnormalLaneDepartureLeft "DATABASE_CANDIDATE: layout imported; physical meaning not independently verified. PSA-RE bits 1.6. Abnormal left lane departure detected. Upstream default raw=0 (not necessarily valid data).";
CM_ SG_ 1522 StlFaultPresent "DATABASE_CANDIDATE: layout imported; physical meaning not independently verified. PSA-RE bits 1.7. Fault present in the lane departure warning system (STL). Upstream default raw=0 (not necessarily valid data).";
CM_ BO_ 1554 "Observed OBD 6/14 HS1. CAN ID 0x612; ID_DLC_match. PSA-RE name: BSI_DATA_3. Body controller data 7: left/right indicator requests, low/high-beam state, fuel level info, and daytime-running/motorway/town/dynamic-bend lighting inhibitions. Source: https://github.com/prototux/PSA-RE/blob/67f7581e7622410efdbb29c7eda3b86982b9b450/buses/AEE2010.full/HS.HS1/612.yml. Database sender alternatives: BSI. ECU labels are database claims; forwarding/physical transmitter not independently identified. All fitting source fields retained, including default/unavailable-only candidates. See audit/source JSON for exclusions and unresolved alternatives.";
CM_ SG_ 1554 RawBits62_63 "RAW. PSA-RE bits 8.1-8.0. Raw unmapped/padding bits; no physical interpretation.";
CM_ SG_ 1554 VehicleConfigurationState "DATABASE_CANDIDATE: layout imported; physical meaning not independently verified. PSA-RE bits 8.4-8.2. Vehicle configuration state (assembly, factory, inspection, storage/transport, customer) Upstream default raw=4 (not necessarily valid data).";
CM_ SG_ 1554 RelayR3LineDiagnostic "DATABASE_CANDIDATE: layout imported; physical meaning not independently verified. PSA-RE bits 8.7-8.5. Diagnostic status of the relay R3 control line Upstream default raw=0 (not necessarily valid data).";
CM_ SG_ 1554 RawBits55_55 "RAW. PSA-RE bits 7.0-7.0. Raw unmapped/padding bits; no physical interpretation.";
CM_ SG_ 1554 RelayLineDiagnosticUpdateBit "DATABASE_CANDIDATE: layout imported; physical meaning not independently verified. PSA-RE bits 7.1. Update bit for the relay line diagnostic signals (D_LIGNE_REL_Rx) Upstream default raw=0 (not necessarily valid data).";
CM_ SG_ 1554 RelayR2LineDiagnostic "DATABASE_CANDIDATE: layout imported; physical meaning not independently verified. PSA-RE bits 7.4-7.2. Diagnostic status of the relay R2 control line Upstream default raw=0 (not necessarily valid data).";
CM_ SG_ 1554 RelayR1LineDiagnostic "DATABASE_CANDIDATE: layout imported; physical meaning not independently verified. PSA-RE bits 7.7-7.5. Diagnostic status of the relay R1 control line Upstream default raw=0 (not necessarily valid data).";
CM_ SG_ 1554 StartingPredictedVoltage "DATABASE_CANDIDATE: layout imported; physical meaning not independently verified. PSA-RE bits 5.2-6.0. Predicted battery voltage at engine start Raw invalid=2047; numeric DBC decoders may still scale it: check raw before use. Upstream default raw=2046 (not necessarily valid data).";
CM_ SG_ 1554 RawBits36_36 "RAW. PSA-RE bits 5.3-5.3. Raw unmapped/padding bits; no physical interpretation.";
CM_ SG_ 1554 MobileDeflectorPosition "DATABASE_CANDIDATE: layout imported; physical meaning not independently verified. PSA-RE bits 5.6-5.4. Mobile air deflector position Upstream default raw=0 (not necessarily valid data).";
CM_ SG_ 1554 OlviRearHmiActivationRequest "DATABASE_CANDIDATE: layout imported; physical meaning not independently verified. PSA-RE bits 5.7. Activation request for the OLVI rear HMI Upstream default raw=0 (not necessarily valid data).";
CM_ SG_ 1554 FuelLevel "DATABASE_CANDIDATE: layout imported; physical meaning not independently verified. PSA-RE bits 4.7-4.0. Fuel level Raw invalid=255; numeric DBC decoders may still scale it: check raw before use.";
CM_ SG_ 1554 EcoMode "DATABASE_CANDIDATE: layout imported; physical meaning not independently verified. PSA-RE bits 3.1-3.0. Eco driving mode status Upstream default raw=0 (not necessarily valid data).";
CM_ SG_ 1554 AsrPlusModeSelected "DATABASE_CANDIDATE: layout imported; physical meaning not independently verified. PSA-RE bits 3.3-3.2. ASR+ traction control mode selected by the driver Upstream default raw=0 (not necessarily valid data).";
CM_ SG_ 1554 HighBeamLeftFault "DATABASE_CANDIDATE: layout imported; physical meaning not independently verified. PSA-RE bits 3.4. Left high beam fault Upstream default raw=0 (not necessarily valid data).";
CM_ SG_ 1554 HighBeamRightFault "DATABASE_CANDIDATE: layout imported; physical meaning not independently verified. PSA-RE bits 3.5. Right high beam fault Upstream default raw=0 (not necessarily valid data).";
CM_ SG_ 1554 LowBeamLeftFault "DATABASE_CANDIDATE: layout imported; physical meaning not independently verified. PSA-RE bits 3.6. Left low beam fault Upstream default raw=0 (not necessarily valid data).";
CM_ SG_ 1554 LowBeamRightFault "DATABASE_CANDIDATE: layout imported; physical meaning not independently verified. PSA-RE bits 3.7. Right low beam fault Upstream default raw=0 (not necessarily valid data).";
CM_ SG_ 1554 RawBits15_15 "RAW. PSA-RE bits 2.0-2.0. Raw unmapped/padding bits; no physical interpretation.";
CM_ SG_ 1554 LowBeamState "DATABASE_CANDIDATE: layout imported; physical meaning not independently verified. PSA-RE bits 2.1. Low beam headlights state Upstream default raw=0 (not necessarily valid data).";
CM_ SG_ 1554 HighBeamState "DATABASE_CANDIDATE: layout imported; physical meaning not independently verified. PSA-RE bits 2.2. High beam headlights state Upstream default raw=0 (not necessarily valid data).";
CM_ SG_ 1554 RawBits12_12 "RAW. PSA-RE bits 2.3-2.3. Raw unmapped/padding bits; no physical interpretation.";
CM_ SG_ 1554 VehicleConfigurationMode "DATABASE_CANDIDATE: layout imported; physical meaning not independently verified. PSA-RE bits 2.5-2.4. Vehicle configuration mode (factory, showroom, customer) Upstream default raw=2 (not necessarily valid data).";
CM_ SG_ 1554 TurnIndicatorSwitchRequest "DATABASE_CANDIDATE: layout imported; physical meaning not independently verified. PSA-RE bits 2.7-2.6. Turn signal lamp control request";
CM_ SG_ 1554 Unused3 "DATABASE_CANDIDATE: layout imported; physical meaning not independently verified. PSA-RE bits 1.0. ";
CM_ SG_ 1554 Unused2 "DATABASE_CANDIDATE: layout imported; physical meaning not independently verified. PSA-RE bits 1.1. ";
CM_ SG_ 1554 RawBits4_5 "RAW. PSA-RE bits 1.3-1.2. Raw unmapped/padding bits; no physical interpretation.";
CM_ SG_ 1554 Unused1 "DATABASE_CANDIDATE: layout imported; physical meaning not independently verified. PSA-RE bits 1.4. ";
CM_ SG_ 1554 DynamicCurveLightingInhibit "DATABASE_CANDIDATE: layout imported; physical meaning not independently verified. PSA-RE bits 1.5. Dynamic curve lighting inhibition Upstream default raw=0 (not necessarily valid data).";
CM_ SG_ 1554 MotorwayLightingInhibit "DATABASE_CANDIDATE: layout imported; physical meaning not independently verified. PSA-RE bits 1.6. Motorway lighting inhibition Upstream default raw=0 (not necessarily valid data).";
CM_ SG_ 1554 DynamicLightingDaytimeInhibit "DATABASE_CANDIDATE: layout imported; physical meaning not independently verified. PSA-RE bits 1.7. Daytime inhibition of dynamic lighting Upstream default raw=0 (not necessarily valid data).";
CM_ BO_ 1922 "Observed OBD 6/14 HS1. CAN ID 0x782; ID_DLC_match. PSA-RE name: SCDT_SUPERVISION. Extended network supervision (v2): electrical state, wake-up state and fault presence of the sending ECU Source: https://github.com/prototux/PSA-RE/blob/67f7581e7622410efdbb29c7eda3b86982b9b450/buses/AEE2010.electric/HS.HS1/782.yml. Database sender alternatives: VCU. ECU labels are database claims; forwarding/physical transmitter not independently identified. All fitting source fields retained, including default/unavailable-only candidates. See audit/source JSON for exclusions and unresolved alternatives.";
CM_ SG_ 1922 PrecondThermWupState "DATABASE_CANDIDATE: layout imported; physical meaning not independently verified. PSA-RE bits 8.0. Partial wake-up status for thermal preconditioning. Upstream default raw=0 (not necessarily valid data).";
CM_ SG_ 1922 PrecondElecWupState "DATABASE_CANDIDATE: layout imported; physical meaning not independently verified. PSA-RE bits 8.1. Partial wake-up status for electric preconditioning. Upstream default raw=0 (not necessarily valid data).";
CM_ SG_ 1922 HoldDiscontactorWupState "DATABASE_CANDIDATE: layout imported; physical meaning not independently verified. PSA-RE bits 8.2. Partial wake-up status for holding the high-voltage disconnect contactor. Upstream default raw=0 (not necessarily valid data).";
CM_ SG_ 1922 PostDriveWupState "DATABASE_CANDIDATE: layout imported; physical meaning not independently verified. PSA-RE bits 8.3. Partial wake-up status for keeping the OBC and TBMU awake for 2 minutes after driving. Upstream default raw=0 (not necessarily valid data).";
CM_ SG_ 1922 PreDriveWupState "DATABASE_CANDIDATE: layout imported; physical meaning not independently verified. PSA-RE bits 8.4. Partial wake-up status for CMM, VCU, TCU, MCU and TBMU wake-up ahead of driving. Upstream default raw=0 (not necessarily valid data).";
CM_ SG_ 1922 CceCoolingWupState "DATABASE_CANDIDATE: layout imported; physical meaning not independently verified. PSA-RE bits 8.5. Partial wake-up status for cooling needs via the CCE. Upstream default raw=0 (not necessarily valid data).";
CM_ SG_ 1922 MeapCoolingWupState "DATABASE_CANDIDATE: layout imported; physical meaning not independently verified. PSA-RE bits 8.6. Partial wake-up status for cooling needs via the MEAP. Upstream default raw=0 (not necessarily valid data).";
CM_ SG_ 1922 GmvCoolingWupState "DATABASE_CANDIDATE: layout imported; physical meaning not independently verified. PSA-RE bits 8.7. Partial wake-up status for cooling needs via the cooling fan (GMV). Upstream default raw=0 (not necessarily valid data).";
CM_ SG_ 1922 PiStateInfoWupState "DATABASE_CANDIDATE: layout imported; physical meaning not independently verified. PSA-RE bits 7.0. Partial wake-up status for reporting information to the master BSI (OBC). Upstream default raw=0 (not necessarily valid data).";
CM_ SG_ 1922 StopDelayedHmiWupState "DATABASE_CANDIDATE: layout imported; physical meaning not independently verified. PSA-RE bits 7.1. Partial wake-up status for waking the BSI to start delayed charging. Upstream default raw=0 (not necessarily valid data).";
CM_ SG_ 1922 HvBattChargeWupState "DATABASE_CANDIDATE: layout imported; physical meaning not independently verified. PSA-RE bits 7.2. Partial wake-up status for high-voltage battery charging. Upstream default raw=0 (not necessarily valid data).";
CM_ SG_ 1922 Unused2 "DATABASE_CANDIDATE: layout imported; physical meaning not independently verified. PSA-RE bits 2.7-7.3. ";
CM_ SG_ 1922 Unused1 "DATABASE_CANDIDATE: layout imported; physical meaning not independently verified. PSA-RE bits 1.2-1.0. ";
CM_ SG_ 1922 RcdLineStatus2 "DATABASE_CANDIDATE: layout imported; physical meaning not independently verified. PSA-RE bits 1.3. RCD wake-up line status. Upstream default raw=1 (not necessarily valid data).";
CM_ SG_ 1922 EcuElectricalStateRcd "DATABASE_CANDIDATE: layout imported; physical meaning not independently verified. PSA-RE bits 1.6-1.4. ECU electrical state for an RCD-type wake-up. Upstream default raw=2 (not necessarily valid data).";
CM_ SG_ 1922 DiagnosticMemoryState2 "DATABASE_CANDIDATE: layout imported; physical meaning not independently verified. PSA-RE bits 1.7. State of the system's diagnostic memory (fault code(s) present or not). Upstream default raw=0 (not necessarily valid data).";
CM_ BO_ 1933 "Observed OBD 6/14 HS1. CAN ID 0x78D; ID_DLC_match. PSA-RE name: BRAKES_SUPERVISION_HS. Network supervision: transmission quality counters and fault presence of the sending ECU Source: https://github.com/prototux/PSA-RE/blob/67f7581e7622410efdbb29c7eda3b86982b9b450/buses/AEE2010.full/HS.HS1/78D.yml. Database sender alternatives: ABS. ECU labels are database claims; forwarding/physical transmitter not independently identified. All fitting source fields retained, including default/unavailable-only candidates. See audit/source JSON for exclusions and unresolved alternatives.";
CM_ SG_ 1933 RcdLineStatus "DATABASE_CANDIDATE: layout imported; physical meaning not independently verified. PSA-RE bits 8.0. RCD wake-up line status. Upstream default raw=1 (not necessarily valid data).";
CM_ SG_ 1933 ApcLineStatus "DATABASE_CANDIDATE: layout imported; physical meaning not independently verified. PSA-RE bits 8.1. +APC ignition wake-up line status. Upstream default raw=0 (not necessarily valid data).";
CM_ SG_ 1933 RawBits60_61 "RAW. PSA-RE bits 8.3-8.2. Raw unmapped/padding bits; no physical interpretation.";
CM_ SG_ 1933 PartialWakeupStatusFlagsLas "DATABASE_CANDIDATE: layout imported; physical meaning not independently verified. PSA-RE bits 6.3-8.4. Partial wake-up status flags. Upstream default raw=0 (not necessarily valid data).";
CM_ SG_ 1933 EcuOperatingPhase "DATABASE_CANDIDATE: layout imported; physical meaning not independently verified. PSA-RE bits 6.7-6.4. ECU (RCD) operating phase.";
CM_ SG_ 1933 EcuConfirmedAbsentStatus "DATABASE_CANDIDATE: layout imported; physical meaning not independently verified. PSA-RE bits 2.7-5.0. \"Confirmed absent\" status flags of the supervised ECUs: 0 if present, 1 if confirmed absent (0 by default for unsupervised ECUs). Upstream default raw=0 (not necessarily valid data).";
CM_ SG_ 1933 DiagnosticMemoryState "DATABASE_CANDIDATE: layout imported; physical meaning not independently verified. PSA-RE bits 1.7-1.0. State of the system's diagnostic memory. Upstream default raw=0 (not necessarily valid data).";
CM_ BO_ 1938 "Observed OBD 6/14 HS1. CAN ID 0x792; ID_DLC_match. PSA-RE name: BSI_SUPERVISION_HS. Network supervision: transmission quality counters and fault presence of the sending ECU Source: https://github.com/prototux/PSA-RE/blob/67f7581e7622410efdbb29c7eda3b86982b9b450/buses/AEE2010.full/HS.HS1/792.yml. Database sender alternatives: BSI. ECU labels are database claims; forwarding/physical transmitter not independently identified. All fitting source fields retained, including default/unavailable-only candidates. See audit/source JSON for exclusions and unresolved alternatives.";
CM_ SG_ 1938 RcdLineStatus "DATABASE_CANDIDATE: layout imported; physical meaning not independently verified. PSA-RE bits 8.0. RCD wake-up line status. Upstream default raw=1 (not necessarily valid data).";
CM_ SG_ 1938 Unused1 "DATABASE_CANDIDATE: layout imported; physical meaning not independently verified. PSA-RE bits 8.3-8.1. ";
CM_ SG_ 1938 PartialWakeupStatusFlags "DATABASE_CANDIDATE: layout imported; physical meaning not independently verified. PSA-RE bits 6.3-8.4. Per-ECU flags indicating which partial wake-up(s) are active, for both master and slave partial-wake-up ECUs. Upstream default raw=0 (not necessarily valid data).";
CM_ SG_ 1938 EcuOperatingPhase "DATABASE_CANDIDATE: layout imported; physical meaning not independently verified. PSA-RE bits 6.7-6.4. ECU (RCD) operating phase.";
CM_ SG_ 1938 EcuConfirmedAbsentStatus "DATABASE_CANDIDATE: layout imported; physical meaning not independently verified. PSA-RE bits 2.7-5.0. \"Confirmed absent\" status flags of the supervised ECUs: 0 if present, 1 if confirmed absent (0 by default for unsupervised ECUs). Upstream default raw=0 (not necessarily valid data).";
CM_ SG_ 1938 DiagnosticMemoryState "DATABASE_CANDIDATE: layout imported; physical meaning not independently verified. PSA-RE bits 1.7-1.0. State of the system's diagnostic memory. Upstream default raw=0 (not necessarily valid data).";
CM_ BO_ 1941 "Observed OBD 6/14 HS1. CAN ID 0x795; ID_DLC_match. PSA-RE name: DIRA_SUPERVISION. Network supervision: transmission quality counters and fault presence of the sending ECU Source: https://github.com/prototux/PSA-RE/blob/67f7581e7622410efdbb29c7eda3b86982b9b450/buses/AEE2010.full/HS.HS1/795.yml. Database sender alternatives: DAE. ECU labels are database claims; forwarding/physical transmitter not independently identified. All fitting source fields retained, including default/unavailable-only candidates. See audit/source JSON for exclusions and unresolved alternatives.";
CM_ SG_ 1941 Unused1 "DATABASE_CANDIDATE: layout imported; physical meaning not independently verified. PSA-RE bits 6.3-6.0. ";
CM_ SG_ 1941 PowerSteeringAssistStatus "DATABASE_CANDIDATE: layout imported; physical meaning not independently verified. PSA-RE bits 6.6-6.4. Power steering assistance status.";
CM_ SG_ 1941 ApcLineStatus "DATABASE_CANDIDATE: layout imported; physical meaning not independently verified. PSA-RE bits 6.7. +APC ignition wake-up line status. Upstream default raw=0 (not necessarily valid data).";
CM_ SG_ 1941 EcuConfirmedAbsentStatus "DATABASE_CANDIDATE: layout imported; physical meaning not independently verified. PSA-RE bits 2.7-5.0. \"Confirmed absent\" status flags of the supervised ECUs: 0 if present, 1 if confirmed absent (0 by default for unsupervised ECUs). Upstream default raw=0 (not necessarily valid data).";
CM_ SG_ 1941 DiagnosticMemoryState "DATABASE_CANDIDATE: layout imported; physical meaning not independently verified. PSA-RE bits 1.7-1.0. State of the system's diagnostic memory. Upstream default raw=0 (not necessarily valid data).";
CM_ BO_ 1946 "Observed OBD 6/14 HS1. CAN ID 0x79A; ID_DLC_match. PSA-RE name: LVNSD_SUPERVISION. Network supervision: transmission quality counters and fault presence of the sending ECU Source: https://github.com/prototux/PSA-RE/blob/67f7581e7622410efdbb29c7eda3b86982b9b450/buses/AEE2010.full/HS.HS1/79A.yml. Database sender alternatives: LVNSD. ECU labels are database claims; forwarding/physical transmitter not independently identified. All fitting source fields retained, including default/unavailable-only candidates. See audit/source JSON for exclusions and unresolved alternatives.";
CM_ SG_ 1946 Unused2 "DATABASE_CANDIDATE: layout imported; physical meaning not independently verified. PSA-RE bits 8.3-8.0. ";
CM_ SG_ 1946 PartialWakeupStatusFlagsP_c242fd "DATABASE_CANDIDATE: layout imported; physical meaning not independently verified. PSA-RE bits 6.3-8.4. Per-ECU flags indicating which partial wake-up(s) are active, for both master and slave partial-wake-up ECUs. Upstream default raw=0 (not necessarily valid data).";
CM_ SG_ 1946 Unused1 "DATABASE_CANDIDATE: layout imported; physical meaning not independently verified. PSA-RE bits 6.4. ";
CM_ SG_ 1946 EcuElectricalStateApc "DATABASE_CANDIDATE: layout imported; physical meaning not independently verified. PSA-RE bits 6.7-6.5. ECU electrical state for an APC-type wake-up. Upstream default raw=3 (not necessarily valid data).";
CM_ SG_ 1946 EcuConfirmedAbsentStatus "DATABASE_CANDIDATE: layout imported; physical meaning not independently verified. PSA-RE bits 2.7-5.0. \"Confirmed absent\" status flags of the supervised ECUs: 0 if present, 1 if confirmed absent (0 by default for unsupervised ECUs). Upstream default raw=0 (not necessarily valid data).";
CM_ SG_ 1946 DiagnosticMemoryState "DATABASE_CANDIDATE: layout imported; physical meaning not independently verified. PSA-RE bits 1.7-1.0. State of the system's diagnostic memory. Upstream default raw=0 (not necessarily valid data).";
VAL_ 1293 EspDisconnectRequest 0 "Connected by diagnostic tool" 1 "Disconnected by diagnostic tool" ;
VAL_ 1293 BrakeAssistFaultLampRequest 0 "No ignition request" 1 "Fault lamp lighting request" ;
VAL_ 1293 StaticSlopeState 0 "Low slope" 1 "Steep uphill slope" 2 "high downhill slope" 3 "Slope undefined" ;
VAL_ 1293 BrakeFunctionNeedForStartStop 0 "No need, per brake function" 1 "Stop transition inhibition" 2 "Restart needed" 3 "Stop transition and restart inhibited" ;
VAL_ 1293 BrakeEcuPowerManagementFault 0 "No fault" 1 "Fault" ;
VAL_ 1293 EmergencyBrakingSignaliza_517ee3 0 "SFU function absent from the brake ECU" 1 "EBS function present in the brake ECU" ;
VAL_ 1293 BrakeEcuSupplyVoltage 255 "Not_available" ;
VAL_ 1293 RearRightWheelSpeedSensorFault 0 "No fault" 1 "Rear-right pulse counter fault" ;
VAL_ 1293 RearLeftWheelSpeedSensorFault 0 "No fault on the RRL pulse counter" 1 "Fault on the rear left pulse counter" ;
VAL_ 1293 AbsFaultLampRequest 0 "No request" 1 "Switch-on request" ;
VAL_ 1293 BrakeFluidLevelAlert 0 "No alert" 1 "Alert" ;
VAL_ 1293 WornBrakePadsIndicator 0 "Brake pads OK" 1 "Brake pads worn" ;
VAL_ 1293 RefInProgress 0 "Not in regulation" 1 "Regulation active" ;
VAL_ 1293 AutomaticHazardLightsByUcBrake 0 "AAFD function not present in the brake ECU" 1 "AAFD function present in the brake ECU" ;
VAL_ 1293 AbsInProgress 0 "Not in regulation" 1 "Regulation active" ;
VAL_ 1293 RefFaultLamp 0 "No request" 1 "Switch-on request" ;
VAL_ 1298 CabinPreconditioningTypeRequest 0 "Balance" 1 "discharge" ;
VAL_ 1298 VehicleLockedFromOutside 0 "Unlocked" 1 "Locked" 2 "Super-locked" ;
VAL_ 1298 VehicleLockedFromInside 0 "Unlocked" 1 "Locked" 2 "Super-locked" ;
VAL_ 1298 DriveAxleModeRequest 0 "Automatic axle" 1 "Front" 2 "Rear" 3 "AWD" 4 "Initialization" ;
VAL_ 1298 CabinThermalPreconditioni_484d54 0 "Requested" 1 "No request" ;
VAL_ 1298 DriveModeRequestToggleBit 0 "Request 0" 1 "Request 1" ;
VAL_ 1298 EnergyModeRequest 0 "Hybrid" 1 "ZEV" 2 "Fuel" 3 "Initialization" ;
VAL_ 1298 DynamicDriveModeRequest 0 "Normal" 1 "Sport" 2 "Eco" 3 "SNOW" 4 "ECOP" 5 "Initialization" ;
VAL_ 1304 PowertrainRollerBenchMode 0 "Unavailable" 1 "Motorway mode" 2 "Single-axis rolling road (dyno) mode" 3 "Two-axis chassis dynamometer mode" ;
VAL_ 1304 PowertrainCombinedPower 1023 "Not_available" ;
VAL_ 1314 ChargeRemainingTimeDisplay 4095 "Not_available" ;
VAL_ 1314 HvBatteryAverageTemperature 255 "Not_available" ;
VAL_ 1314 InverterWorkingState 0 "Power off / wake-up" 2 "Ready" 3 "Functional" 4 "Cooling down after use" 5 "Deactivated" 6 "Safety mode" 7 "Invalid value" ;
VAL_ 1314 DcdcConverterTemperature 255 "Not_available" ;
VAL_ 1326 CruiseControlSpeed 65535 "Not_available" ;
VAL_ 1326 Distance 65535 "Not_available" ;
VAL_ 1326 Autonomy 65535 "Not_available" ;
VAL_ 1338 LvBatteryThermalDeratingState 0 "No derating" 1 "Level-1 derating request" 2 "Derating level 2 request" 3 "Unused value (11)" ;
VAL_ 1338 LvBatterySwitchingVoltage 127 "Not_available" ;
VAL_ 1338 LvBatterySupplyNetworkVoltage 127 "Not_available" ;
VAL_ 1347 BmsTotalBatteryEnergy 2047 "Not_available" ;
VAL_ 1347 BatteryEnergyExtendedFlag 0 "Battery energy not extended" 1 "Extended battery energy" ;
VAL_ 1347 BmsRemainingBatteryEnergy 2047 "Not_available" ;
VAL_ 1358 EcoTime 127 "Not_available" ;
VAL_ 1358 FilteredFuelLevel 255 "Not_available" ;
VAL_ 1358 TotalMileage 16777215 "Not_available" ;
VAL_ 1358 OdometerPartial 16777215 "Not_available" ;
VAL_ 1362 TimeCounterResetCounter 255 "Not_available" ;
VAL_ 1362 Odometer 16777215 "Not_available" ;
VAL_ 1362 VehicleTimeCounter 4294967295 "Not_available" ;
VAL_ 1370 BatteryResistanceSeq3 511 "Not_available" ;
VAL_ 1370 BatteryVoltageSeq3 127 "Not_available" ;
VAL_ 1370 BatteryResistanceSeq2 511 "Not_available" ;
VAL_ 1370 BatteryVoltageSeq2 127 "Not_available" ;
VAL_ 1370 BatteryResistanceSeq4 511 "Not_available" ;
VAL_ 1370 BatteryResistanceSeq1 511 "Not_available" ;
VAL_ 1370 BatteryVoltageSeq4 127 "Not_available" ;
VAL_ 1370 BatteryVoltageSeq1 127 "Not_available" ;
VAL_ 1370 LvBatterySequenceId 0 "Emission of BATTERY_VOLTAGE_SEQ1, BATTERY_RESISTANCE_SEQ1," 1 "Transmission of BATTERY_VOLTAGE_SEQ4, BATTERY_RESISTANCE_SEQ4" ;
VAL_ 1379 BmsRemainingBatteryCapacity 1048575 "Not_available" ;
VAL_ 1379 EbbAssistFaultLampRequest 0 "No fault" 1 "Brake fault" ;
VAL_ 1379 PemOvertemperatureFault 0 "Nominal" 1 "Temperature warning" ;
VAL_ 1379 RemInverterTemperatureAlert 0 "Nominal" 1 "Temperature warning" ;
VAL_ 1379 PemInverterTemperatureAlert 0 "Nominal" 1 "Temperature warning" ;
VAL_ 1379 PowertrainValidatedLeverPosition 0 "Park" 1 "Reverse gear" 2 "Centre (neutral)" 3 "Automatic" 4 "Manual" ;
VAL_ 1387 UnitLanguageDataValidity 0 "Unavailable" 1 "Available" ;
VAL_ 1387 DistanceUnit 0 "km" 1 "miles" ;
VAL_ 1387 IlvAdvisedSpeed 255 "Not_available" ;
VAL_ 1387 HeadlampBeamSelectControl 0 "Passing beam (low beam) position" 1 "Main beam position" ;
VAL_ 1387 FrontFogLightControl 0 "Lamps off" 1 "Right fog light on" 2 "Left fog light on" 3 "Front fog lights on" ;
VAL_ 1387 IlvAuthorization 0 "False" 1 "True" ;
VAL_ 1387 CafrValidationCommand 0 "Not available" 1 "Available" ;
VAL_ 1387 FrontWiperState 0 "Stopped" 1 "Low speed" 2 "High speed" ;
VAL_ 1387 WashCycleIndicator 0 "No request" 1 "Requested" ;
VAL_ 1387 ManualWipeRequest 0 "No request" 1 "Requested" ;
VAL_ 1387 AutoWipeMode 0 "Inactive" 1 "Active" ;
VAL_ 1387 StlSystemStatus 0 "Invalid" 1 "Active" 2 "Inhibition" 3 "Waiting" 4 "Out of service" 5 "Failure detected" 7 "Invalid" ;
VAL_ 1390 FreewheelingAuthorizationBsi 0 "Not allowed" 1 "Allowed" ;
VAL_ 1390 AcceleratorPedalPosition 255 "Not_available" ;
VAL_ 1390 ElectricCompressorCurrent 511 "Not_available" ;
VAL_ 1390 BrakeSwitch2StuckPressedFault 0 "No fault" 1 "Fault" ;
VAL_ 1390 BrakeSwitch2StuckReleasedFault 0 "No fault" 1 "Fault" ;
VAL_ 1390 BrakeSwitch1StuckPressedFault 0 "No fault" 1 "Fault" ;
VAL_ 1390 BrakeSwitch1StuckReleasedFault 0 "No fault" 1 "Fault" ;
VAL_ 1390 BrakeDiagReleasedWindowReached 0 "Diagnostic window conditions not met" 1 "Diagnostic window entered" ;
VAL_ 1390 CmmDynamicModeSetpoint 0 "Normal" 1 "Sport" 2 "Eco" 3 "Snow" ;
VAL_ 1390 BrakeDiagPressedWindowReached 0 "Diagnostic window conditions not met" 1 "Diagnostic window entered" ;
VAL_ 1390 HybridModeSetpoint 0 "EAWD" 1 "Sport" 2 "Automatic" 3 "ZEV" ;
VAL_ 1390 DaynightStatus 0 "Day state" 1 "Night state" ;
VAL_ 1394 DmtrBatteryCurrent 255 "Not_available" ;
VAL_ 1394 GeiNeedsGroup3 1 "Need number 6" 2 "Need item 7" 4 "Need number 8" 8 "Need number 9" 16 "Need no. 10 (QRDB GEI)" 32 "Need number 11" 64 "Need number 12" 128 "Need number 13" ;
VAL_ 1394 GeiNeedsGroup2 1 "City Park need level" 2 "Final factory need" 4 "Ground-link safety need" 8 "Need for QRDB GEI 1" 16 "GEI need, number 2" 32 "GEI need, number 3" 64 "Need number 4" 128 "GEI need, number 5" ;
VAL_ 1394 GeiNeedsGroup1 1 "Low beams alone need" 2 "High beam lights need" 4 "Cabin air blower need" 8 "FSE need" 16 "Windshield wiping need" 32 "Windshield washing need" 64 "Engine fan need for AC need" 128 "Electrical component durability need" ;
VAL_ 1394 AfsFunctionState 0 "Off" 1 "Pedestrian area light (DAG)" 2 "Pedestrian area light (DAD)" 3 "Town light" 4 "Adverse weather light (DAG)" 5 "Adverse weather light DAD" 6 "Country light" 7 "Motorway" 8 "Tourist mode" 9 "Invalid" 10 "Invalid" 11 "Invalid" 12 "Invalid" 13 "Invalid" 14 "Invalid" 15 "Invalid" ;
VAL_ 1394 BatteryRestartPredictedVoltage 2047 "Not_available" ;
VAL_ 1394 EngineStopImpactScreenInhibit 0 "No crash" 1 "Crash" ;
VAL_ 1394 StubbedSignal1 0 "Plug at '0' (used as stubbed value)" ;
VAL_ 1394 BatteryVoltageSensorFault 0 "No fault" 1 "Fault" ;
VAL_ 1394 BatteryTemperatureCalcFault 0 "No fault" 1 "Fault" ;
VAL_ 1394 BatteryCurrentSensorFault 0 "No fault" 1 "Fault" ;
VAL_ 1394 VehicleConfigurationState 0 "Fitting" 1 "Factory" 2 "Check" 3 "Storage / transport" 4 "Customer (normal)" 5 "After-sales" 6 "Showroom mode" 7 "Invalid" ;
VAL_ 1394 PassengerAirbagInhibitionStatus 0 "Passenger airbag inhibited: warning light on requested" 1 "Passenger airbag active: warning light off requested" ;
VAL_ 1394 ReverseStatus 0 "Reverse not engaged" 1 "Reverse engaged" ;
VAL_ 1394 PowertrainStateCabinSide 0 "Engine not running" 1 "Engine start in progress" 2 "Engine running" 3 "Engine stopped (Stop & Start stop phase)" ;
VAL_ 1394 BeltBucklePassenger 0 "Unspecified" 1 "Seatbelt not buckled" 2 "Seatbelt buckled" 3 "Invalid" ;
VAL_ 1394 BeltBuckleDriver 0 "Unspecified" 1 "Seatbelt not buckled" 2 "Seatbelt buckled" 3 "Invalid" ;
VAL_ 1411 HvBatteryVoltageProbeCount 255 "Not_available" ;
VAL_ 1411 HvBatteryTemperatureProbeCount 255 "Not_available" ;
VAL_ 1411 HvBatteryContactorUncomma_ee926c 0 "No error" 1 "Crash" 2 "Supply voltage too low" 3 "Supply voltage too high" 4 "Battery temperature too high" 5 "Interlock line open" 6 "e-Service plug disconnected" 7 "Invalid" ;
VAL_ 1411 HvBatteryOverchargeAlert 0 "Nominal" 1 "Vehicle energy storage system overload warning" ;
VAL_ 1411 HvBatteryCellConsistencyAlert 0 "Nominal" 1 "Cell consistency alert" ;
VAL_ 1411 HvBatterySocJumpAlert 0 "Nominal" 1 "Significant SOC variation alert" ;
VAL_ 1411 HvBatteryCellUndervoltageAlert 0 "Nominal" 1 "Battery cell undervoltage alert" ;
VAL_ 1411 HvBatteryCellOvervoltageAlert 0 "Nominal" 1 "Battery cell overvoltage alert" ;
VAL_ 1411 HvBatteryHighSocAlert 0 "Nominal" 1 "SOC high level alert exceeded" ;
VAL_ 1411 HvBatteryLowSocAlert 0 "Nominal" 1 "Low state-of-charge alert" ;
VAL_ 1411 HvBatteryOvervoltageAlert 0 "Nominal" 1 "Vehicle energy storage system overvoltage alert" ;
VAL_ 1411 HvBatteryHighTemperatureAlert 0 "Nominal" 1 "High battery temperature alert" ;
VAL_ 1411 HvBatteryTemperatureDiffe_70ad26 0 "Nominal" 1 "Temperature difference alert" ;
VAL_ 1411 HvBatteryInconsistentAlert 0 "Nominal" 1 "Energy storage charging system alert" ;
VAL_ 1411 HvBatteryTemperatureMin 255 "Not_available" ;
VAL_ 1411 HvBatteryProbeNumberTempMin 255 "Not_available" ;
VAL_ 1411 HvBatteryProbeNumberTempMax 255 "Not_available" ;
VAL_ 1416 LifeSituation 0 "SVV1" 1 "SVV2" 2 "SVV3" 3 "SVV4" 4 "SVV5" 5 "SVV6" 6 "SVV7" 7 "SVV8" ;
VAL_ 1416 GearChangeDirection 0 "No change" 1 "Upshift" 2 "Downshift" 3 "Gear change OK" ;
VAL_ 1416 GearboxTargetRatioTransmitted 0 "No change" 1 "7" 2 "6" 3 "5" 4 "4" 5 "3" 6 "2" ;
VAL_ 1416 EngineOperatingMode 0 "Rated operation" 1 "Torque limitation active, limit not reached" 2 "Torque limitation, limit reached" 3 "Engine-speed limitation, limit not reached" 4 "Engine speed limitation, limit reached" 5 "Severe engine-speed limitation, limit not reached" 6 "Severe engine speed limitation, limit reached" ;
VAL_ 1416 AdditivePumpControlEnabled 0 "Control forbidden" 1 "Control authorized" ;
VAL_ 1416 DmtcChargeState 0 "DMTC in preparation" 1 "DMTC ready" ;
VAL_ 1416 DeferredStopSyncInfo 0 "No delayed stop" 1 "Stop delayed" ;
VAL_ 1416 CmmReadinessCodeStatus 0 "Readiness-code diagnostics finished" 1 "Readiness code diagnosis not finished" ;
VAL_ 1416 StopStartFunctionState 0 "STT disabled by outside temperature" 1 "STT active" 2 "Stop & Start deactivated" 3 "STT in fault" ;
VAL_ 1416 AtmosphericPressure 31 "Not_available" ;
VAL_ 1416 EcmSafetyFault 0 "No ECM safety fault" 1 "ECM safety fault" ;
VAL_ 1416 OilPressureAlertLamp 0 "No oil pressure warning" 1 "Engine oil pressure warning" ;
VAL_ 1416 NeutralDisplayRequestGsi 0 "No request" 1 "Neutral request" ;
VAL_ 1416 ValvetronicPowerCommand 0 "No Valvetronic power command" 1 "Valvetronic power command" ;
VAL_ 1416 WaterPumpState 0 "Water pump clutch released" 1 "Water pump clutch engaged" ;
VAL_ 1416 RedLedRequest 0 "No LED lighting request" 1 "Request to light orange LED" ;
VAL_ 1416 OrangeLedRequest 0 "No LED lighting request" 1 "Request to light orange LED" ;
VAL_ 1416 ClutchDisplayRequest 0 "No request" 1 "Requested" ;
VAL_ 1416 StopStartAvailableBlinkRequest 0 "No flashing request" 1 "Flashing request" ;
VAL_ 1416 AdditiveVolumeToAdd 255 "Not_available" ;
VAL_ 1416 EngineOilLevel 255 "Not_available" ;
VAL_ 1422 LeftBlownAirTemperature 65535 "Not_available" ;
VAL_ 1422 RightBlownAirTemperature 65535 "Not_available" ;
VAL_ 1422 RearLeftBlownAirTemperature 65535 "Not_available" ;
VAL_ 1422 RearRightBlownAirTemperature 65535 "Not_available" ;
VAL_ 1430 ConditionalSpeedSignType 0 "Speed limit area" 1 "End of speed limit area" 2 "Invalid" 3 "Not defined" ;
VAL_ 1430 CameraImplicitSpeedRobustFlag 0 "Not robust" 1 "Robust" ;
VAL_ 1430 CameraConditionalSpeedRobustFlag 0 "Not robust" 1 "Robust" ;
VAL_ 1430 ImplicitSpeedLimitType 1 "Entering a shared (traffic-calmed) zone" 2 "Exiting a meeting/encounter area" 3 "Entering built-up area" 4 "Town exit" 5 "Motorway entrance" 6 "Motorway exit" 7 "Motorway entry" 8 "Motorway exit" 15 "Invalid" ;
VAL_ 1430 ConditionalSpeedLimitContext 1 "Trailer or caravan" 2 "Rain" 3 "Snow" 4 "School" 5 "Hours" 6 "Noise" 7 "Length" 14 "Unspecified" 15 "Invalid" ;
VAL_ 1432 CatalystHeaterDiagEnable 0 "0: Disabling diagnosis of the catalyst heater shift strategy" 1 "Enabling diagnosis of the catalyst heater" ;
VAL_ 1432 FuelFlapOpenAuthorized 0 "Not allowed" 1 "Allowed" ;
VAL_ 1432 CoolantTempSensorDiag 0 "No engine coolant temperature sensor fault" 1 "Invalid engine coolant temperature sensor" 2 "Engine coolant temperature sensor short-circuited to ground" 3 "Engine coolant temperature sensor open circuit" ;
VAL_ 1432 AtmosphericPressureHighAltitude 31 "Not_available" ;
VAL_ 1442 PreconditioningState 0 "Preconditioning ON" 1 "Preconditioning OFF" ;
VAL_ 1442 HvBatteryChargeRemainingTime 127 "Not_available" ;
VAL_ 1442 ChargePushButtonPressed 0 "Switch off" 1 "Pressed" ;
VAL_ 1442 ChillerActivationRequest 0 "No request" 1 "Requested" ;
VAL_ 1442 BatteryShortLoopCoolantTe_a7250e 255 "Not_available" ;
VAL_ 1442 HvBatteryCoolantTemperature 255 "Not_available" ;
VAL_ 1443 MinCellVoltage 16383 "Not_available" ;
VAL_ 1443 MinVoltageCellIndexCandidate 255 "Not_available" ;
VAL_ 1443 MaxCellVoltage 16383 "Not_available" ;
VAL_ 1443 MaxVoltageCellIndexCandidate 255 "Not_available" ;
VAL_ 1443 BatteryInsulationResistance 65535 "Not_available" ;
VAL_ 1454 SpeedLimiterCruiseSetpointPlus 0 "Command not activated" 1 "Setpoint decrement" ;
VAL_ 1454 SpeedLimiterCruiseSetpointMinus 0 "Command not activated" 1 "Setpoint decrement" ;
VAL_ 1454 SpeedLimiterSelectButtonState 0 "Command not activated" 1 "Command activated" ;
VAL_ 1454 SpeedLimiterCruiseDeselectButton 0 "Not pressed" 1 "Pressed" ;
VAL_ 1454 EngineCoolantLevelWarning 0 "No alert" 1 "Alert" ;
VAL_ 1454 CompressorCapacityControlDiag 0 "Undetermined" 1 "No fault detected" 2 "Short circuit to ground" 3 "Short circuit to +BAT" 4 "OC (over-current)" 5 "Failure detected" ;
VAL_ 1454 LeftLowBeamDiag 0 "Unspecified" 1 "No fault detected" 2 "Failure detected" ;
VAL_ 1454 RightLowBeamDiag 0 "Unspecified" 1 "No fault detected" 2 "Failure detected" ;
VAL_ 1454 AutomaticEcallTrigger 0 "Airbag ECU unable to detect a crash" 1 "No request to send an auto eCall" 2 "Request to send an automatic eCall" ;
VAL_ 1454 AcCompressorDiag 0 "Undetermined" 1 "No fault detected" 2 "Short circuit to ground" 3 "Short circuit to +BAT" 4 "OC (over-current)" 5 "Failure detected" ;
VAL_ 1454 FrontBlowerMotorFault 0 "Fault absent" 1 "Fault present" ;
VAL_ 1454 RearLeftBlowerMotorFault 0 "Fault absent" 1 "Fault present" ;
VAL_ 1454 EvaporatorSensorTemperature 65535 "Not_available" ;
VAL_ 1458 OutsideTempSensorDiag 0 "No fault on the outside temperature sensor" 2 "Outside temperature sensor short-circuited" 3 "External temperature sensor open circuit" ;
VAL_ 1458 ServiceResetOk 0 "No oil-change reset" 1 "Oil change reset detected" ;
VAL_ 1458 EobdInfoStatusBsi 0 "No network fault" 1 "Not entered in the ACCESS database" 2 "LIN network failure" 4 "Communication fault with the ECU on the LIN network" 8 "MIL warning lamp network fault" 16 "CAN LS CAR network fault" 32 "ADDGO or body VAN bus 2 network fault" 64 "VAN body network 1 or BSM failure" 128 "CMB or VAN CONF network fault" ;
VAL_ 1458 AdditiveSystemStatus 0 "All at zero (additive dosing impossible, no fault)" 1 "Tank filler cap sensor fault" 2 "Fuel gauge fault" 4 "Additive (cerium) level sensor fault" 8 "Downstream DPF temperature sensor fault (if sensor present)" 16 "Additive calculator fault" 32 "Additive injector at fault (if the actuator is present)" 64 "Additive pump faulty" 128 "Addition possible" ;
VAL_ 1458 OutsideAirTemperature 255 "Not_available" ;
VAL_ 1458 TotalAdditiveQuantity 65535 "Not_available" ;
VAL_ 1473 EpsModeRequest 0 "Off" 1 "Drive active" 2 "discharge" 3 "PI charge" 4 "PI balance" 5 "PI discharge" ;
VAL_ 1473 PemHvVoltage 31 "Not_available" ;
VAL_ 1473 TractionStatorTemperature 255 "Not_available" ;
VAL_ 1473 TractionInverterTemperature 255 "Not_available" ;
VAL_ 1473 RemStatorTemperature 255 "Not_available" ;
VAL_ 1473 RemInverterTemperature 255 "Not_available" ;
VAL_ 1475 HvBatteryMinVoltageWarning 0 "No alert" 1 "SAFETY threshold warning, battery voltage" ;
VAL_ 1475 HvBatteryInsulationFaultStatus 0 "No fault" 1 "Symmetry fault" 2 "Asymmetric HV+ fault" 3 "Asymmetric high-voltage fault -" 4 "Invalid" ;
VAL_ 1475 DcdcOvertemperature 0 "False" 1 "Overheating" ;
VAL_ 1475 HvBatteryInterlockLineStatus 0 "No error (interlock line closed)" 1 "Error detected (interlock line open)" 2 "Invalid (interlock line undefined)" ;
VAL_ 1475 RemOvertemperatureFault 0 "No failure" 1 "Overheating" ;
VAL_ 1475 BatterySoc 1023 "Not_available" ;
VAL_ 1475 BatteryVoltage 2047 "Not_available" ;
VAL_ 1483 PartialWakeupStatusFlagsP_c242fd 0 "Initial value" 1 "Gearbox GEP start preparation wake-up status" 2 "Stop & Start start preparation wake-up status with AR2S (type C3)" 4 "Ucaps charge/discharge wake-up status" 8 "Overload vehicle indicator wake-up status" 16 "Mechatronic headlamp wake-up status" 64 "Anti-theft wake-up status" 128 "Engine start preparation wake-up status" 512 "Wake-up status requesting gearbox status" 2048 "SCR bleed wake-up status" 4096 "Flex-start wake-up status" 8192 "Hybrid power-latch wake-up status" 16384 "Engine oil measurement wake-up status" 32768 "Engine post-ventilation wake-up status" ;
VAL_ 1483 EcuOperatingPhase 0 "Standby (theoretical, never reached)" 1 "Partial or ComLatch" 2 "Internal partial (theoretically unused)" 3 "Transient" 4 "Main" 5 "Degraded main state" 6 "Initialization / falling asleep" 7 "Default value (function absent)" 8 "Pre/Post main state" ;
VAL_ 1483 DiagnosticMemoryState 0 "No fault present" 1 "One or more faults present; each bit gives a fault code" ;
VAL_ 1485 SteeringWheelAngleOffsetAccuracy 63 "Not_available" ;
VAL_ 1485 SteeringWheelAngleOffset 32767 "Not_available" ;
VAL_ 1486 RoadType 0 "Unknown" 1 "Freeway or controlled-access road that is not a ramp or slip road" 2 "Multiple carriageway (or road digitized multiple times)" 3 "Single carriageway" 4 "Roundabout" 5 "Traffic squares / special traffic pattern" 8 "Parallel road (slip road type)" 9 "Slip road/ramp on a motorway or controlled-access road" 10 "Slip road/ramp (not on a motorway or controlled-access road)" 11 "Service road" 12 "Entrance to or exit from a car park" 13 "Entering or exiting a service station" 14 "Pedestrian zone" 15 "Invalid" ;
VAL_ 1486 IndicatorStopPresent 0 "Lamp absent" 1 "Lamp present" ;
VAL_ 1486 ElectricParkingBrakeFaultPresent 0 "Lamp absent" 1 "Lamp present" ;
VAL_ 1486 StartIndicatorPresence 0 "Lamp absent" 1 "Lamp present" ;
VAL_ 1486 LaneCountDrivingDirection 0 "0" 1 "1" 2 "2" 3 "3" 4 "4" 5 "5" 6 "6" 7 "Invalid" ;
VAL_ 1486 IndicatorSamPresent 0 "Lamp absent" 1 "Lamp present" ;
VAL_ 1486 CrashDetectedSinceLastPowerUp 0 "No crash since +APC" 1 "Crash detected since last +APC" ;
VAL_ 1486 IndicatorParkingBrakePresent 0 "Lamp absent" 1 "Lamp present" ;
VAL_ 1486 IndicatorFapPresent 0 "Lamp absent" 1 "Lamp present" ;
VAL_ 1486 IndicatorGasoilWaterPresent 0 "Lamp absent" 1 "Lamp present" ;
VAL_ 1486 DrivingSide 0 "Right (maximum)" 1 "Left" ;
VAL_ 1486 CaarIndicatorPresent 0 "Lamp absent" 1 "Lamp present" ;
VAL_ 1486 IndicatorDaePresent 0 "Lamp absent" 1 "Lamp present" ;
VAL_ 1486 IndicatorEspPresent 0 "Lamp absent" 1 "Lamp present" ;
VAL_ 1506 AcSolenoidValve2Diagnosis 0 "No fault" 1 "Fault" ;
VAL_ 1506 AcSolenoidValve1Diagnosis 0 "No fault" 1 "Fault" ;
VAL_ 1506 MixedModeEcoZevAvailability 0 "Available" 1 "Transiently unavailable" 2 "Permanently unavailable" ;
VAL_ 1506 MixedModeEcoHybridAvailability 0 "Available" 1 "Transiently unavailable" 2 "Permanently unavailable" ;
VAL_ 1506 DriveAxleModeStatus 0 "Automatic axle" 1 "Front" 2 "Rear" 3 "AWD" 4 "Initialisation" ;
VAL_ 1506 DriveAxleModeRequestFeedback 0 "Request accepted" 1 "Request denied" ;
VAL_ 1506 EnergyModeRequestFeedback 0 "Request accepted" 1 "Request denied" ;
VAL_ 1506 EnergyModeStatus 0 "Hybrid" 1 "ZEV" 2 "Fuel" 3 "Initialization" ;
VAL_ 1506 DynamicDriveModeStatus 0 "Normal" 1 "Sport" 2 "Eco" 3 "SNOW" 4 "ECOP" 5 "Initialization" ;
VAL_ 1506 DynamicDriveModeRequestFeedback 0 "Request accepted" 1 "Request denied" ;
VAL_ 1506 DriveModeFeedbackToggleBit 0 "Feedback 0" 1 "Feedback 1" ;
VAL_ 1506 MixedModeNormalZevAvailability 0 "Available" 1 "Transiently unavailable" 2 "Permanently unavailable" ;
VAL_ 1506 AxleModeAwdAvailability 0 "Available" 1 "Transiently unavailable" 2 "Permanently unavailable" ;
VAL_ 1506 AxleModeRearAvailability 0 "Available" 1 "Transiently unavailable" 2 "Permanently unavailable" ;
VAL_ 1506 AxleModeFrontAvailability 0 "Available" 1 "Transiently unavailable" 2 "Permanently unavailable" ;
VAL_ 1506 AxleModeAutoAvailability 0 "Available" 1 "Transiently unavailable" 2 "Permanently unavailable" ;
VAL_ 1506 EnergyModeFuelAvailability 0 "Available" 1 "Transiently unavailable" 2 "Permanently unavailable" ;
VAL_ 1506 EnergyModeZevAvailability 0 "Available" 1 "Transiently unavailable" 2 "Permanently unavailable" ;
VAL_ 1506 EnergyModeHybridAvailability 0 "Available" 1 "Transiently unavailable" 2 "Permanently unavailable" ;
VAL_ 1506 DynamicModeEcoPlusAvailability 0 "Available" 1 "Transiently unavailable" 2 "Permanently unavailable" ;
VAL_ 1506 DynamicModeSnowAvailability 0 "Available" 1 "Transiently unavailable" 2 "Permanently unavailable" ;
VAL_ 1506 DynamicModeEcoAvailability 0 "Available" 1 "Transiently unavailable" 2 "Permanently unavailable" ;
VAL_ 1506 DynamicModeSportAvailability 0 "Available" 1 "Transiently unavailable" 2 "Permanently unavailable" ;
VAL_ 1506 DynamicModeNormalAvailability 0 "Available" 1 "Transiently unavailable" 2 "Permanently unavailable" ;
VAL_ 1515 PartialWakeupStatusFlagsP_c242fd 0 "Initial value" 1 "Gearbox GEP start preparation wake-up status" 2 "Stop & Start start preparation wake-up status with AR2S (type C3)" 4 "Ucaps charge/discharge wake-up status" 8 "Overload vehicle indicator wake-up status" 16 "Mechatronic headlamp wake-up status" 64 "Anti-theft wake-up status" 128 "Engine start preparation wake-up status" 512 "Wake-up status requesting gearbox status" 2048 "SCR bleed wake-up status" 4096 "Flex-start wake-up status" 8192 "Hybrid power-latch wake-up status" 16384 "Engine oil measurement wake-up status" 32768 "Engine post-ventilation wake-up status" ;
VAL_ 1515 EcuOperatingPhase 0 "Standby (theoretical, never reached)" 1 "Partial or ComLatch" 2 "Internal partial (theoretically unused)" 3 "Transient" 4 "Main" 5 "Degraded main state" 6 "Initialization / falling asleep" 7 "Default value (function absent)" 8 "Pre/Post main state" ;
VAL_ 1515 DiagnosticMemoryState 0 "No fault present" 1 "One or more faults present; each bit gives a fault code" ;
VAL_ 1522 DistanceSinceLastSpeedSign 255 "Not_available" ;
VAL_ 1522 SpeedInfoRobustnessFlag 0 "Not robust" 1 "Robust" ;
VAL_ 1522 SpeedSignType 0 "Speed-limit zone" 1 "End of speed-limit zone" 3 "Invalid" ;
VAL_ 1522 CameraReadSpeed 255 "Not_available" ;
VAL_ 1522 CdpStatus 0 "Normal" 1 "Faulty" ;
VAL_ 1522 RainSensorWiperState 0 "Stop" 2 "Low speed" 3 "High speed" ;
VAL_ 1522 WiperSweepSpeed 0 "Speed 0 (low speed)" 1 "Speed 1" 2 "Speed 2" 3 "Speed 3" 4 "Speed 4" 5 "Speed 5" 6 "Speed 6" 7 "Speed 7" 8 "Speed 8" 9 "Speed 9" 10 "Speed 10" 11 "Speed 11" 12 "Speed 12" 13 "Speed 13" 14 "Speed 14" 15 "Speed 15 (HS)" ;
VAL_ 1522 CdlStatus 0 "Normal" 1 "Faulty" ;
VAL_ 1522 AafRequest 0 "No request" 1 "Requested" ;
VAL_ 1522 CafrBrightnessStatus 0 "CAFR brightness not OK" 1 "CAFR brightness OK" ;
VAL_ 1522 CafrFunctionFault 0 "Normal" 1 "Faulty" ;
VAL_ 1522 LowHighBeamSwitchingRequest 0 "Dipped beam position" 1 "High beam position" ;
VAL_ 1522 AbnormalLaneDepartureRight 0 "No abnormal right-hand crossing" 1 "Abnormal right-hand crossing" ;
VAL_ 1522 AbnormalLaneDepartureLeft 0 "No abnormal left-hand crossing" 1 "Abnormal left-hand crossing" ;
VAL_ 1522 StlFaultPresent 0 "No fault detected" 1 "Failure detected" ;
VAL_ 1554 VehicleConfigurationState 0 "Fitting" 1 "Factory" 2 "Check" 3 "Storage / transport" 4 "Customer (normal)" 5 "After-sales" 6 "Showroom mode" 7 "Invalid" ;
VAL_ 1554 RelayR3LineDiagnostic 0 "Unspecified" 1 "No fault / Relay control inactive" 2 "No fault / relay control active" 3 "Short circuit to ground" 4 "Short circuit to +BAT" 5 "OC (over-current)" 6 "Unidentified fault" ;
VAL_ 1554 RelayLineDiagnosticUpdateBit 0 "No change" 1 "Change on at least one signal" ;
VAL_ 1554 RelayR2LineDiagnostic 0 "Unspecified" 1 "No fault / Relay control inactive" 2 "No fault / relay control active" 3 "Short circuit to ground" 4 "Short circuit to +BAT" 5 "OC (over-current)" 6 "Unidentified fault" ;
VAL_ 1554 RelayR1LineDiagnostic 0 "Unspecified" 1 "No fault / Relay control inactive" 2 "No fault / relay control active" 3 "Short circuit to ground" 4 "Short circuit to +BAT" 5 "OC (over-current)" 6 "Unidentified fault" ;
VAL_ 1554 StartingPredictedVoltage 2047 "Not_available" ;
VAL_ 1554 MobileDeflectorPosition 0 "Unspecified" 1 "In position 0" 3 "In position 1" 5 "In position 2" 6 "In maintenance position" ;
VAL_ 1554 OlviRearHmiActivationRequest 0 "No request" 1 "Requested" ;
VAL_ 1554 FuelLevel 255 "Not_available" ;
VAL_ 1554 EcoMode 0 "Initialization value" 1 "No eco mode" 2 "Eco mode requested" 3 "Invalid" ;
VAL_ 1554 AsrPlusModeSelected 0 "Normal mode" 1 "Snow mode" 2 "Mud mode" 3 "Sand mode" ;
VAL_ 1554 HighBeamLeftFault 0 "No fault" 1 "Fault" ;
VAL_ 1554 HighBeamRightFault 0 "No fault" 1 "Fault" ;
VAL_ 1554 LowBeamLeftFault 0 "No fault" 1 "Fault" ;
VAL_ 1554 LowBeamRightFault 0 "No fault" 1 "Fault" ;
VAL_ 1554 LowBeamState 0 "Off" 1 "On" ;
VAL_ 1554 HighBeamState 0 "Off" 1 "On" ;
VAL_ 1554 VehicleConfigurationMode 0 "Factory" 1 "Showroom mode" 2 "Customer (normal)" ;
VAL_ 1554 TurnIndicatorSwitchRequest 0 "Off" 1 "Left indicator" 2 "Right indicator" 3 "Invalid" ;
VAL_ 1554 DynamicCurveLightingInhibit 0 "No inhibition" 1 "Inhibition" ;
VAL_ 1554 MotorwayLightingInhibit 0 "No inhibition" 1 "Inhibition" ;
VAL_ 1554 DynamicLightingDaytimeInhibit 0 "No inhibition" 1 "Inhibition" ;
VAL_ 1922 PrecondThermWupState 0 "No wake-up in progress" 1 "Wake-up ongoing" ;
VAL_ 1922 PrecondElecWupState 0 "No wake-up in progress" 1 "Wake-up ongoing" ;
VAL_ 1922 HoldDiscontactorWupState 0 "No wake-up in progress" 1 "Wake-up ongoing" ;
VAL_ 1922 PostDriveWupState 0 "No wake-up in progress" 1 "Wake-up ongoing" ;
VAL_ 1922 PreDriveWupState 0 "No wake-up in progress" 1 "Wake-up ongoing" ;
VAL_ 1922 CceCoolingWupState 0 "No wake-up in progress" 1 "Wake-up ongoing" ;
VAL_ 1922 MeapCoolingWupState 0 "No wake-up in progress" 1 "Wake-up ongoing" ;
VAL_ 1922 GmvCoolingWupState 0 "No wake-up in progress" 1 "Wake-up ongoing" ;
VAL_ 1922 PiStateInfoWupState 0 "No wake-up in progress" 1 "Wake-up ongoing" ;
VAL_ 1922 StopDelayedHmiWupState 0 "No wake-up in progress" 1 "Wake-up ongoing" ;
VAL_ 1922 HvBattChargeWupState 0 "No wake-up in progress" 1 "Wake-up ongoing" ;
VAL_ 1922 RcdLineStatus2 0 "RCD line at LOW state" 1 "RCD line at HIGH state" ;
VAL_ 1922 EcuElectricalStateRcd 0 "Partial wake-up" 1 "Internal wake-up (transmitted only in special cases)" 2 "Transient" 3 "Main wake-up" 4 "Degraded main wake-up" 5 "Sleep preparation (transmitted only in special cases)" ;
VAL_ 1922 DiagnosticMemoryState2 0 "No fault present" 1 "One or more faults present" ;
VAL_ 1933 RcdLineStatus 0 "RCD line at LOW state" 1 "RCD line at HIGH state" ;
VAL_ 1933 ApcLineStatus 0 "Ignition wake-up line detected inactive" 1 "+APC wake-up line detected active" ;
VAL_ 1933 PartialWakeupStatusFlagsLas 0 "Initial value" 1 "Ride height correction wake-up status" 2 "CAAR manual function wake-up status" 4 "Wake-up: CAAR height status request by the EPB" 8 "Wake-up for Easy Move function by EPB" 16 "Vehicle-speed wake-up by BSI" 32 "Display wake-up triggered by the electric parking brake" 64 "Wake-up requesting FSE (parking brake) status" 128 "Short partial wake-up 1, after main wake-up" ;
VAL_ 1933 EcuOperatingPhase 0 "Standby (theoretical, never reached)" 1 "Partial or ComLatch" 2 "Internal partial (theoretically unused)" 3 "Transient" 4 "Main" 5 "Degraded main state" 6 "Initialization / falling asleep" 7 "Default value (function absent)" 8 "Pre/Post main state" ;
VAL_ 1933 DiagnosticMemoryState 0 "No fault present" 1 "One or more faults present; each bit gives a fault code" ;
VAL_ 1938 RcdLineStatus 0 "RCD line at LOW state" 1 "RCD line at HIGH state" ;
VAL_ 1938 PartialWakeupStatusFlags 0 "Initial value" 1 "GEP start preparation wake-up status" 2 "Stop & Start restart preparation wake-up status" 4 "CAAR manual function wake-up status" 8 "Pneumatic height-correction wake-up status" 16 "Vehicle-speed wake-up status by BSI" 32 "Vehicle speed wake-up status by EPB" 64 "Anti-theft wake-up status" 128 "Engine start preparation wake-up status" 256 "Cabin preconditioning wake-up status" 512 "Wake-up status requesting gearbox status" 1024 "Ride height correction wake-up status" 2048 "Parking brake status request wake-up status" 4096 "BCU wake-up for EPB state display status" 8192 "Remote control (plip) wake-up status" 16384 "Engine oil measurement wake-up status" 32768 "Engine post-ventilation wake-up status" ;
VAL_ 1938 EcuOperatingPhase 0 "Standby (theoretical, never reached)" 1 "Partial or ComLatch" 2 "Internal partial (theoretically unused)" 3 "Transient" 4 "Main" 5 "Degraded main state" 6 "Initialization / falling asleep" 7 "Default value (function absent)" 8 "Pre/Post main state" ;
VAL_ 1938 DiagnosticMemoryState 0 "No fault present" 1 "One or more faults present; each bit gives a fault code" ;
VAL_ 1941 PowerSteeringAssistStatus 0 "Assistance not activated" 1 "Assistance activated, nominal mode" 2 "Assistance activated, degraded mode" 3 "Assistance activated in STTa mode" 4 "Assistance activated in STTd mode" 5 "Assistance activated in Idle & Go mode" 6 "Forbidden value" 7 "Invalid value" ;
VAL_ 1941 ApcLineStatus 0 "Ignition wake-up line detected inactive" 1 "+APC wake-up line detected active" ;
VAL_ 1941 DiagnosticMemoryState 0 "No fault present" 1 "One or more faults present; each bit gives a fault code" ;
VAL_ 1946 PartialWakeupStatusFlagsP_c242fd 0 "Initial value" 1 "Gearbox GEP start preparation wake-up status" 2 "Stop & Start start preparation wake-up status with AR2S (type C3)" 4 "Ucaps charge/discharge wake-up status" 8 "Overload vehicle indicator wake-up status" 16 "Mechatronic headlamp wake-up status" 64 "Anti-theft wake-up status" 128 "Engine start preparation wake-up status" 512 "Wake-up status requesting gearbox status" 2048 "SCR bleed wake-up status" 4096 "Flex-start wake-up status" 8192 "Hybrid power-latch wake-up status" 16384 "Engine oil measurement wake-up status" 32768 "Engine post-ventilation wake-up status" ;
VAL_ 1946 EcuElectricalStateApc 1 "Internal wake-up (transmitted only in special cases)" 2 "Comlatch" 3 "Main wake-up" 5 "Sleep preparation (transmitted only in special cases)" ;
VAL_ 1946 DiagnosticMemoryState 0 "No fault present" 1 "One or more faults present; each bit gives a fault code" ;
SG_MUL_VAL_ 1370 BatteryVoltageSeq1 LvBatterySequenceId 0-0;
SG_MUL_VAL_ 1370 BatteryVoltageSeq4 LvBatterySequenceId 1-1;
SG_MUL_VAL_ 1370 BatteryResistanceSeq1 LvBatterySequenceId 0-0;
SG_MUL_VAL_ 1370 BatteryResistanceSeq4 LvBatterySequenceId 1-1;
